VERSION ""

NS_ :

BS_:

BU_: Turbocharger OnBoardDataLogger OffBoardDiagnosticTool2 OffBoardDiagnosticTool1 FileServer ParkingBrakeController SeatControl2 FanDriveController SteeringColumnUnit CommunicationUnitRadio CommunicationUnitSatellite CommunicationUnitCellular PropulsionBatteryCharger ChassisController2 ChassisController1 EngineValveControl AuxiliaryHeater2 AuxiliaryHeater1 ClutchUnit RampControl InformationSystem1 SuspensionSystemController2 OilSensor VehicleDynamicStability ExhaustEmissionController TransmissionDisplay2 TransmissionDisplay1 ClimateControl2 WaterPumpController RearAxleSteeringController LightingOperatorControl SeatController1 IgnitionController2 IgnitionController1 TirePressureController CabController2 CabController1 PneumaticSystemController SuspensionSystemController1 HydraulicPumpController EnduranceBrakingSystem RetarderExhaustEngine2 OnBoardDiagnosticUnit HeadwayController RetarderExhaustEngine1 CabDisplay1 ManagementComputer VirtualTerminal OffVehicleGateway PowerTakeOffFront HitchControl AuxiliaryValveControl BodyController TractorTrailerBridge1 StarterSystem ElectricalSystem VehicleSecurity VehicleNavigation AerodynamicControl ElectricalChargingSystem ClimateControl1 TripRecorder InstrumentCluster SuspensionDriveAxle2 SuspensionDriveAxle1 SuspensionSteerAxle SteeringController FuelSystem CruiseControl RetarderDriveline RetarderEngine BrakesDriveAxle2 BrakesDriveAxle1 BrakesSystemController BrakesSteerAxle AxleDrive2 AxleDrive1 AxleSteering PowerTakeOff ShiftConsoleSecondary ShiftConsolePrimary Transmission2 Transmission1 Engine2 Engine1

BO_ 2566844705 CCVS_SA_21: 8 Vector__XXX
 SG_ ParkBrakeReleaseInhibitRq : 6|2@1+ (1,0) [0|3] "" Vector__XXX
 SG_ PTOGovernorState : 48|5@1+ (1,0) [0|31] "" Vector__XXX
 SG_ EngShutdownOverrideSwitch : 62|2@1+ (1,0) [0|3] "" Vector__XXX
 SG_ EngTestModeSwitch : 60|2@1+ (1,0) [0|3] "" Vector__XXX
 SG_ EngIdleDecrementSwitch : 58|2@1+ (1,0) [0|3] "" Vector__XXX
 SG_ EngIdleIncrementSwitch : 56|2@1+ (1,0) [0|3] "" Vector__XXX
 SG_ CruiseCtrlStates : 53|3@1+ (1,0) [0|7] "" Vector__XXX
 SG_ CruiseCtrlSetSpeed : 40|8@1+ (1,0) [0|250] "km/h" Vector__XXX
 SG_ CruiseCtrlAccelerateSwitch : 38|2@1+ (1,0) [0|3] "" Vector__XXX
 SG_ CruiseCtrlResumeSwitch : 36|2@1+ (1,0) [0|3] "" Vector__XXX
 SG_ CruiseCtrlCoastSwitch : 34|2@1+ (1,0) [0|3] "" Vector__XXX
 SG_ CruiseCtrlSetSwitch : 32|2@1+ (1,0) [0|3] "" Vector__XXX
 SG_ ClutchSwitch : 30|2@1+ (1,0) [0|3] "" Vector__XXX
 SG_ BrakeSwitch_SA21 : 28|2@1+ (1,0) [0|3] "" Vector__XXX
 SG_ CruiseCtrlEnableSwitch : 26|2@1+ (1,0) [0|3] "" Vector__XXX
 SG_ CruiseCtrlActive : 24|2@1+ (1,0) [0|3] "" Vector__XXX
 SG_ WheelBasedVehicleSpeed : 8|16@1+ (0.00390625,0) [0|250.996] "km/h" Vector__XXX
 SG_ CruiseCtrlPauseSwitch : 4|2@1+ (1,0) [0|3] "" Vector__XXX
 SG_ ParkingBrakeSwitch : 2|2@1+ (1,0) [0|3] "" Vector__XXX
 SG_ TwoSpeedAxleSwitch : 0|2@1+ (1,0) [0|3] "" Vector__XXX

BO_ 2566844695 CCVS_SA_17: 8 Vector__XXX
 SG_ ParkBrakeReleaseInhibitRq : 6|2@1+ (1,0) [0|3] "" Vector__XXX
 SG_ PTOGovernorState : 48|5@1+ (1,0) [0|31] "" Vector__XXX
 SG_ EngShutdownOverrideSwitch : 62|2@1+ (1,0) [0|3] "" Vector__XXX
 SG_ EngTestModeSwitch : 60|2@1+ (1,0) [0|3] "" Vector__XXX
 SG_ EngIdleDecrementSwitch : 58|2@1+ (1,0) [0|3] "" Vector__XXX
 SG_ EngIdleIncrementSwitch : 56|2@1+ (1,0) [0|3] "" Vector__XXX
 SG_ CruiseCtrlStates : 53|3@1+ (1,0) [0|7] "" Vector__XXX
 SG_ CruiseCtrlSetSpeed : 40|8@1+ (1,0) [0|250] "km/h" Vector__XXX
 SG_ CruiseCtrlAccelerateSwitch : 38|2@1+ (1,0) [0|3] "" Vector__XXX
 SG_ CruiseCtrlResumeSwitch : 36|2@1+ (1,0) [0|3] "" Vector__XXX
 SG_ CruiseCtrlCoastSwitch : 34|2@1+ (1,0) [0|3] "" Vector__XXX
 SG_ CruiseCtrlSetSwitch : 32|2@1+ (1,0) [0|3] "" Vector__XXX
 SG_ ClutchSwitch : 30|2@1+ (1,0) [0|3] "" Vector__XXX
 SG_ BrakeSwitch_SA17 : 28|2@1+ (1,0) [0|3] "" Vector__XXX
 SG_ CruiseCtrlEnableSwitch : 26|2@1+ (1,0) [0|3] "" Vector__XXX
 SG_ CruiseCtrlActive : 24|2@1+ (1,0) [0|3] "" Vector__XXX
 SG_ WheelBasedVehicleSpeed : 8|16@1+ (0.00390625,0) [0|250.996] "km/h" Vector__XXX
 SG_ CruiseCtrlPauseSwitch : 4|2@1+ (1,0) [0|3] "" Vector__XXX
 SG_ ParkingBrakeSwitch : 2|2@1+ (1,0) [0|3] "" Vector__XXX
 SG_ TwoSpeedAxleSwitch : 0|2@1+ (1,0) [0|3] "" Vector__XXX

BO_ 2566844689 CCVS_SA_11: 8 Vector__XXX
 SG_ ParkBrakeReleaseInhibitRq : 6|2@1+ (1,0) [0|3] "" Vector__XXX
 SG_ PTOGovernorState : 48|5@1+ (1,0) [0|31] "" Vector__XXX
 SG_ EngShutdownOverrideSwitch : 62|2@1+ (1,0) [0|3] "" Vector__XXX
 SG_ EngTestModeSwitch : 60|2@1+ (1,0) [0|3] "" Vector__XXX
 SG_ EngIdleDecrementSwitch : 58|2@1+ (1,0) [0|3] "" Vector__XXX
 SG_ EngIdleIncrementSwitch : 56|2@1+ (1,0) [0|3] "" Vector__XXX
 SG_ CruiseCtrlStates : 53|3@1+ (1,0) [0|7] "" Vector__XXX
 SG_ CruiseCtrlSetSpeed : 40|8@1+ (1,0) [0|250] "km/h" Vector__XXX
 SG_ CruiseCtrlAccelerateSwitch : 38|2@1+ (1,0) [0|3] "" Vector__XXX
 SG_ CruiseCtrlResumeSwitch : 36|2@1+ (1,0) [0|3] "" Vector__XXX
 SG_ CruiseCtrlCoastSwitch : 34|2@1+ (1,0) [0|3] "" Vector__XXX
 SG_ CruiseCtrlSetSwitch : 32|2@1+ (1,0) [0|3] "" Vector__XXX
 SG_ ClutchSwitch : 30|2@1+ (1,0) [0|3] "" Vector__XXX
 SG_ BrakeSwitch_SA11 : 28|2@1+ (1,0) [0|3] "" Vector__XXX
 SG_ CruiseCtrlEnableSwitch : 26|2@1+ (1,0) [0|3] "" Vector__XXX
 SG_ CruiseCtrlActive : 24|2@1+ (1,0) [0|3] "" Vector__XXX
 SG_ WheelBasedVehicleSpeed : 8|16@1+ (0.00390625,0) [0|250.996] "km/h" Vector__XXX
 SG_ CruiseCtrlPauseSwitch : 4|2@1+ (1,0) [0|3] "" Vector__XXX
 SG_ ParkingBrakeSwitch : 2|2@1+ (1,0) [0|3] "" Vector__XXX
 SG_ TwoSpeedAxleSwitch : 0|2@1+ (1,0) [0|3] "" Vector__XXX

BO_ 2566844683 CCVS_SA_0B: 8 Vector__XXX
 SG_ ParkBrakeReleaseInhibitRq : 6|2@1+ (1,0) [0|3] "" Vector__XXX
 SG_ PTOGovernorState : 48|5@1+ (1,0) [0|31] "" Vector__XXX
 SG_ EngShutdownOverrideSwitch : 62|2@1+ (1,0) [0|3] "" Vector__XXX
 SG_ EngTestModeSwitch : 60|2@1+ (1,0) [0|3] "" Vector__XXX
 SG_ EngIdleDecrementSwitch : 58|2@1+ (1,0) [0|3] "" Vector__XXX
 SG_ EngIdleIncrementSwitch : 56|2@1+ (1,0) [0|3] "" Vector__XXX
 SG_ CruiseCtrlStates : 53|3@1+ (1,0) [0|7] "" Vector__XXX
 SG_ CruiseCtrlSetSpeed : 40|8@1+ (1,0) [0|250] "km/h" Vector__XXX
 SG_ CruiseCtrlAccelerateSwitch : 38|2@1+ (1,0) [0|3] "" Vector__XXX
 SG_ CruiseCtrlResumeSwitch : 36|2@1+ (1,0) [0|3] "" Vector__XXX
 SG_ CruiseCtrlCoastSwitch : 34|2@1+ (1,0) [0|3] "" Vector__XXX
 SG_ CruiseCtrlSetSwitch : 32|2@1+ (1,0) [0|3] "" Vector__XXX
 SG_ ClutchSwitch : 30|2@1+ (1,0) [0|3] "" Vector__XXX
 SG_ BrakeSwitch_SA0B : 28|2@1+ (1,0) [0|3] "" Vector__XXX
 SG_ CruiseCtrlEnableSwitch : 26|2@1+ (1,0) [0|3] "" Vector__XXX
 SG_ CruiseCtrlActive : 24|2@1+ (1,0) [0|3] "" Vector__XXX
 SG_ WheelBasedVehicleSpeed : 8|16@1+ (0.00390625,0) [0|250.996] "km/h" Vector__XXX
 SG_ CruiseCtrlPauseSwitch : 4|2@1+ (1,0) [0|3] "" Vector__XXX
 SG_ ParkingBrakeSwitch : 2|2@1+ (1,0) [0|3] "" Vector__XXX
 SG_ TwoSpeedAxleSwitch : 0|2@1+ (1,0) [0|3] "" Vector__XXX

BO_ 2566844672 CCVS_SA_00: 8 Vector__XXX
 SG_ ParkBrakeReleaseInhibitRq : 6|2@1+ (1,0) [0|3] "" Vector__XXX
 SG_ PTOGovernorState : 48|5@1+ (1,0) [0|31] "" Vector__XXX
 SG_ EngShutdownOverrideSwitch : 62|2@1+ (1,0) [0|3] "" Vector__XXX
 SG_ EngTestModeSwitch : 60|2@1+ (1,0) [0|3] "" Vector__XXX
 SG_ EngIdleDecrementSwitch : 58|2@1+ (1,0) [0|3] "" Vector__XXX
 SG_ EngIdleIncrementSwitch : 56|2@1+ (1,0) [0|3] "" Vector__XXX
 SG_ CruiseCtrlStates : 53|3@1+ (1,0) [0|7] "" Vector__XXX
 SG_ CruiseCtrlSetSpeed : 40|8@1+ (1,0) [0|250] "km/h" Vector__XXX
 SG_ CruiseCtrlAccelerateSwitch : 38|2@1+ (1,0) [0|3] "" Vector__XXX
 SG_ CruiseCtrlResumeSwitch : 36|2@1+ (1,0) [0|3] "" Vector__XXX
 SG_ CruiseCtrlCoastSwitch : 34|2@1+ (1,0) [0|3] "" Vector__XXX
 SG_ CruiseCtrlSetSwitch : 32|2@1+ (1,0) [0|3] "" Vector__XXX
 SG_ ClutchSwitch : 30|2@1+ (1,0) [0|3] "" Vector__XXX
 SG_ BrakeSwitch_SA00 : 28|2@1+ (1,0) [0|3] "" Vector__XXX
 SG_ CruiseCtrlEnableSwitch : 26|2@1+ (1,0) [0|3] "" Vector__XXX
 SG_ CruiseCtrlActive : 24|2@1+ (1,0) [0|3] "" Vector__XXX
 SG_ WheelBasedVehicleSpeed : 8|16@1+ (0.00390625,0) [0|250.996] "km/h" Vector__XXX
 SG_ CruiseCtrlPauseSwitch : 4|2@1+ (1,0) [0|3] "" Vector__XXX
 SG_ ParkingBrakeSwitch : 2|2@1+ (1,0) [0|3] "" Vector__XXX
 SG_ TwoSpeedAxleSwitch : 0|2@1+ (1,0) [0|3] "" Vector__XXX

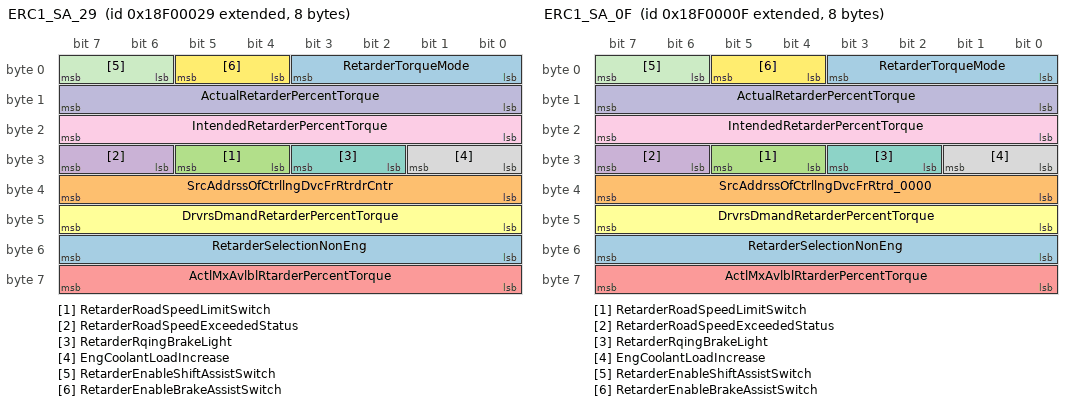
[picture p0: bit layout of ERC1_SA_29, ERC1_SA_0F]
BO_ 2565865513 ERC1_SA_29: 8 Vector__XXX
 SG_ RetarderSelectionNonEng : 48|8@1+ (0.4,0) [0|100] "%" Vector__XXX
 SG_ SrcAddrssOfCtrllngDvcFrRtrdrCntr : 32|8@1+ (1,0) [0|255] "" Vector__XXX
 SG_ RetarderRoadSpeedLimitSwitch : 28|2@1+ (1,0) [0|3] "" Vector__XXX
 SG_ RetarderRoadSpeedExceededStatus : 30|2@1+ (1,0) [0|3] "" Vector__XXX
 SG_ ActlMxAvlblRtarderPercentTorque : 56|8@1+ (1,-125) [-125|125] "%" Vector__XXX
 SG_ DrvrsDmandRetarderPercentTorque : 40|8@1+ (1,-125) [-125|125] "%" Vector__XXX
 SG_ RetarderRqingBrakeLight : 26|2@1+ (1,0) [0|3] "" Vector__XXX
 SG_ EngCoolantLoadIncrease : 24|2@1+ (1,0) [0|3] "" Vector__XXX
 SG_ IntendedRetarderPercentTorque : 16|8@1+ (1,-125) [-125|125] "%" Vector__XXX
 SG_ ActualRetarderPercentTorque : 8|8@1+ (1,-125) [-125|125] "%" Vector__XXX
 SG_ RetarderEnableShiftAssistSwitch : 6|2@1+ (1,0) [0|3] "" Vector__XXX
 SG_ RetarderEnableBrakeAssistSwitch : 4|2@1+ (1,0) [0|3] "" Vector__XXX
 SG_ RetarderTorqueMode : 0|4@1+ (1,0) [0|15] "" Vector__XXX

BO_ 2565865487 ERC1_SA_0F: 8 Vector__XXX
 SG_ RetarderSelectionNonEng : 48|8@1+ (0.4,0) [0|100] "%" Vector__XXX
 SG_ SrcAddrssOfCtrllngDvcFrRtrd_0000 : 32|8@1+ (1,0) [0|255] "" Vector__XXX
 SG_ RetarderRoadSpeedLimitSwitch : 28|2@1+ (1,0) [0|3] "" Vector__XXX
 SG_ RetarderRoadSpeedExceededStatus : 30|2@1+ (1,0) [0|3] "" Vector__XXX
 SG_ ActlMxAvlblRtarderPercentTorque : 56|8@1+ (1,-125) [-125|125] "%" Vector__XXX
 SG_ DrvrsDmandRetarderPercentTorque : 40|8@1+ (1,-125) [-125|125] "%" Vector__XXX
 SG_ RetarderRqingBrakeLight : 26|2@1+ (1,0) [0|3] "" Vector__XXX
 SG_ EngCoolantLoadIncrease : 24|2@1+ (1,0) [0|3] "" Vector__XXX
 SG_ IntendedRetarderPercentTorque : 16|8@1+ (1,-125) [-125|125] "%" Vector__XXX
 SG_ ActualRetarderPercentTorque : 8|8@1+ (1,-125) [-125|125] "%" Vector__XXX
 SG_ RetarderEnableShiftAssistSwitch : 6|2@1+ (1,0) [0|3] "" Vector__XXX
 SG_ RetarderEnableBrakeAssistSwitch : 4|2@1+ (1,0) [0|3] "" Vector__XXX
 SG_ RetarderTorqueMode : 0|4@1+ (1,0) [0|15] "" Vector__XXX

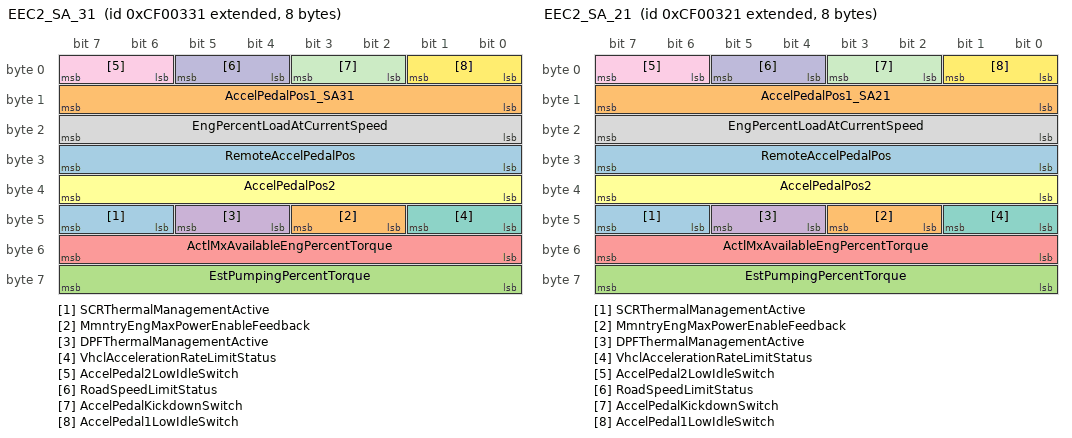
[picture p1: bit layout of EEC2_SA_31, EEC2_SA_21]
BO_ 2364539697 EEC2_SA_31: 8 Vector__XXX
 SG_ SCRThermalManagementActive : 46|2@1+ (1,0) [0|3] "" Vector__XXX
 SG_ MmntryEngMaxPowerEnableFeedback : 42|2@1+ (1,0) [0|3] "" Vector__XXX
 SG_ EstPumpingPercentTorque : 56|8@1+ (1,-125) [-125|125] "%" Vector__XXX
 SG_ DPFThermalManagementActive : 44|2@1+ (1,0) [0|3] "" Vector__XXX
 SG_ ActlMxAvailableEngPercentTorque : 48|8@1+ (0.4,0) [0|100] "%" Vector__XXX
 SG_ AccelPedalPos2 : 32|8@1+ (0.4,0) [0|100] "%" Vector__XXX
 SG_ VhclAccelerationRateLimitStatus : 40|2@1+ (1,0) [0|3] "" Vector__XXX
 SG_ EngPercentLoadAtCurrentSpeed : 16|8@1+ (1,0) [0|250] "%" Vector__XXX
 SG_ AccelPedal2LowIdleSwitch : 6|2@1+ (1,0) [0|3] "" Vector__XXX
 SG_ RoadSpeedLimitStatus : 4|2@1+ (1,0) [0|3] "" Vector__XXX
 SG_ AccelPedalKickdownSwitch : 2|2@1+ (1,0) [0|3] "" Vector__XXX
 SG_ AccelPedal1LowIdleSwitch : 0|2@1+ (1,0) [0|3] "" Vector__XXX
 SG_ RemoteAccelPedalPos : 24|8@1+ (0.4,0) [0|100] "%" Vector__XXX
 SG_ AccelPedalPos1_SA31 : 8|8@1+ (0.4,0) [0|100] "%" Vector__XXX

BO_ 2364539681 EEC2_SA_21: 8 Vector__XXX
 SG_ SCRThermalManagementActive : 46|2@1+ (1,0) [0|3] "" Vector__XXX
 SG_ MmntryEngMaxPowerEnableFeedback : 42|2@1+ (1,0) [0|3] "" Vector__XXX
 SG_ EstPumpingPercentTorque : 56|8@1+ (1,-125) [-125|125] "%" Vector__XXX
 SG_ DPFThermalManagementActive : 44|2@1+ (1,0) [0|3] "" Vector__XXX
 SG_ ActlMxAvailableEngPercentTorque : 48|8@1+ (0.4,0) [0|100] "%" Vector__XXX
 SG_ AccelPedalPos2 : 32|8@1+ (0.4,0) [0|100] "%" Vector__XXX
 SG_ VhclAccelerationRateLimitStatus : 40|2@1+ (1,0) [0|3] "" Vector__XXX
 SG_ EngPercentLoadAtCurrentSpeed : 16|8@1+ (1,0) [0|250] "%" Vector__XXX
 SG_ AccelPedal2LowIdleSwitch : 6|2@1+ (1,0) [0|3] "" Vector__XXX
 SG_ RoadSpeedLimitStatus : 4|2@1+ (1,0) [0|3] "" Vector__XXX
 SG_ AccelPedalKickdownSwitch : 2|2@1+ (1,0) [0|3] "" Vector__XXX
 SG_ AccelPedal1LowIdleSwitch : 0|2@1+ (1,0) [0|3] "" Vector__XXX
 SG_ RemoteAccelPedalPos : 24|8@1+ (0.4,0) [0|100] "%" Vector__XXX
 SG_ AccelPedalPos1_SA21 : 8|8@1+ (0.4,0) [0|100] "%" Vector__XXX

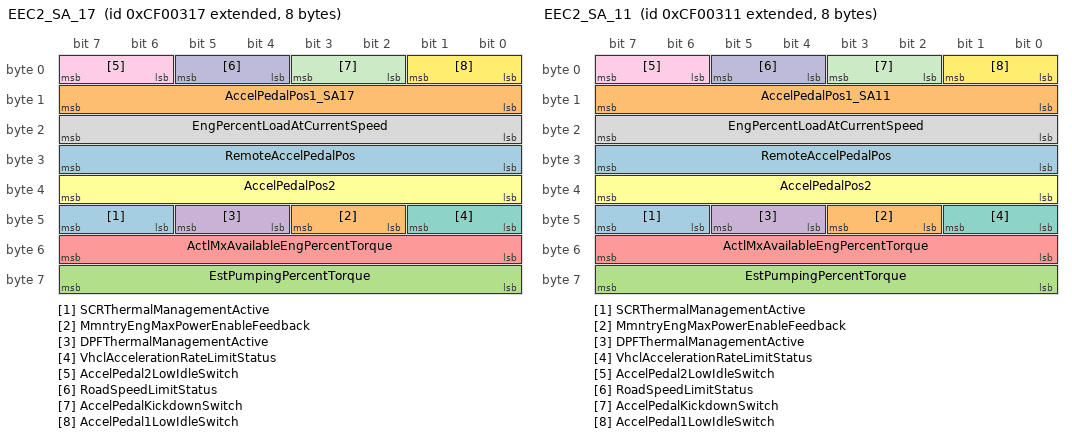
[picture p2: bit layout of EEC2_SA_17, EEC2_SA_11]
BO_ 2364539671 EEC2_SA_17: 8 Vector__XXX
 SG_ SCRThermalManagementActive : 46|2@1+ (1,0) [0|3] "" Vector__XXX
 SG_ MmntryEngMaxPowerEnableFeedback : 42|2@1+ (1,0) [0|3] "" Vector__XXX
 SG_ EstPumpingPercentTorque : 56|8@1+ (1,-125) [-125|125] "%" Vector__XXX
 SG_ DPFThermalManagementActive : 44|2@1+ (1,0) [0|3] "" Vector__XXX
 SG_ ActlMxAvailableEngPercentTorque : 48|8@1+ (0.4,0) [0|100] "%" Vector__XXX
 SG_ AccelPedalPos2 : 32|8@1+ (0.4,0) [0|100] "%" Vector__XXX
 SG_ VhclAccelerationRateLimitStatus : 40|2@1+ (1,0) [0|3] "" Vector__XXX
 SG_ EngPercentLoadAtCurrentSpeed : 16|8@1+ (1,0) [0|250] "%" Vector__XXX
 SG_ AccelPedal2LowIdleSwitch : 6|2@1+ (1,0) [0|3] "" Vector__XXX
 SG_ RoadSpeedLimitStatus : 4|2@1+ (1,0) [0|3] "" Vector__XXX
 SG_ AccelPedalKickdownSwitch : 2|2@1+ (1,0) [0|3] "" Vector__XXX
 SG_ AccelPedal1LowIdleSwitch : 0|2@1+ (1,0) [0|3] "" Vector__XXX
 SG_ RemoteAccelPedalPos : 24|8@1+ (0.4,0) [0|100] "%" Vector__XXX
 SG_ AccelPedalPos1_SA17 : 8|8@1+ (0.4,0) [0|100] "%" Vector__XXX

BO_ 2364539665 EEC2_SA_11: 8 Vector__XXX
 SG_ SCRThermalManagementActive : 46|2@1+ (1,0) [0|3] "" Vector__XXX
 SG_ MmntryEngMaxPowerEnableFeedback : 42|2@1+ (1,0) [0|3] "" Vector__XXX
 SG_ EstPumpingPercentTorque : 56|8@1+ (1,-125) [-125|125] "%" Vector__XXX
 SG_ DPFThermalManagementActive : 44|2@1+ (1,0) [0|3] "" Vector__XXX
 SG_ ActlMxAvailableEngPercentTorque : 48|8@1+ (0.4,0) [0|100] "%" Vector__XXX
 SG_ AccelPedalPos2 : 32|8@1+ (0.4,0) [0|100] "%" Vector__XXX
 SG_ VhclAccelerationRateLimitStatus : 40|2@1+ (1,0) [0|3] "" Vector__XXX
 SG_ EngPercentLoadAtCurrentSpeed : 16|8@1+ (1,0) [0|250] "%" Vector__XXX
 SG_ AccelPedal2LowIdleSwitch : 6|2@1+ (1,0) [0|3] "" Vector__XXX
 SG_ RoadSpeedLimitStatus : 4|2@1+ (1,0) [0|3] "" Vector__XXX
 SG_ AccelPedalKickdownSwitch : 2|2@1+ (1,0) [0|3] "" Vector__XXX
 SG_ AccelPedal1LowIdleSwitch : 0|2@1+ (1,0) [0|3] "" Vector__XXX
 SG_ RemoteAccelPedalPos : 24|8@1+ (0.4,0) [0|100] "%" Vector__XXX
 SG_ AccelPedalPos1_SA11 : 8|8@1+ (0.4,0) [0|100] "%" Vector__XXX

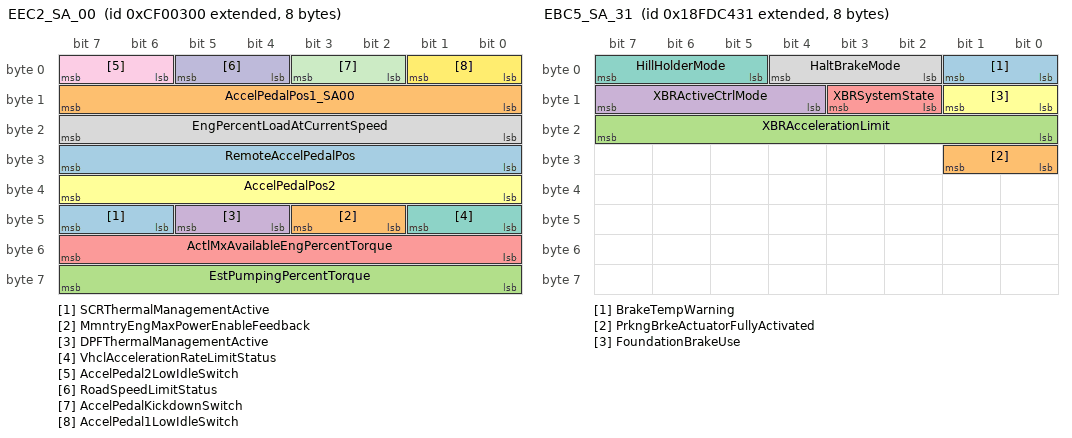
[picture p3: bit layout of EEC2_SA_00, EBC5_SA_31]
BO_ 2364539648 EEC2_SA_00: 8 Vector__XXX
 SG_ SCRThermalManagementActive : 46|2@1+ (1,0) [0|3] "" Vector__XXX
 SG_ MmntryEngMaxPowerEnableFeedback : 42|2@1+ (1,0) [0|3] "" Vector__XXX
 SG_ EstPumpingPercentTorque : 56|8@1+ (1,-125) [-125|125] "%" Vector__XXX
 SG_ DPFThermalManagementActive : 44|2@1+ (1,0) [0|3] "" Vector__XXX
 SG_ ActlMxAvailableEngPercentTorque : 48|8@1+ (0.4,0) [0|100] "%" Vector__XXX
 SG_ AccelPedalPos2 : 32|8@1+ (0.4,0) [0|100] "%" Vector__XXX
 SG_ VhclAccelerationRateLimitStatus : 40|2@1+ (1,0) [0|3] "" Vector__XXX
 SG_ EngPercentLoadAtCurrentSpeed : 16|8@1+ (1,0) [0|250] "%" Vector__XXX
 SG_ AccelPedal2LowIdleSwitch : 6|2@1+ (1,0) [0|3] "" Vector__XXX
 SG_ RoadSpeedLimitStatus : 4|2@1+ (1,0) [0|3] "" Vector__XXX
 SG_ AccelPedalKickdownSwitch : 2|2@1+ (1,0) [0|3] "" Vector__XXX
 SG_ AccelPedal1LowIdleSwitch : 0|2@1+ (1,0) [0|3] "" Vector__XXX
 SG_ RemoteAccelPedalPos : 24|8@1+ (0.4,0) [0|100] "%" Vector__XXX
 SG_ AccelPedalPos1_SA00 : 8|8@1+ (0.4,0) [0|100] "%" Vector__XXX

BO_ 2566767665 EBC5_SA_31: 8 Vector__XXX
 SG_ BrakeTempWarning : 0|2@1+ (1,0) [0|3] "" Vector__XXX
 SG_ PrkngBrkeActuatorFullyActivated : 24|2@1+ (1,0) [0|3] "" Vector__XXX
 SG_ XBRAccelerationLimit : 16|8@1+ (0.1,-12.5) [-12.5|12.5] "m/s²" Vector__XXX
 SG_ XBRActiveCtrlMode : 12|4@1+ (1,0) [0|15] "" Vector__XXX
 SG_ XBRSystemState : 10|2@1+ (1,0) [0|3] "" Vector__XXX
 SG_ FoundationBrakeUse : 8|2@1+ (1,0) [0|3] "" Vector__XXX
 SG_ HillHolderMode : 5|3@1+ (1,0) [0|7] "" Vector__XXX
 SG_ HaltBrakeMode : 2|3@1+ (1,0) [0|7] "" Vector__XXX

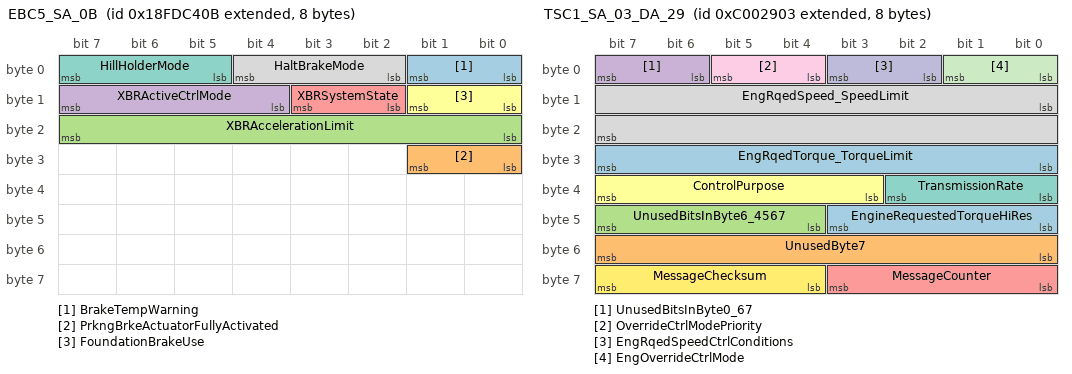
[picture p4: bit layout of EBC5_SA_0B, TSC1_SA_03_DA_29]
BO_ 2566767627 EBC5_SA_0B: 8 Vector__XXX
 SG_ BrakeTempWarning : 0|2@1+ (1,0) [0|3] "" Vector__XXX
 SG_ PrkngBrkeActuatorFullyActivated : 24|2@1+ (1,0) [0|3] "" Vector__XXX
 SG_ XBRAccelerationLimit : 16|8@1+ (0.1,-12.5) [-12.5|12.5] "m/s²" Vector__XXX
 SG_ XBRActiveCtrlMode : 12|4@1+ (1,0) [0|15] "" Vector__XXX
 SG_ XBRSystemState : 10|2@1+ (1,0) [0|3] "" Vector__XXX
 SG_ FoundationBrakeUse : 8|2@1+ (1,0) [0|3] "" Vector__XXX
 SG_ HillHolderMode : 5|3@1+ (1,0) [0|7] "" Vector__XXX
 SG_ HaltBrakeMode : 2|3@1+ (1,0) [0|7] "" Vector__XXX

BO_ 2565865777 EBC1_SA_31: 8 Vector__XXX
 SG_ EngAuxShutdownSwitch : 28|2@1+ (1,0) [0|3] "" Vector__XXX
 SG_ SrcAddrssOfCtrllngDvcFrBrkCntrl : 48|8@1+ (1,0) [0|255] "" Vector__XXX
 SG_ BrakePedalPos : 8|8@1+ (0.4,0) [0|100] "%" Vector__XXX
 SG_ TrctrMntdTrilerABSWarningSignal : 62|2@1+ (1,0) [0|3] "" Vector__XXX
 SG_ TrailerABSStatus : 60|2@1+ (1,0) [0|3] "" Vector__XXX
 SG_ HaltBrakeSwitch : 58|2@1+ (1,0) [0|3] "" Vector__XXX
 SG_ ATC_ASRInformationSignal : 46|2@1+ (1,0) [0|3] "" Vector__XXX
 SG_ ABS_EBSAmberWarningSignal : 44|2@1+ (1,0) [0|3] "" Vector__XXX
 SG_ EBSRedWarningSignal : 42|2@1+ (1,0) [0|3] "" Vector__XXX
 SG_ ABSFullyOperational : 40|2@1+ (1,0) [0|3] "" Vector__XXX
 SG_ EngRetarderSelection : 32|8@1+ (0.4,0) [0|100] "%" Vector__XXX
 SG_ RemoteAccelEnableSwitch : 30|2@1+ (1,0) [0|3] "" Vector__XXX
 SG_ EngDerateSwitch : 26|2@1+ (1,0) [0|3] "" Vector__XXX
 SG_ AccelInterlockSwitch : 24|2@1+ (1,0) [0|3] "" Vector__XXX
 SG_ TractionCtrlOverrideSwitch : 22|2@1+ (1,0) [0|3] "" Vector__XXX
 SG_ ASRHillHolderSwitch : 20|2@1+ (1,0) [0|3] "" Vector__XXX
 SG_ ASROffroadSwitch : 18|2@1+ (1,0) [0|3] "" Vector__XXX
 SG_ ABSOffroadSwitch : 16|2@1+ (1,0) [0|3] "" Vector__XXX
 SG_ EBSBrakeSwitch : 6|2@1+ (1,0) [0|3] "" Vector__XXX
 SG_ AntiLockBrakingActive : 4|2@1+ (1,0) [0|3] "" Vector__XXX
 SG_ ASRBrakeCtrlActive : 2|2@1+ (1,0) [0|3] "" Vector__XXX
 SG_ ASREngCtrlActive : 0|2@1+ (1,0) [0|3] "" Vector__XXX

BO_ 2565865761 EBC1_SA_21: 8 Vector__XXX
 SG_ EngAuxShutdownSwitch : 28|2@1+ (1,0) [0|3] "" Vector__XXX
 SG_ SrcAddrssOfCtrllngDvcFrBrkCntrl : 48|8@1+ (1,0) [0|255] "" Vector__XXX
 SG_ BrakePedalPos : 8|8@1+ (0.4,0) [0|100] "%" Vector__XXX
 SG_ TrctrMntdTrilerABSWarningSignal : 62|2@1+ (1,0) [0|3] "" Vector__XXX
 SG_ TrailerABSStatus : 60|2@1+ (1,0) [0|3] "" Vector__XXX
 SG_ HaltBrakeSwitch : 58|2@1+ (1,0) [0|3] "" Vector__XXX
 SG_ ATC_ASRInformationSignal : 46|2@1+ (1,0) [0|3] "" Vector__XXX
 SG_ ABS_EBSAmberWarningSignal : 44|2@1+ (1,0) [0|3] "" Vector__XXX
 SG_ EBSRedWarningSignal : 42|2@1+ (1,0) [0|3] "" Vector__XXX
 SG_ ABSFullyOperational : 40|2@1+ (1,0) [0|3] "" Vector__XXX
 SG_ EngRetarderSelection : 32|8@1+ (0.4,0) [0|100] "%" Vector__XXX
 SG_ RemoteAccelEnableSwitch : 30|2@1+ (1,0) [0|3] "" Vector__XXX
 SG_ EngDerateSwitch : 26|2@1+ (1,0) [0|3] "" Vector__XXX
 SG_ AccelInterlockSwitch : 24|2@1+ (1,0) [0|3] "" Vector__XXX
 SG_ TractionCtrlOverrideSwitch : 22|2@1+ (1,0) [0|3] "" Vector__XXX
 SG_ ASRHillHolderSwitch : 20|2@1+ (1,0) [0|3] "" Vector__XXX
 SG_ ASROffroadSwitch : 18|2@1+ (1,0) [0|3] "" Vector__XXX
 SG_ ABSOffroadSwitch : 16|2@1+ (1,0) [0|3] "" Vector__XXX
 SG_ EBSBrakeSwitch : 6|2@1+ (1,0) [0|3] "" Vector__XXX
 SG_ AntiLockBrakingActive : 4|2@1+ (1,0) [0|3] "" Vector__XXX
 SG_ ASRBrakeCtrlActive : 2|2@1+ (1,0) [0|3] "" Vector__XXX
 SG_ ASREngCtrlActive : 0|2@1+ (1,0) [0|3] "" Vector__XXX

BO_ 2565865739 EBC1_SA_0B: 8 Vector__XXX
 SG_ EngAuxShutdownSwitch : 28|2@1+ (1,0) [0|3] "" Vector__XXX
 SG_ SrcAddrssOfCtrllngDvcFrBrkCntrl : 48|8@1+ (1,0) [0|255] "" Vector__XXX
 SG_ BrakePedalPos : 8|8@1+ (0.4,0) [0|100] "%" Vector__XXX
 SG_ TrctrMntdTrilerABSWarningSignal : 62|2@1+ (1,0) [0|3] "" Vector__XXX
 SG_ TrailerABSStatus : 60|2@1+ (1,0) [0|3] "" Vector__XXX
 SG_ HaltBrakeSwitch : 58|2@1+ (1,0) [0|3] "" Vector__XXX
 SG_ ATC_ASRInformationSignal : 46|2@1+ (1,0) [0|3] "" Vector__XXX
 SG_ ABS_EBSAmberWarningSignal : 44|2@1+ (1,0) [0|3] "" Vector__XXX
 SG_ EBSRedWarningSignal : 42|2@1+ (1,0) [0|3] "" Vector__XXX
 SG_ ABSFullyOperational : 40|2@1+ (1,0) [0|3] "" Vector__XXX
 SG_ EngRetarderSelection : 32|8@1+ (0.4,0) [0|100] "%" Vector__XXX
 SG_ RemoteAccelEnableSwitch : 30|2@1+ (1,0) [0|3] "" Vector__XXX
 SG_ EngDerateSwitch : 26|2@1+ (1,0) [0|3] "" Vector__XXX
 SG_ AccelInterlockSwitch : 24|2@1+ (1,0) [0|3] "" Vector__XXX
 SG_ TractionCtrlOverrideSwitch : 22|2@1+ (1,0) [0|3] "" Vector__XXX
 SG_ ASRHillHolderSwitch : 20|2@1+ (1,0) [0|3] "" Vector__XXX
 SG_ ASROffroadSwitch : 18|2@1+ (1,0) [0|3] "" Vector__XXX
 SG_ ABSOffroadSwitch : 16|2@1+ (1,0) [0|3] "" Vector__XXX
 SG_ EBSBrakeSwitch : 6|2@1+ (1,0) [0|3] "" Vector__XXX
 SG_ AntiLockBrakingActive : 4|2@1+ (1,0) [0|3] "" Vector__XXX
 SG_ ASRBrakeCtrlActive : 2|2@1+ (1,0) [0|3] "" Vector__XXX
 SG_ ASREngCtrlActive : 0|2@1+ (1,0) [0|3] "" Vector__XXX

BO_ 2565865728 EBC1_SA_00: 8 Vector__XXX
 SG_ EngAuxShutdownSwitch : 28|2@1+ (1,0) [0|3] "" Vector__XXX
 SG_ SrcAddrssOfCtrllngDvcFrBrkCntrl : 48|8@1+ (1,0) [0|255] "" Vector__XXX
 SG_ BrakePedalPos : 8|8@1+ (0.4,0) [0|100] "%" Vector__XXX
 SG_ TrctrMntdTrilerABSWarningSignal : 62|2@1+ (1,0) [0|3] "" Vector__XXX
 SG_ TrailerABSStatus : 60|2@1+ (1,0) [0|3] "" Vector__XXX
 SG_ HaltBrakeSwitch : 58|2@1+ (1,0) [0|3] "" Vector__XXX
 SG_ ATC_ASRInformationSignal : 46|2@1+ (1,0) [0|3] "" Vector__XXX
 SG_ ABS_EBSAmberWarningSignal : 44|2@1+ (1,0) [0|3] "" Vector__XXX
 SG_ EBSRedWarningSignal : 42|2@1+ (1,0) [0|3] "" Vector__XXX
 SG_ ABSFullyOperational : 40|2@1+ (1,0) [0|3] "" Vector__XXX
 SG_ EngRetarderSelection : 32|8@1+ (0.4,0) [0|100] "%" Vector__XXX
 SG_ RemoteAccelEnableSwitch : 30|2@1+ (1,0) [0|3] "" Vector__XXX
 SG_ EngDerateSwitch : 26|2@1+ (1,0) [0|3] "" Vector__XXX
 SG_ AccelInterlockSwitch : 24|2@1+ (1,0) [0|3] "" Vector__XXX
 SG_ TractionCtrlOverrideSwitch : 22|2@1+ (1,0) [0|3] "" Vector__XXX
 SG_ ASRHillHolderSwitch : 20|2@1+ (1,0) [0|3] "" Vector__XXX
 SG_ ASROffroadSwitch : 18|2@1+ (1,0) [0|3] "" Vector__XXX
 SG_ ABSOffroadSwitch : 16|2@1+ (1,0) [0|3] "" Vector__XXX
 SG_ EBSBrakeSwitch : 6|2@1+ (1,0) [0|3] "" Vector__XXX
 SG_ AntiLockBrakingActive : 4|2@1+ (1,0) [0|3] "" Vector__XXX
 SG_ ASRBrakeCtrlActive : 2|2@1+ (1,0) [0|3] "" Vector__XXX
 SG_ ASREngCtrlActive : 0|2@1+ (1,0) [0|3] "" Vector__XXX

BO_ 2348820739 TSC1_SA_03_DA_29: 8 Vector__XXX
 SG_ EngRqedTorque_TorqueLimit : 24|8@1+ (1,-125) [-125|125] "%" Vector__XXX
 SG_ UnusedByte7 : 48|8@1+ (1,0) [0|0] "" Vector__XXX
 SG_ UnusedBitsInByte6_4567 : 44|4@1+ (1,0) [0|0] "" Vector__XXX
 SG_ UnusedBitsInByte0_67 : 6|2@1+ (1,0) [0|3] "" Vector__XXX
 SG_ MessageCounter : 56|4@1+ (1,0) [0|15] "" Vector__XXX
 SG_ ControlPurpose : 35|5@1+ (1,0) [0|31] "" Vector__XXX
 SG_ TransmissionRate : 32|3@1+ (1,0) [0|7] "" Vector__XXX
 SG_ EngRqedSpeed_SpeedLimit : 8|16@1+ (0.125,0) [0|8031.875] "rpm" Vector__XXX
 SG_ OverrideCtrlModePriority : 4|2@1+ (1,0) [0|3] "" Vector__XXX
 SG_ EngRqedSpeedCtrlConditions : 2|2@1+ (1,0) [0|3] "" Vector__XXX
 SG_ EngOverrideCtrlMode : 0|2@1+ (1,0) [0|3] "" Vector__XXX
 SG_ MessageChecksum : 60|4@1+ (1,0) [0|15] "" Vector__XXX
 SG_ EngineRequestedTorqueHiRes : 40|4@1+ (0.125,0) [0|0.875] "%" Vector__XXX

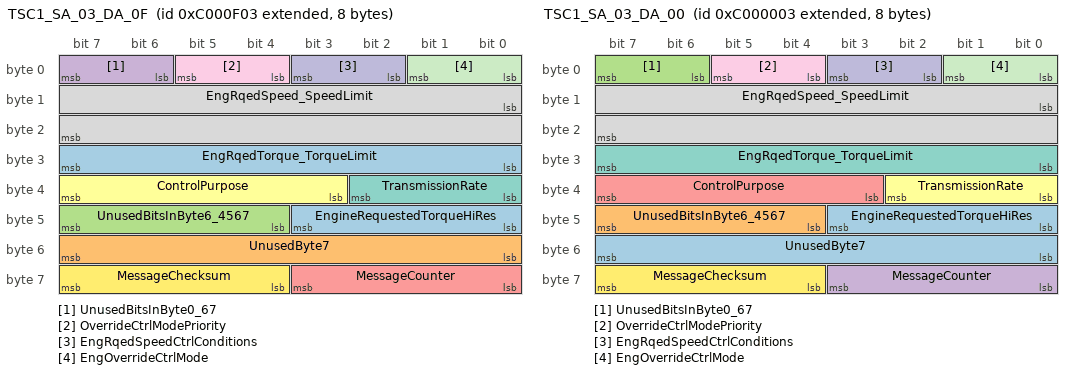
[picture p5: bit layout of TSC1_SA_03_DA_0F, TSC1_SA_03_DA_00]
BO_ 2348814083 TSC1_SA_03_DA_0F: 8 Vector__XXX
 SG_ EngRqedTorque_TorqueLimit : 24|8@1+ (1,-125) [-125|125] "%" Vector__XXX
 SG_ UnusedByte7 : 48|8@1+ (1,0) [0|0] "" Vector__XXX
 SG_ UnusedBitsInByte6_4567 : 44|4@1+ (1,0) [0|0] "" Vector__XXX
 SG_ UnusedBitsInByte0_67 : 6|2@1+ (1,0) [0|3] "" Vector__XXX
 SG_ MessageCounter : 56|4@1+ (1,0) [0|15] "" Vector__XXX
 SG_ ControlPurpose : 35|5@1+ (1,0) [0|31] "" Vector__XXX
 SG_ TransmissionRate : 32|3@1+ (1,0) [0|7] "" Vector__XXX
 SG_ EngRqedSpeed_SpeedLimit : 8|16@1+ (0.125,0) [0|8031.875] "rpm" Vector__XXX
 SG_ OverrideCtrlModePriority : 4|2@1+ (1,0) [0|3] "" Vector__XXX
 SG_ EngRqedSpeedCtrlConditions : 2|2@1+ (1,0) [0|3] "" Vector__XXX
 SG_ EngOverrideCtrlMode : 0|2@1+ (1,0) [0|3] "" Vector__XXX
 SG_ MessageChecksum : 60|4@1+ (1,0) [0|15] "" Vector__XXX
 SG_ EngineRequestedTorqueHiRes : 40|4@1+ (0.125,0) [0|0.875] "%" Vector__XXX

BO_ 2348810243 TSC1_SA_03_DA_00: 8 Vector__XXX
 SG_ UnusedByte7 : 48|8@1+ (1,0) [0|0] "" Vector__XXX
 SG_ UnusedBitsInByte6_4567 : 44|4@1+ (1,0) [0|0] "" Vector__XXX
 SG_ UnusedBitsInByte0_67 : 6|2@1+ (1,0) [0|3] "" Vector__XXX
 SG_ MessageCounter : 56|4@1+ (1,0) [0|15] "" Vector__XXX
 SG_ ControlPurpose : 35|5@1+ (1,0) [0|31] "" Vector__XXX
 SG_ TransmissionRate : 32|3@1+ (1,0) [0|7] "" Vector__XXX
 SG_ EngRqedTorque_TorqueLimit : 24|8@1+ (1,-125) [-125|125] "%" Vector__XXX
 SG_ EngRqedSpeed_SpeedLimit : 8|16@1+ (0.125,0) [0|8031.875] "rpm" Vector__XXX
 SG_ OverrideCtrlModePriority : 4|2@1+ (1,0) [0|3] "" Vector__XXX
 SG_ EngRqedSpeedCtrlConditions : 2|2@1+ (1,0) [0|3] "" Vector__XXX
 SG_ EngOverrideCtrlMode : 0|2@1+ (1,0) [0|3] "" Vector__XXX
 SG_ MessageChecksum : 60|4@1+ (1,0) [0|15] "" Vector__XXX
 SG_ EngineRequestedTorqueHiRes : 40|4@1+ (0.125,0) [0|0.875] "%" Vector__XXX

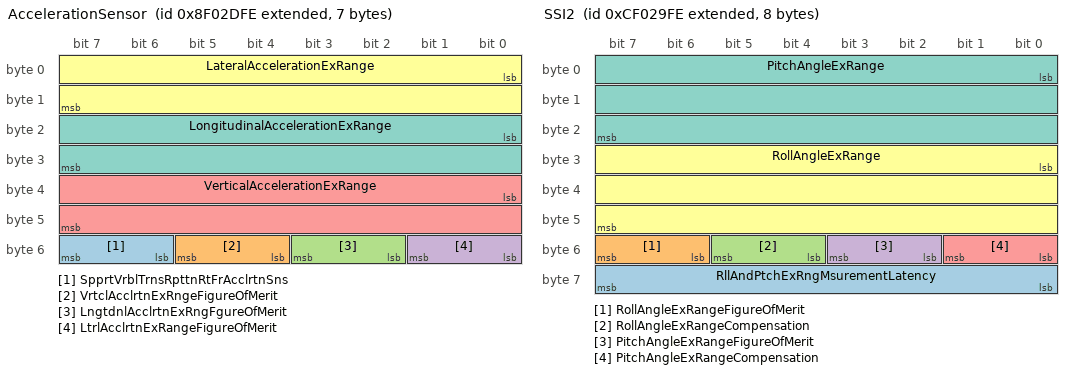
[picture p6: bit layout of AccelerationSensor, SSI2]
BO_ 2297441790 AccelerationSensor: 7 Vector__XXX
 SG_ SpprtVrblTrnsRpttnRtFrAcclrtnSns : 54|2@1+ (1,0) [0|3] "" Vector__XXX
 SG_ VrtclAcclrtnExRngeFigureOfMerit : 52|2@1+ (1,0) [0|3] "" Vector__XXX
 SG_ LngtdnlAcclrtnExRngFgureOfMerit : 50|2@1+ (1,0) [0|3] "" Vector__XXX
 SG_ LtrlAcclrtnExRangeFigureOfMerit : 48|2@1+ (1,0) [0|3] "" Vector__XXX
 SG_ VerticalAccelerationExRange : 32|16@1+ (0.01,-320) [-320|322.55] "m/s²" Vector__XXX
 SG_ LateralAccelerationExRange : 0|16@1+ (0.01,-320) [-320|322.55] "m/s²" Vector__XXX
 SG_ LongitudinalAccelerationExRange : 16|16@1+ (0.01,-320) [-320|322.55] "m/s²" Vector__XXX

BO_ 2566712062 VEP4: 8 Vector__XXX
 SG_ HybrdBatteryPackRemainingCharge : 0|16@1+ (0.0025,0) [0|160.6375] "%" Vector__XXX

BO_ 2364549630 SSI2: 8 Vector__XXX
 SG_ RllAndPtchExRngMsurementLatency : 56|8@1+ (0.5,0) [0|125] "ms" Vector__XXX
 SG_ RollAngleExRangeFigureOfMerit : 54|2@1+ (1,0) [0|3] "" Vector__XXX
 SG_ RollAngleExRangeCompensation : 52|2@1+ (1,0) [0|3] "" Vector__XXX
 SG_ PitchAngleExRangeFigureOfMerit : 50|2@1+ (1,0) [0|3] "" Vector__XXX
 SG_ PitchAngleExRangeCompensation : 48|2@1+ (1,0) [0|3] "" Vector__XXX
 SG_ RollAngleExRange : 24|24@1+ (3.0517578125E-005,-250) [-250|250.9999] "deg" Vector__XXX
 SG_ PitchAngleExRange : 0|24@1+ (3.0517578125E-005,-250) [-250|250.9999] "deg" Vector__XXX

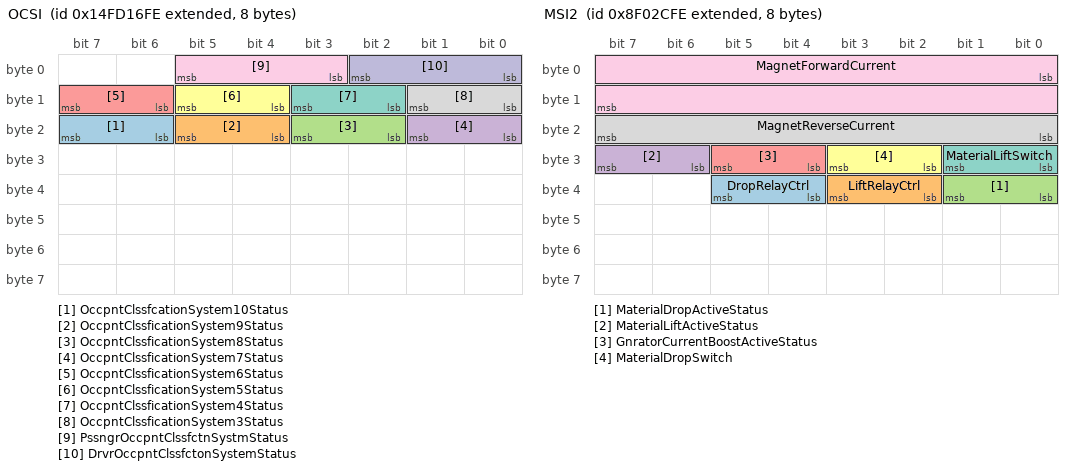
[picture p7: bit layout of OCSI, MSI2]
BO_ 2499614462 OCSI: 8 Vector__XXX
 SG_ OccpntClssfcationSystem10Status : 22|2@1+ (1,0) [0|3] "" Vector__XXX
 SG_ OccpntClssficationSystem9Status : 20|2@1+ (1,0) [0|3] "" Vector__XXX
 SG_ OccpntClssficationSystem8Status : 18|2@1+ (1,0) [0|3] "" Vector__XXX
 SG_ OccpntClssficationSystem7Status : 16|2@1+ (1,0) [0|3] "" Vector__XXX
 SG_ OccpntClssficationSystem6Status : 14|2@1+ (1,0) [0|3] "" Vector__XXX
 SG_ OccpntClssficationSystem5Status : 12|2@1+ (1,0) [0|3] "" Vector__XXX
 SG_ OccpntClssficationSystem4Status : 10|2@1+ (1,0) [0|3] "" Vector__XXX
 SG_ OccpntClssficationSystem3Status : 8|2@1+ (1,0) [0|3] "" Vector__XXX
 SG_ PssngrOccpntClssfctnSystmStatus : 3|3@1+ (1,0) [0|7] "" Vector__XXX
 SG_ DrvrOccpntClssfctonSystemStatus : 0|3@1+ (1,0) [0|7] "" Vector__XXX

BO_ 2560098046 NCS: 8 Vector__XXX
 SG_ CabNoiseCtrlTuningStatus : 2|4@1+ (1,0) [0|15] "" Vector__XXX
 SG_ CabNoiseCtrlStatus : 0|2@1+ (1,0) [0|3] "" Vector__XXX

BO_ 2560163582 NC1: 8 Vector__XXX
 SG_ CabNoiseCtrlTuningState : 2|3@1+ (1,0) [0|7] "" Vector__XXX
 SG_ CabNoiseCtrlState : 0|2@1+ (1,0) [0|3] "" Vector__XXX

BO_ 2297441534 MSI2: 8 Vector__XXX
 SG_ DropRelayCtrl : 36|2@1+ (1,0) [0|3] "" Vector__XXX
 SG_ LiftRelayCtrl : 34|2@1+ (1,0) [0|3] "" Vector__XXX
 SG_ MaterialDropActiveStatus : 32|2@1+ (1,0) [0|3] "" Vector__XXX
 SG_ MaterialLiftActiveStatus : 30|2@1+ (1,0) [0|3] "" Vector__XXX
 SG_ GnratorCurrentBoostActiveStatus : 28|2@1+ (1,0) [0|3] "" Vector__XXX
 SG_ MaterialDropSwitch : 26|2@1+ (1,0) [0|3] "" Vector__XXX
 SG_ MaterialLiftSwitch : 24|2@1+ (1,0) [0|3] "" Vector__XXX
 SG_ MagnetReverseCurrent : 16|8@1+ (1,0) [0|250] "A" Vector__XXX
 SG_ MagnetForwardCurrent : 0|16@1+ (1,0) [0|64255] "Amps" Vector__XXX

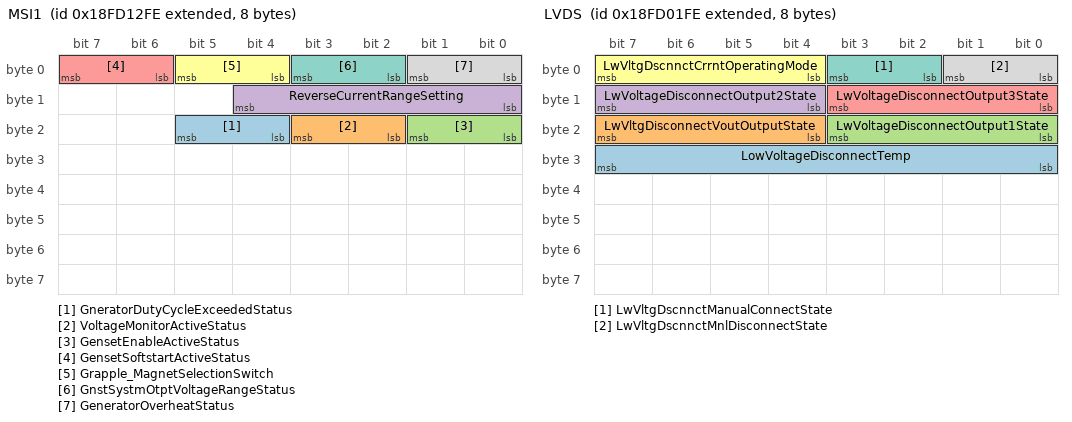
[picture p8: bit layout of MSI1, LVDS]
BO_ 2566722302 MSI1: 8 Vector__XXX
 SG_ GneratorDutyCycleExceededStatus : 20|2@1+ (1,0) [0|3] "" Vector__XXX
 SG_ VoltageMonitorActiveStatus : 18|2@1+ (1,0) [0|3] "" Vector__XXX
 SG_ GensetEnableActiveStatus : 16|2@1+ (1,0) [0|3] "" Vector__XXX
 SG_ ReverseCurrentRangeSetting : 8|5@1+ (1,0) [0|31] "" Vector__XXX
 SG_ GensetSoftstartActiveStatus : 6|2@1+ (1,0) [0|3] "" Vector__XXX
 SG_ Grapple_MagnetSelectionSwitch : 4|2@1+ (1,0) [0|3] "" Vector__XXX
 SG_ GnstSystmOtptVoltageRangeStatus : 2|2@1+ (1,0) [0|3] "" Vector__XXX
 SG_ GeneratorOverheatStatus : 0|2@1+ (1,0) [0|3] "" Vector__XXX

BO_ 2566722558 MSCI: 8 Vector__XXX
 SG_ MagnetRatedPower : 8|16@1+ (0.5,0) [0|32127.5] "kW" Vector__XXX
 SG_ MagnetBoostTime : 0|8@1+ (0.25,0) [0|62.5] "s" Vector__XXX

BO_ 2560032510 LVDSOM: 8 Vector__XXX
 SG_ LwVltgDscnnctDsredOperatingMode : 0|4@1+ (1,0) [0|15] "" Vector__XXX

BO_ 2566717950 LVDS: 8 Vector__XXX
 SG_ LowVoltageDisconnectTemp : 24|8@1+ (1,-40) [-40|210] "deg C" Vector__XXX
 SG_ LwVltgDisconnectVoutOutputState : 20|4@1+ (1,0) [0|15] "" Vector__XXX
 SG_ LwVoltageDisconnectOutput1State : 16|4@1+ (1,0) [0|15] "" Vector__XXX
 SG_ LwVoltageDisconnectOutput2State : 12|4@1+ (1,0) [0|15] "" Vector__XXX
 SG_ LwVoltageDisconnectOutput3State : 8|4@1+ (1,0) [0|15] "" Vector__XXX
 SG_ LwVltgDscnnctCrrntOperatingMode : 4|4@1+ (1,0) [0|15] "" Vector__XXX
 SG_ LwVltgDscnnctManualConnectState : 2|2@1+ (1,0) [0|3] "" Vector__XXX
 SG_ LwVltgDscnnctMnlDisconnectState : 0|2@1+ (1,0) [0|3] "" Vector__XXX

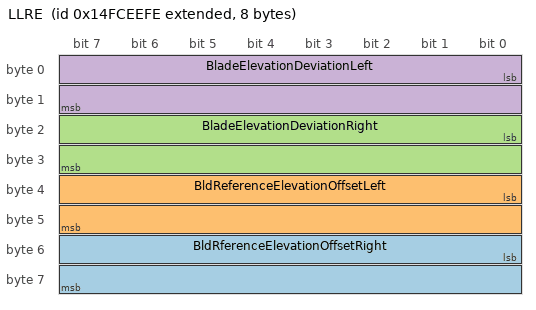
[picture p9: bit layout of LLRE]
BO_ 2499604222 LLRE: 8 Vector__XXX
 SG_ BldRferenceElevationOffsetRight : 48|16@1+ (1,-32000) [-32000|32255] "mm" Vector__XXX
 SG_ BldReferenceElevationOffsetLeft : 32|16@1+ (1,-32000) [-32000|32255] "mm" Vector__XXX
 SG_ BladeElevationDeviationRight : 16|16@1+ (1,-32000) [-32000|32255] "mm" Vector__XXX
 SG_ BladeElevationDeviationLeft : 0|16@1+ (1,-32000) [-32000|32255] "mm" Vector__XXX

BO_ 2358902526 JLCM: 8 Vector__XXX
 SG_ Joystick3Lamp10Cmd : 58|2@1+ (1,0) [0|3] "" Vector__XXX
 SG_ Joystick3Lamp9Cmd : 56|2@1+ (1,0) [0|3] "" Vector__XXX
 SG_ Joystick3Lamp8Cmd : 54|2@1+ (1,0) [0|3] "" Vector__XXX
 SG_ Joystick3Lamp7Cmd : 52|2@1+ (1,0) [0|3] "" Vector__XXX
 SG_ Joystick3Lamp6Cmd : 50|2@1+ (1,0) [0|3] "" Vector__XXX
 SG_ Joystick3Lamp5Cmd : 48|2@1+ (1,0) [0|3] "" Vector__XXX
 SG_ Joystick3Lamp4Cmd : 46|2@1+ (1,0) [0|3] "" Vector__XXX
 SG_ Joystick3Lamp3Cmd : 44|2@1+ (1,0) [0|3] "" Vector__XXX
 SG_ Joystick3Lamp2Cmd : 42|2@1+ (1,0) [0|3] "" Vector__XXX
 SG_ Joystick3Lamp1Cmd : 40|2@1+ (1,0) [0|3] "" Vector__XXX
 SG_ Joystick2Lamp10Cmd : 38|2@1+ (1,0) [0|3] "" Vector__XXX
 SG_ Joystick2Lamp9Cmd : 36|2@1+ (1,0) [0|3] "" Vector__XXX
 SG_ Joystick2Lamp8Cmd : 34|2@1+ (1,0) [0|3] "" Vector__XXX
 SG_ Joystick2Lamp7Cmd : 32|2@1+ (1,0) [0|3] "" Vector__XXX
 SG_ Joystick2Lamp6Cmd : 30|2@1+ (1,0) [0|3] "" Vector__XXX
 SG_ Joystick2Lamp5Cmd : 28|2@1+ (1,0) [0|3] "" Vector__XXX
 SG_ Joystick2Lamp4Cmd : 26|2@1+ (1,0) [0|3] "" Vector__XXX
 SG_ Joystick2Lamp3Cmd : 24|2@1+ (1,0) [0|3] "" Vector__XXX
 SG_ Joystick2Lamp2Cmd : 22|2@1+ (1,0) [0|3] "" Vector__XXX
 SG_ Joystick2Lamp1Cmd : 20|2@1+ (1,0) [0|3] "" Vector__XXX
 SG_ Joystick1Lamp10Cmd : 18|2@1+ (1,0) [0|3] "" Vector__XXX
 SG_ Joystick1Lamp9Cmd : 16|2@1+ (1,0) [0|3] "" Vector__XXX
 SG_ Joystick1Lamp8Cmd : 14|2@1+ (1,0) [0|3] "" Vector__XXX
 SG_ Joystick1Lamp7Cmd : 12|2@1+ (1,0) [0|3] "" Vector__XXX
 SG_ Joystick1Lamp6Cmd : 10|2@1+ (1,0) [0|3] "" Vector__XXX
 SG_ Joystick1Lamp5Cmd : 8|2@1+ (1,0) [0|3] "" Vector__XXX
 SG_ Joystick1Lamp4Cmd : 6|2@1+ (1,0) [0|3] "" Vector__XXX
 SG_ Joystick1Lamp3Cmd : 4|2@1+ (1,0) [0|3] "" Vector__XXX
 SG_ Joystick1Lamp2Cmd : 2|2@1+ (1,0) [0|3] "" Vector__XXX
 SG_ Joystick1Lamp1Cmd : 0|2@1+ (1,0) [0|3] "" Vector__XXX

BO_ 2566711550 IVAC: 8 Vector__XXX
 SG_ IntkVlvActtnSystmOlPrss2SlndCtrl : 2|2@1+ (1,0) [0|3] "" Vector__XXX
 SG_ IntkVlvActtnSystmOlPrss1SlndCtrl : 0|2@1+ (1,0) [0|3] "" Vector__XXX

CM_ BO_ 2566844705 "Cruise Control/Vehicle Speed";
CM_ SG_ 2566844705 ParkBrakeReleaseInhibitRq "Park Brake Release Inhibit Request signals the desire that an applied park brake remain applied and limit the ability of the";
CM_ SG_ 2566844705 PTOGovernorState "This parameter is used to indicate the current state or mode of operation by the power takeoff (PTO) governor.";
CM_ SG_ 2566844705 EngShutdownOverrideSwitch "Switch signal which indicates the position of the engine shutdown override switch.";
CM_ SG_ 2566844705 EngTestModeSwitch "Switch signal which indicates the position of the engine test mode switch.";
CM_ SG_ 2566844705 EngIdleDecrementSwitch "Switch signal which indicates the position of the idle decrement switch.";
CM_ SG_ 2566844705 EngIdleIncrementSwitch "Switch signal which indicates the position of the idle increment switch.";
CM_ SG_ 2566844705 CruiseCtrlStates "This parameter is used to indicate the current state, or mode, of operation by the cruise control device.";
CM_ SG_ 2566844705 CruiseCtrlSetSpeed "Value of set (chosen) velocity of velocity control system.";
CM_ SG_ 2566844705 CruiseCtrlAccelerateSwitch "Switch signal of the cruise control activator which indicates that the activator is in the position “accelerate.";
CM_ SG_ 2566844705 CruiseCtrlResumeSwitch "Switch signal of the cruise control activator which indicates that the activator is in the position “resume.";
CM_ SG_ 2566844705 CruiseCtrlCoastSwitch "Switch signal of the cruise control activator which indicates that the activator is in the position “coast (decelerate).";
CM_ SG_ 2566844705 CruiseCtrlSetSwitch "Switch signal of the cruise control activator which indicates that the activator is in the position “set.";
CM_ SG_ 2566844705 ClutchSwitch "Switch signal which indicates that the clutch pedal is being pressed.";
CM_ SG_ 2566844705 BrakeSwitch_SA21 "Switch signal which indicates that the driver operated brake foot pedal is being pressed.";
CM_ SG_ 2566844705 CruiseCtrlEnableSwitch "Switch signal which indicates that it is possible to manage the cruise control function.";
CM_ SG_ 2566844705 CruiseCtrlActive "Cruise control is switched on.";
CM_ SG_ 2566844705 WheelBasedVehicleSpeed "Speed of the vehicle as calculated from wheel or tailshaft speed.";
CM_ SG_ 2566844705 CruiseCtrlPauseSwitch "Switch signal which indicates the position of the Cruise Control Pause Switch used on Remote Cruise Control applications.";
CM_ SG_ 2566844705 ParkingBrakeSwitch "Switch signal which indicates when the parking brake is set.";
CM_ SG_ 2566844705 TwoSpeedAxleSwitch "Switch signal which indicates the current axle range.";
CM_ BO_ 2566844695 "Cruise Control/Vehicle Speed";
CM_ SG_ 2566844695 ParkBrakeReleaseInhibitRq "Park Brake Release Inhibit Request signals the desire that an applied park brake remain applied and limit the ability of the";
CM_ SG_ 2566844695 PTOGovernorState "This parameter is used to indicate the current state or mode of operation by the power takeoff (PTO) governor.";
CM_ SG_ 2566844695 EngShutdownOverrideSwitch "Switch signal which indicates the position of the engine shutdown override switch.";
CM_ SG_ 2566844695 EngTestModeSwitch "Switch signal which indicates the position of the engine test mode switch.";
CM_ SG_ 2566844695 EngIdleDecrementSwitch "Switch signal which indicates the position of the idle decrement switch.";
CM_ SG_ 2566844695 EngIdleIncrementSwitch "Switch signal which indicates the position of the idle increment switch.";
CM_ SG_ 2566844695 CruiseCtrlStates "This parameter is used to indicate the current state, or mode, of operation by the cruise control device.";
CM_ SG_ 2566844695 CruiseCtrlSetSpeed "Value of set (chosen) velocity of velocity control system.";
CM_ SG_ 2566844695 CruiseCtrlAccelerateSwitch "Switch signal of the cruise control activator which indicates that the activator is in the position “accelerate.";
CM_ SG_ 2566844695 CruiseCtrlResumeSwitch "Switch signal of the cruise control activator which indicates that the activator is in the position “resume.";
CM_ SG_ 2566844695 CruiseCtrlCoastSwitch "Switch signal of the cruise control activator which indicates that the activator is in the position “coast (decelerate).";
CM_ SG_ 2566844695 CruiseCtrlSetSwitch "Switch signal of the cruise control activator which indicates that the activator is in the position “set.";
CM_ SG_ 2566844695 ClutchSwitch "Switch signal which indicates that the clutch pedal is being pressed.";
CM_ SG_ 2566844695 BrakeSwitch_SA17 "Switch signal which indicates that the driver operated brake foot pedal is being pressed.";
CM_ SG_ 2566844695 CruiseCtrlEnableSwitch "Switch signal which indicates that it is possible to manage the cruise control function.";
CM_ SG_ 2566844695 CruiseCtrlActive "Cruise control is switched on.";
CM_ SG_ 2566844695 WheelBasedVehicleSpeed "Speed of the vehicle as calculated from wheel or tailshaft speed.";
CM_ SG_ 2566844695 CruiseCtrlPauseSwitch "Switch signal which indicates the position of the Cruise Control Pause Switch used on Remote Cruise Control applications.";
CM_ SG_ 2566844695 ParkingBrakeSwitch "Switch signal which indicates when the parking brake is set.";
CM_ SG_ 2566844695 TwoSpeedAxleSwitch "Switch signal which indicates the current axle range.";
CM_ BO_ 2566844689 "Cruise Control/Vehicle Speed";
CM_ SG_ 2566844689 ParkBrakeReleaseInhibitRq "Park Brake Release Inhibit Request signals the desire that an applied park brake remain applied and limit the ability of the";
CM_ SG_ 2566844689 PTOGovernorState "This parameter is used to indicate the current state or mode of operation by the power takeoff (PTO) governor.";
CM_ SG_ 2566844689 EngShutdownOverrideSwitch "Switch signal which indicates the position of the engine shutdown override switch.";
CM_ SG_ 2566844689 EngTestModeSwitch "Switch signal which indicates the position of the engine test mode switch.";
CM_ SG_ 2566844689 EngIdleDecrementSwitch "Switch signal which indicates the position of the idle decrement switch.";
CM_ SG_ 2566844689 EngIdleIncrementSwitch "Switch signal which indicates the position of the idle increment switch.";
CM_ SG_ 2566844689 CruiseCtrlStates "This parameter is used to indicate the current state, or mode, of operation by the cruise control device.";
CM_ SG_ 2566844689 CruiseCtrlSetSpeed "Value of set (chosen) velocity of velocity control system.";
CM_ SG_ 2566844689 CruiseCtrlAccelerateSwitch "Switch signal of the cruise control activator which indicates that the activator is in the position “accelerate.";
CM_ SG_ 2566844689 CruiseCtrlResumeSwitch "Switch signal of the cruise control activator which indicates that the activator is in the position “resume.";
CM_ SG_ 2566844689 CruiseCtrlCoastSwitch "Switch signal of the cruise control activator which indicates that the activator is in the position “coast (decelerate).";
CM_ SG_ 2566844689 CruiseCtrlSetSwitch "Switch signal of the cruise control activator which indicates that the activator is in the position “set.";
CM_ SG_ 2566844689 ClutchSwitch "Switch signal which indicates that the clutch pedal is being pressed.";
CM_ SG_ 2566844689 BrakeSwitch_SA11 "Switch signal which indicates that the driver operated brake foot pedal is being pressed.";
CM_ SG_ 2566844689 CruiseCtrlEnableSwitch "Switch signal which indicates that it is possible to manage the cruise control function.";
CM_ SG_ 2566844689 CruiseCtrlActive "Cruise control is switched on.";
CM_ SG_ 2566844689 WheelBasedVehicleSpeed "Speed of the vehicle as calculated from wheel or tailshaft speed.";
CM_ SG_ 2566844689 CruiseCtrlPauseSwitch "Switch signal which indicates the position of the Cruise Control Pause Switch used on Remote Cruise Control applications.";
CM_ SG_ 2566844689 ParkingBrakeSwitch "Switch signal which indicates when the parking brake is set.";
CM_ SG_ 2566844689 TwoSpeedAxleSwitch "Switch signal which indicates the current axle range.";
CM_ BO_ 2566844683 "Cruise Control/Vehicle Speed";
CM_ SG_ 2566844683 ParkBrakeReleaseInhibitRq "Park Brake Release Inhibit Request signals the desire that an applied park brake remain applied and limit the ability of the";
CM_ SG_ 2566844683 PTOGovernorState "This parameter is used to indicate the current state or mode of operation by the power takeoff (PTO) governor.";
CM_ SG_ 2566844683 EngShutdownOverrideSwitch "Switch signal which indicates the position of the engine shutdown override switch.";
CM_ SG_ 2566844683 EngTestModeSwitch "Switch signal which indicates the position of the engine test mode switch.";
CM_ SG_ 2566844683 EngIdleDecrementSwitch "Switch signal which indicates the position of the idle decrement switch.";
CM_ SG_ 2566844683 EngIdleIncrementSwitch "Switch signal which indicates the position of the idle increment switch.";
CM_ SG_ 2566844683 CruiseCtrlStates "This parameter is used to indicate the current state, or mode, of operation by the cruise control device.";
CM_ SG_ 2566844683 CruiseCtrlSetSpeed "Value of set (chosen) velocity of velocity control system.";
CM_ SG_ 2566844683 CruiseCtrlAccelerateSwitch "Switch signal of the cruise control activator which indicates that the activator is in the position “accelerate.";
CM_ SG_ 2566844683 CruiseCtrlResumeSwitch "Switch signal of the cruise control activator which indicates that the activator is in the position “resume.";
CM_ SG_ 2566844683 CruiseCtrlCoastSwitch "Switch signal of the cruise control activator which indicates that the activator is in the position “coast (decelerate).";
CM_ SG_ 2566844683 CruiseCtrlSetSwitch "Switch signal of the cruise control activator which indicates that the activator is in the position “set.";
CM_ SG_ 2566844683 ClutchSwitch "Switch signal which indicates that the clutch pedal is being pressed.";
CM_ SG_ 2566844683 BrakeSwitch_SA0B "Switch signal which indicates that the driver operated brake foot pedal is being pressed.";
CM_ SG_ 2566844683 CruiseCtrlEnableSwitch "Switch signal which indicates that it is possible to manage the cruise control function.";
CM_ SG_ 2566844683 CruiseCtrlActive "Cruise control is switched on.";
CM_ SG_ 2566844683 WheelBasedVehicleSpeed "Speed of the vehicle as calculated from wheel or tailshaft speed.";
CM_ SG_ 2566844683 CruiseCtrlPauseSwitch "Switch signal which indicates the position of the Cruise Control Pause Switch used on Remote Cruise Control applications.";
CM_ SG_ 2566844683 ParkingBrakeSwitch "Switch signal which indicates when the parking brake is set.";
CM_ SG_ 2566844683 TwoSpeedAxleSwitch "Switch signal which indicates the current axle range.";
CM_ BO_ 2566844672 "Cruise Control/Vehicle Speed";
CM_ SG_ 2566844672 ParkBrakeReleaseInhibitRq "Park Brake Release Inhibit Request signals the desire that an applied park brake remain applied and limit the ability of the";
CM_ SG_ 2566844672 PTOGovernorState "This parameter is used to indicate the current state or mode of operation by the power takeoff (PTO) governor.";
CM_ SG_ 2566844672 EngShutdownOverrideSwitch "Switch signal which indicates the position of the engine shutdown override switch.";
CM_ SG_ 2566844672 EngTestModeSwitch "Switch signal which indicates the position of the engine test mode switch.";
CM_ SG_ 2566844672 EngIdleDecrementSwitch "Switch signal which indicates the position of the idle decrement switch.";
CM_ SG_ 2566844672 EngIdleIncrementSwitch "Switch signal which indicates the position of the idle increment switch.";
CM_ SG_ 2566844672 CruiseCtrlStates "This parameter is used to indicate the current state, or mode, of operation by the cruise control device.";
CM_ SG_ 2566844672 CruiseCtrlSetSpeed "Value of set (chosen) velocity of velocity control system.";
CM_ SG_ 2566844672 CruiseCtrlAccelerateSwitch "Switch signal of the cruise control activator which indicates that the activator is in the position “accelerate.";
CM_ SG_ 2566844672 CruiseCtrlResumeSwitch "Switch signal of the cruise control activator which indicates that the activator is in the position “resume.";
CM_ SG_ 2566844672 CruiseCtrlCoastSwitch "Switch signal of the cruise control activator which indicates that the activator is in the position “coast (decelerate).";
CM_ SG_ 2566844672 CruiseCtrlSetSwitch "Switch signal of the cruise control activator which indicates that the activator is in the position “set.";
CM_ SG_ 2566844672 ClutchSwitch "Switch signal which indicates that the clutch pedal is being pressed.";
CM_ SG_ 2566844672 BrakeSwitch_SA00 "Switch signal which indicates that the driver operated brake foot pedal is being pressed.";
CM_ SG_ 2566844672 CruiseCtrlEnableSwitch "Switch signal which indicates that it is possible to manage the cruise control function.";
CM_ SG_ 2566844672 CruiseCtrlActive "Cruise control is switched on.";
CM_ SG_ 2566844672 WheelBasedVehicleSpeed "Speed of the vehicle as calculated from wheel or tailshaft speed.";
CM_ SG_ 2566844672 CruiseCtrlPauseSwitch "Switch signal which indicates the position of the Cruise Control Pause Switch used on Remote Cruise Control applications.";
CM_ SG_ 2566844672 ParkingBrakeSwitch "Switch signal which indicates when the parking brake is set.";
CM_ SG_ 2566844672 TwoSpeedAxleSwitch "Switch signal which indicates the current axle range.";
CM_ BO_ 2565865513 "Electronic Retarder Controller 1";
CM_ SG_ 2565865513 RetarderSelectionNonEng "The “Retarder Selection, non-engine” is the position of the driver’s selector for retarders that are not part of the engine";
CM_ SG_ 2565865513 SrcAddrssOfCtrllngDvcFrRtrdrCntr "The source address of the SAE J1939 device currently controlling the retarder.";
CM_ SG_ 2565865513 RetarderRoadSpeedLimitSwitch "Retarder road speed limit switch states:";
CM_ SG_ 2565865513 RetarderRoadSpeedExceededStatus "Retarder Road Speed Exceeded Status:";
CM_ SG_ 2565865513 ActlMxAvlblRtarderPercentTorque "This is the maximum amount of torque that the retarder can immediately deliver.";
CM_ SG_ 2565865513 DrvrsDmandRetarderPercentTorque "The Drivers demand retarder – percent torque is the maximum torque selected by the driver when one or more modes";
CM_ SG_ 2565865513 RetarderRqingBrakeLight "Indicates that whether the retarder is requesting that the brake lights are illuminated.";
CM_ SG_ 2565865513 EngCoolantLoadIncrease "Status of an event, external to the engine, that may increase the nominal temperature of the engine coolant liquid.";
CM_ SG_ 2565865513 IntendedRetarderPercentTorque "Braking torque of retarder that the retarder is currently trying to achieve.";
CM_ SG_ 2565865513 ActualRetarderPercentTorque "Actual braking torque of the retarder as a percent of retarder configuration reference torque SPN 556.";
CM_ SG_ 2565865513 RetarderEnableShiftAssistSwitch "Switch signal which indicates whether the operator wishes the retarder to be enabled for transmission shift assist.";
CM_ SG_ 2565865513 RetarderEnableBrakeAssistSwitch "Switch signal which indicates whether the operator wishes the retarder to be enabled for vehicle braking assist.";
CM_ SG_ 2565865513 RetarderTorqueMode "State signal which indicates which retarder torque mode is currently generating, limiting, or controlling the torque.";
CM_ BO_ 2565865487 "Electronic Retarder Controller 1";
CM_ SG_ 2565865487 RetarderSelectionNonEng "The “Retarder Selection, non-engine” is the position of the driver’s selector for retarders that are not part of the engine";
CM_ SG_ 2565865487 SrcAddrssOfCtrllngDvcFrRtrd_0000 "The source address of the SAE J1939 device currently controlling the retarder.";
CM_ SG_ 2565865487 RetarderRoadSpeedLimitSwitch "Retarder road speed limit switch states:";
CM_ SG_ 2565865487 RetarderRoadSpeedExceededStatus "Retarder Road Speed Exceeded Status:";
CM_ SG_ 2565865487 ActlMxAvlblRtarderPercentTorque "This is the maximum amount of torque that the retarder can immediately deliver.";
CM_ SG_ 2565865487 DrvrsDmandRetarderPercentTorque "The Drivers demand retarder – percent torque is the maximum torque selected by the driver when one or more modes";
CM_ SG_ 2565865487 RetarderRqingBrakeLight "Indicates that whether the retarder is requesting that the brake lights are illuminated.";
CM_ SG_ 2565865487 EngCoolantLoadIncrease "Status of an event, external to the engine, that may increase the nominal temperature of the engine coolant liquid.";
CM_ SG_ 2565865487 IntendedRetarderPercentTorque "Braking torque of retarder that the retarder is currently trying to achieve.";
CM_ SG_ 2565865487 ActualRetarderPercentTorque "Actual braking torque of the retarder as a percent of retarder configuration reference torque SPN 556.";
CM_ SG_ 2565865487 RetarderEnableShiftAssistSwitch "Switch signal which indicates whether the operator wishes the retarder to be enabled for transmission shift assist.";
CM_ SG_ 2565865487 RetarderEnableBrakeAssistSwitch "Switch signal which indicates whether the operator wishes the retarder to be enabled for vehicle braking assist.";
CM_ SG_ 2565865487 RetarderTorqueMode "State signal which indicates which retarder torque mode is currently generating, limiting, or controlling the torque.";
CM_ BO_ 2364539697 "Electronic Engine Controller 2";
CM_ SG_ 2364539697 SCRThermalManagementActive "Indicates that the exhaust temperatures have been elevated for regeneration of the SCR aftertreatment system or in";
CM_ SG_ 2364539697 MmntryEngMaxPowerEnableFeedback "Momentarily requesting Engine Maximum Power Enable - feature support feedback";
CM_ SG_ 2364539697 EstPumpingPercentTorque "The calculated torque that indicates the estimated amount of torque loss due to the engine air handling system.";
CM_ SG_ 2364539697 DPFThermalManagementActive "Indicates that the exhaust temperatures have been elevated for regeneration of the diesel particulate filter aftertreatment";
CM_ SG_ 2364539697 ActlMxAvailableEngPercentTorque "This is the maximum amount of torque that the engine can immediately deliver as a percentage of the reference engine";
CM_ SG_ 2364539697 AccelPedalPos2 "The ratio of actual position of the second analog engine speed/torque request input device (such as an accelerator pedal";
CM_ SG_ 2364539697 VhclAccelerationRateLimitStatus "Status (active or not active) of the system used to limit maximum forward vehicle acceleration.";
CM_ SG_ 2364539697 EngPercentLoadAtCurrentSpeed "The ratio of actual engine percent torque (indicated) to maximum indicated torque available at the current engine speed,";
CM_ SG_ 2364539697 AccelPedal2LowIdleSwitch "Switch signal which indicates the state of the accelerator pedal 2 low idle switch.";
CM_ SG_ 2364539697 RoadSpeedLimitStatus "Status (active or not active) of the system used to limit maximum vehicle velocity.";
CM_ SG_ 2364539697 AccelPedalKickdownSwitch "Switch signal which indicates whether the accelerator pedal kickdown switch is opened or closed.";
CM_ SG_ 2364539697 AccelPedal1LowIdleSwitch "Switch signal which indicates the state of the accelerator pedal 1 low idle switch.";
CM_ SG_ 2364539697 RemoteAccelPedalPos "The ratio of actual position of the remote analog engine speed/torque request input device (such as an accelerator pedal";
CM_ SG_ 2364539697 AccelPedalPos1_SA31 "The ratio of actual position of the analog engine speed/torque request input device (such as an accelerator pedal or";
CM_ BO_ 2364539681 "Electronic Engine Controller 2";
CM_ SG_ 2364539681 SCRThermalManagementActive "Indicates that the exhaust temperatures have been elevated for regeneration of the SCR aftertreatment system or in";
CM_ SG_ 2364539681 MmntryEngMaxPowerEnableFeedback "Momentarily requesting Engine Maximum Power Enable - feature support feedback";
CM_ SG_ 2364539681 EstPumpingPercentTorque "The calculated torque that indicates the estimated amount of torque loss due to the engine air handling system.";
CM_ SG_ 2364539681 DPFThermalManagementActive "Indicates that the exhaust temperatures have been elevated for regeneration of the diesel particulate filter aftertreatment";
CM_ SG_ 2364539681 ActlMxAvailableEngPercentTorque "This is the maximum amount of torque that the engine can immediately deliver as a percentage of the reference engine";
CM_ SG_ 2364539681 AccelPedalPos2 "The ratio of actual position of the second analog engine speed/torque request input device (such as an accelerator pedal";
CM_ SG_ 2364539681 VhclAccelerationRateLimitStatus "Status (active or not active) of the system used to limit maximum forward vehicle acceleration.";
CM_ SG_ 2364539681 EngPercentLoadAtCurrentSpeed "The ratio of actual engine percent torque (indicated) to maximum indicated torque available at the current engine speed,";
CM_ SG_ 2364539681 AccelPedal2LowIdleSwitch "Switch signal which indicates the state of the accelerator pedal 2 low idle switch.";
CM_ SG_ 2364539681 RoadSpeedLimitStatus "Status (active or not active) of the system used to limit maximum vehicle velocity.";
CM_ SG_ 2364539681 AccelPedalKickdownSwitch "Switch signal which indicates whether the accelerator pedal kickdown switch is opened or closed.";
CM_ SG_ 2364539681 AccelPedal1LowIdleSwitch "Switch signal which indicates the state of the accelerator pedal 1 low idle switch.";
CM_ SG_ 2364539681 RemoteAccelPedalPos "The ratio of actual position of the remote analog engine speed/torque request input device (such as an accelerator pedal";
CM_ SG_ 2364539681 AccelPedalPos1_SA21 "The ratio of actual position of the analog engine speed/torque request input device (such as an accelerator pedal or";
CM_ BO_ 2364539671 "Electronic Engine Controller 2";
CM_ SG_ 2364539671 SCRThermalManagementActive "Indicates that the exhaust temperatures have been elevated for regeneration of the SCR aftertreatment system or in";
CM_ SG_ 2364539671 MmntryEngMaxPowerEnableFeedback "Momentarily requesting Engine Maximum Power Enable - feature support feedback";
CM_ SG_ 2364539671 EstPumpingPercentTorque "The calculated torque that indicates the estimated amount of torque loss due to the engine air handling system.";
CM_ SG_ 2364539671 DPFThermalManagementActive "Indicates that the exhaust temperatures have been elevated for regeneration of the diesel particulate filter aftertreatment";
CM_ SG_ 2364539671 ActlMxAvailableEngPercentTorque "This is the maximum amount of torque that the engine can immediately deliver as a percentage of the reference engine";
CM_ SG_ 2364539671 AccelPedalPos2 "The ratio of actual position of the second analog engine speed/torque request input device (such as an accelerator pedal";
CM_ SG_ 2364539671 VhclAccelerationRateLimitStatus "Status (active or not active) of the system used to limit maximum forward vehicle acceleration.";
CM_ SG_ 2364539671 EngPercentLoadAtCurrentSpeed "The ratio of actual engine percent torque (indicated) to maximum indicated torque available at the current engine speed,";
CM_ SG_ 2364539671 AccelPedal2LowIdleSwitch "Switch signal which indicates the state of the accelerator pedal 2 low idle switch.";
CM_ SG_ 2364539671 RoadSpeedLimitStatus "Status (active or not active) of the system used to limit maximum vehicle velocity.";
CM_ SG_ 2364539671 AccelPedalKickdownSwitch "Switch signal which indicates whether the accelerator pedal kickdown switch is opened or closed.";
CM_ SG_ 2364539671 AccelPedal1LowIdleSwitch "Switch signal which indicates the state of the accelerator pedal 1 low idle switch.";
CM_ SG_ 2364539671 RemoteAccelPedalPos "The ratio of actual position of the remote analog engine speed/torque request input device (such as an accelerator pedal";
CM_ SG_ 2364539671 AccelPedalPos1_SA17 "The ratio of actual position of the analog engine speed/torque request input device (such as an accelerator pedal or";
CM_ BO_ 2364539665 "Electronic Engine Controller 2";
CM_ SG_ 2364539665 SCRThermalManagementActive "Indicates that the exhaust temperatures have been elevated for regeneration of the SCR aftertreatment system or in";
CM_ SG_ 2364539665 MmntryEngMaxPowerEnableFeedback "Momentarily requesting Engine Maximum Power Enable - feature support feedback";
CM_ SG_ 2364539665 EstPumpingPercentTorque "The calculated torque that indicates the estimated amount of torque loss due to the engine air handling system.";
CM_ SG_ 2364539665 DPFThermalManagementActive "Indicates that the exhaust temperatures have been elevated for regeneration of the diesel particulate filter aftertreatment";
CM_ SG_ 2364539665 ActlMxAvailableEngPercentTorque "This is the maximum amount of torque that the engine can immediately deliver as a percentage of the reference engine";
CM_ SG_ 2364539665 AccelPedalPos2 "The ratio of actual position of the second analog engine speed/torque request input device (such as an accelerator pedal";
CM_ SG_ 2364539665 VhclAccelerationRateLimitStatus "Status (active or not active) of the system used to limit maximum forward vehicle acceleration.";
CM_ SG_ 2364539665 EngPercentLoadAtCurrentSpeed "The ratio of actual engine percent torque (indicated) to maximum indicated torque available at the current engine speed,";
CM_ SG_ 2364539665 AccelPedal2LowIdleSwitch "Switch signal which indicates the state of the accelerator pedal 2 low idle switch.";
CM_ SG_ 2364539665 RoadSpeedLimitStatus "Status (active or not active) of the system used to limit maximum vehicle velocity.";
CM_ SG_ 2364539665 AccelPedalKickdownSwitch "Switch signal which indicates whether the accelerator pedal kickdown switch is opened or closed.";
CM_ SG_ 2364539665 AccelPedal1LowIdleSwitch "Switch signal which indicates the state of the accelerator pedal 1 low idle switch.";
CM_ SG_ 2364539665 RemoteAccelPedalPos "The ratio of actual position of the remote analog engine speed/torque request input device (such as an accelerator pedal";
CM_ SG_ 2364539665 AccelPedalPos1_SA11 "The ratio of actual position of the analog engine speed/torque request input device (such as an accelerator pedal or";
CM_ BO_ 2364539648 "Electronic Engine Controller 2";
CM_ SG_ 2364539648 SCRThermalManagementActive "Indicates that the exhaust temperatures have been elevated for regeneration of the SCR aftertreatment system or in";
CM_ SG_ 2364539648 MmntryEngMaxPowerEnableFeedback "Momentarily requesting Engine Maximum Power Enable - feature support feedback";
CM_ SG_ 2364539648 EstPumpingPercentTorque "The calculated torque that indicates the estimated amount of torque loss due to the engine air handling system.";
CM_ SG_ 2364539648 DPFThermalManagementActive "Indicates that the exhaust temperatures have been elevated for regeneration of the diesel particulate filter aftertreatment";
CM_ SG_ 2364539648 ActlMxAvailableEngPercentTorque "This is the maximum amount of torque that the engine can immediately deliver as a percentage of the reference engine";
CM_ SG_ 2364539648 AccelPedalPos2 "The ratio of actual position of the second analog engine speed/torque request input device (such as an accelerator pedal";
CM_ SG_ 2364539648 VhclAccelerationRateLimitStatus "Status (active or not active) of the system used to limit maximum forward vehicle acceleration.";
CM_ SG_ 2364539648 EngPercentLoadAtCurrentSpeed "The ratio of actual engine percent torque (indicated) to maximum indicated torque available at the current engine speed,";
CM_ SG_ 2364539648 AccelPedal2LowIdleSwitch "Switch signal which indicates the state of the accelerator pedal 2 low idle switch.";
CM_ SG_ 2364539648 RoadSpeedLimitStatus "Status (active or not active) of the system used to limit maximum vehicle velocity.";
CM_ SG_ 2364539648 AccelPedalKickdownSwitch "Switch signal which indicates whether the accelerator pedal kickdown switch is opened or closed.";
CM_ SG_ 2364539648 AccelPedal1LowIdleSwitch "Switch signal which indicates the state of the accelerator pedal 1 low idle switch.";
CM_ SG_ 2364539648 RemoteAccelPedalPos "The ratio of actual position of the remote analog engine speed/torque request input device (such as an accelerator pedal";
CM_ SG_ 2364539648 AccelPedalPos1_SA00 "The ratio of actual position of the analog engine speed/torque request input device (such as an accelerator pedal or";
CM_ BO_ 2566767665 "Electronic Brake Controller 5";
CM_ SG_ 2566767665 BrakeTempWarning "This parameter indicates if the temperature in the service brakes exceeds a certain value.";
CM_ SG_ 2566767665 PrkngBrkeActuatorFullyActivated "Signal which indicates when the parking brake actuator is fully activated.";
CM_ SG_ 2566767665 XBRAccelerationLimit "The brake system may temporarily or generally limit the maximum brake performance available for external systems.";
CM_ SG_ 2566767665 XBRActiveCtrlMode "This parameter indicates which XBR Control Mode is executed by the brake system.";
CM_ SG_ 2566767665 XBRSystemState "This parameter indicates which external brake control is allowed.";
CM_ SG_ 2566767665 FoundationBrakeUse "This parameter indicates if the brake system presently uses the foundation brakes.";
CM_ SG_ 2566767665 HillHolderMode "Signal which indicates the current mode of the hill holder function.";
CM_ SG_ 2566767665 HaltBrakeMode "Signal which indicates the current mode of the halt brake function.";
CM_ BO_ 2566767627 "Electronic Brake Controller 5";
CM_ SG_ 2566767627 BrakeTempWarning "This parameter indicates if the temperature in the service brakes exceeds a certain value.";
CM_ SG_ 2566767627 PrkngBrkeActuatorFullyActivated "Signal which indicates when the parking brake actuator is fully activated.";
CM_ SG_ 2566767627 XBRAccelerationLimit "The brake system may temporarily or generally limit the maximum brake performance available for external systems.";
CM_ SG_ 2566767627 XBRActiveCtrlMode "This parameter indicates which XBR Control Mode is executed by the brake system.";
CM_ SG_ 2566767627 XBRSystemState "This parameter indicates which external brake control is allowed.";
CM_ SG_ 2566767627 FoundationBrakeUse "This parameter indicates if the brake system presently uses the foundation brakes.";
CM_ SG_ 2566767627 HillHolderMode "Signal which indicates the current mode of the hill holder function.";
CM_ SG_ 2566767627 HaltBrakeMode "Signal which indicates the current mode of the halt brake function.";
CM_ BO_ 2565865777 "Electronic Brake Controller 1";
CM_ SG_ 2565865777 EngAuxShutdownSwitch "Switch signal which requests that all engine fueling stop.";
CM_ SG_ 2565865777 SrcAddrssOfCtrllngDvcFrBrkCntrl "The source address of the SAE J1939 device currently controlling the brake system.";
CM_ SG_ 2565865777 BrakePedalPos "Ratio of brake pedal position to maximum pedal position.";
CM_ SG_ 2565865777 TrctrMntdTrilerABSWarningSignal "This parameter commands the tractor-mounted trailer ABS optical warning signal.";
CM_ SG_ 2565865777 TrailerABSStatus "State signal which indicates that ABS in the trailer is actively controlling the brakes.";
CM_ SG_ 2565865777 HaltBrakeSwitch "Switch signal which indicates the position of the halt brake switch.";
CM_ SG_ 2565865777 ATC_ASRInformationSignal "This parameter commands the ATC/ASR driver information signal, for example a dash lamp.";
CM_ SG_ 2565865777 ABS_EBSAmberWarningSignal "This parameter commands the ABS/EBS amber/yellow optical warning signal";
CM_ SG_ 2565865777 EBSRedWarningSignal "This parameter commands the EBS red optical warning signal";
CM_ SG_ 2565865777 ABSFullyOperational "Signal which indicates whether an ABS system is fully operational or whether its functionality is reduced by a defect or by";
CM_ SG_ 2565865777 EngRetarderSelection "The position of the operator controlled selector, expressed as a percentage and determined by the ratio of the current";
CM_ SG_ 2565865777 RemoteAccelEnableSwitch "Switch signal which indicates that the remote accelerator has been enabled and controls the engine.";
CM_ SG_ 2565865777 EngDerateSwitch "Switch signal used to activate the torque limiting feature of the engine.";
CM_ SG_ 2565865777 AccelInterlockSwitch "Switch signal used to disable the accelerator and remote accelerator inputs, causing the engine to return to idle.";
CM_ SG_ 2565865777 TractionCtrlOverrideSwitch "Switch signal which indicates the position of the traction control override switch.";
CM_ SG_ 2565865777 ASRHillHolderSwitch "Switch signal which indicates the position of the ASR “hill holder” switch.";
CM_ SG_ 2565865777 ASROffroadSwitch "Switch signal which indicates the position of the ASR off-road switch.";
CM_ SG_ 2565865777 ABSOffroadSwitch "Switch signal which indicates the position of the ABS off-road switch.";
CM_ SG_ 2565865777 EBSBrakeSwitch "Switch signal which indicates that the brake pedal is being pressed.";
CM_ SG_ 2565865777 AntiLockBrakingActive "State signal which indicates that the ABS is active.";
CM_ SG_ 2565865777 ASRBrakeCtrlActive "State signal which indicates that ASR brake control is active.";
CM_ SG_ 2565865777 ASREngCtrlActive "State signal which indicates that ASR engine control has been commanded to be active.";
CM_ BO_ 2565865761 "Electronic Brake Controller 1";
CM_ SG_ 2565865761 EngAuxShutdownSwitch "Switch signal which requests that all engine fueling stop.";
CM_ SG_ 2565865761 SrcAddrssOfCtrllngDvcFrBrkCntrl "The source address of the SAE J1939 device currently controlling the brake system.";
CM_ SG_ 2565865761 BrakePedalPos "Ratio of brake pedal position to maximum pedal position.";
CM_ SG_ 2565865761 TrctrMntdTrilerABSWarningSignal "This parameter commands the tractor-mounted trailer ABS optical warning signal.";
CM_ SG_ 2565865761 TrailerABSStatus "State signal which indicates that ABS in the trailer is actively controlling the brakes.";
CM_ SG_ 2565865761 HaltBrakeSwitch "Switch signal which indicates the position of the halt brake switch.";
CM_ SG_ 2565865761 ATC_ASRInformationSignal "This parameter commands the ATC/ASR driver information signal, for example a dash lamp.";
CM_ SG_ 2565865761 ABS_EBSAmberWarningSignal "This parameter commands the ABS/EBS amber/yellow optical warning signal";
CM_ SG_ 2565865761 EBSRedWarningSignal "This parameter commands the EBS red optical warning signal";
CM_ SG_ 2565865761 ABSFullyOperational "Signal which indicates whether an ABS system is fully operational or whether its functionality is reduced by a defect or by";
CM_ SG_ 2565865761 EngRetarderSelection "The position of the operator controlled selector, expressed as a percentage and determined by the ratio of the current";
CM_ SG_ 2565865761 RemoteAccelEnableSwitch "Switch signal which indicates that the remote accelerator has been enabled and controls the engine.";
CM_ SG_ 2565865761 EngDerateSwitch "Switch signal used to activate the torque limiting feature of the engine.";
CM_ SG_ 2565865761 AccelInterlockSwitch "Switch signal used to disable the accelerator and remote accelerator inputs, causing the engine to return to idle.";
CM_ SG_ 2565865761 TractionCtrlOverrideSwitch "Switch signal which indicates the position of the traction control override switch.";
CM_ SG_ 2565865761 ASRHillHolderSwitch "Switch signal which indicates the position of the ASR “hill holder” switch.";
CM_ SG_ 2565865761 ASROffroadSwitch "Switch signal which indicates the position of the ASR off-road switch.";
CM_ SG_ 2565865761 ABSOffroadSwitch "Switch signal which indicates the position of the ABS off-road switch.";
CM_ SG_ 2565865761 EBSBrakeSwitch "Switch signal which indicates that the brake pedal is being pressed.";
CM_ SG_ 2565865761 AntiLockBrakingActive "State signal which indicates that the ABS is active.";
CM_ SG_ 2565865761 ASRBrakeCtrlActive "State signal which indicates that ASR brake control is active.";
CM_ SG_ 2565865761 ASREngCtrlActive "State signal which indicates that ASR engine control has been commanded to be active.";
CM_ BO_ 2565865739 "Electronic Brake Controller 1";
CM_ SG_ 2565865739 EngAuxShutdownSwitch "Switch signal which requests that all engine fueling stop.";
CM_ SG_ 2565865739 SrcAddrssOfCtrllngDvcFrBrkCntrl "The source address of the SAE J1939 device currently controlling the brake system.";
CM_ SG_ 2565865739 BrakePedalPos "Ratio of brake pedal position to maximum pedal position.";
CM_ SG_ 2565865739 TrctrMntdTrilerABSWarningSignal "This parameter commands the tractor-mounted trailer ABS optical warning signal.";
CM_ SG_ 2565865739 TrailerABSStatus "State signal which indicates that ABS in the trailer is actively controlling the brakes.";
CM_ SG_ 2565865739 HaltBrakeSwitch "Switch signal which indicates the position of the halt brake switch.";
CM_ SG_ 2565865739 ATC_ASRInformationSignal "This parameter commands the ATC/ASR driver information signal, for example a dash lamp.";
CM_ SG_ 2565865739 ABS_EBSAmberWarningSignal "This parameter commands the ABS/EBS amber/yellow optical warning signal";
CM_ SG_ 2565865739 EBSRedWarningSignal "This parameter commands the EBS red optical warning signal";
CM_ SG_ 2565865739 ABSFullyOperational "Signal which indicates whether an ABS system is fully operational or whether its functionality is reduced by a defect or by";
CM_ SG_ 2565865739 EngRetarderSelection "The position of the operator controlled selector, expressed as a percentage and determined by the ratio of the current";
CM_ SG_ 2565865739 RemoteAccelEnableSwitch "Switch signal which indicates that the remote accelerator has been enabled and controls the engine.";
CM_ SG_ 2565865739 EngDerateSwitch "Switch signal used to activate the torque limiting feature of the engine.";
CM_ SG_ 2565865739 AccelInterlockSwitch "Switch signal used to disable the accelerator and remote accelerator inputs, causing the engine to return to idle.";
CM_ SG_ 2565865739 TractionCtrlOverrideSwitch "Switch signal which indicates the position of the traction control override switch.";
CM_ SG_ 2565865739 ASRHillHolderSwitch "Switch signal which indicates the position of the ASR “hill holder” switch.";
CM_ SG_ 2565865739 ASROffroadSwitch "Switch signal which indicates the position of the ASR off-road switch.";
CM_ SG_ 2565865739 ABSOffroadSwitch "Switch signal which indicates the position of the ABS off-road switch.";
CM_ SG_ 2565865739 EBSBrakeSwitch "Switch signal which indicates that the brake pedal is being pressed.";
CM_ SG_ 2565865739 AntiLockBrakingActive "State signal which indicates that the ABS is active.";
CM_ SG_ 2565865739 ASRBrakeCtrlActive "State signal which indicates that ASR brake control is active.";
CM_ SG_ 2565865739 ASREngCtrlActive "State signal which indicates that ASR engine control has been commanded to be active.";
CM_ BO_ 2565865728 "Electronic Brake Controller 1";
CM_ SG_ 2565865728 EngAuxShutdownSwitch "Switch signal which requests that all engine fueling stop.";
CM_ SG_ 2565865728 SrcAddrssOfCtrllngDvcFrBrkCntrl "The source address of the SAE J1939 device currently controlling the brake system.";
CM_ SG_ 2565865728 BrakePedalPos "Ratio of brake pedal position to maximum pedal position.";
CM_ SG_ 2565865728 TrctrMntdTrilerABSWarningSignal "This parameter commands the tractor-mounted trailer ABS optical warning signal.";
CM_ SG_ 2565865728 TrailerABSStatus "State signal which indicates that ABS in the trailer is actively controlling the brakes.";
CM_ SG_ 2565865728 HaltBrakeSwitch "Switch signal which indicates the position of the halt brake switch.";
CM_ SG_ 2565865728 ATC_ASRInformationSignal "This parameter commands the ATC/ASR driver information signal, for example a dash lamp.";
CM_ SG_ 2565865728 ABS_EBSAmberWarningSignal "This parameter commands the ABS/EBS amber/yellow optical warning signal";
CM_ SG_ 2565865728 EBSRedWarningSignal "This parameter commands the EBS red optical warning signal";
CM_ SG_ 2565865728 ABSFullyOperational "Signal which indicates whether an ABS system is fully operational or whether its functionality is reduced by a defect or by";
CM_ SG_ 2565865728 EngRetarderSelection "The position of the operator controlled selector, expressed as a percentage and determined by the ratio of the current";
CM_ SG_ 2565865728 RemoteAccelEnableSwitch "Switch signal which indicates that the remote accelerator has been enabled and controls the engine.";
CM_ SG_ 2565865728 EngDerateSwitch "Switch signal used to activate the torque limiting feature of the engine.";
CM_ SG_ 2565865728 AccelInterlockSwitch "Switch signal used to disable the accelerator and remote accelerator inputs, causing the engine to return to idle.";
CM_ SG_ 2565865728 TractionCtrlOverrideSwitch "Switch signal which indicates the position of the traction control override switch.";
CM_ SG_ 2565865728 ASRHillHolderSwitch "Switch signal which indicates the position of the ASR “hill holder” switch.";
CM_ SG_ 2565865728 ASROffroadSwitch "Switch signal which indicates the position of the ASR off-road switch.";
CM_ SG_ 2565865728 ABSOffroadSwitch "Switch signal which indicates the position of the ABS off-road switch.";
CM_ SG_ 2565865728 EBSBrakeSwitch "Switch signal which indicates that the brake pedal is being pressed.";
CM_ SG_ 2565865728 AntiLockBrakingActive "State signal which indicates that the ABS is active.";
CM_ SG_ 2565865728 ASRBrakeCtrlActive "State signal which indicates that ASR brake control is active.";
CM_ SG_ 2565865728 ASREngCtrlActive "State signal which indicates that ASR engine control has been commanded to be active.";
CM_ BO_ 2348820739 "Torque/Speed Control 1";
CM_ SG_ 2348820739 EngRqedTorque_TorqueLimit "Parameter provided to the engine or retarder in the torque/speed control message for controlling or limiting the output torque.";
CM_ SG_ 2348820739 MessageCounter "The message counter is used to detect situations where the transmitting ECU malfunction repeats the same frame all the time.";
CM_ SG_ 2348820739 ControlPurpose "State signal which indicates which control mode the sending device is using to generate the TSC1 command.";
CM_ SG_ 2348820739 TransmissionRate "This parameter indicates the transmission rate at which the sending device will transmit the TSC1 message.";
CM_ SG_ 2348820739 EngRqedSpeed_SpeedLimit "Parameter provided to the engine from external sources in the torque/speed control message.";
CM_ SG_ 2348820739 EngRqedSpeedCtrlConditions "This mode tells the engine control system the governor characteristics that are desired during speed control.";
CM_ SG_ 2348820739 MessageChecksum "The checksum is used to verify the signal path from the transmitting device to the receiving device.";
CM_ SG_ 2348820739 EngineRequestedTorqueHiRes "This parameter displays an additional torque in percent of the reference engine torque.";
CM_ BO_ 2348814083 "Torque/Speed Control 1";
CM_ SG_ 2348814083 EngRqedTorque_TorqueLimit "Parameter provided to the engine or retarder in the torque/speed control message for controlling or limiting the output torque.";
CM_ SG_ 2348814083 MessageCounter "The message counter is used to detect situations where the transmitting ECU malfunction repeats the same frame all the time.";
CM_ SG_ 2348814083 ControlPurpose "State signal which indicates which control mode the sending device is using to generate the TSC1 command.";
CM_ SG_ 2348814083 TransmissionRate "This parameter indicates the transmission rate at which the sending device will transmit the TSC1 message.";
CM_ SG_ 2348814083 EngRqedSpeed_SpeedLimit "Parameter provided to the engine from external sources in the torque/speed control message.";
CM_ SG_ 2348814083 EngRqedSpeedCtrlConditions "This mode tells the engine control system the governor characteristics that are desired during speed control.";
CM_ SG_ 2348814083 MessageChecksum "The checksum is used to verify the signal path from the transmitting device to the receiving device.";
CM_ SG_ 2348814083 EngineRequestedTorqueHiRes "This parameter displays an additional torque in percent of the reference engine torque.";
CM_ BO_ 2348810243 "Torque/Speed Control 1";
CM_ SG_ 2348810243 MessageCounter "The message counter is used to detect situations where the transmitting ECU malfunction repeats the same frame all the time.";
CM_ SG_ 2348810243 ControlPurpose "State signal which indicates which control mode the sending device is using to generate the TSC1 command.";
CM_ SG_ 2348810243 TransmissionRate "This parameter indicates the transmission rate at which the sending device will transmit the TSC1 message.";
CM_ SG_ 2348810243 EngRqedTorque_TorqueLimit "Parameter provided to the engine or retarder in the torque/speed control message for controlling or limiting the output torque.";
CM_ SG_ 2348810243 EngRqedSpeed_SpeedLimit "Parameter provided to the engine from external sources in the torque/speed control message.";
CM_ SG_ 2348810243 EngRqedSpeedCtrlConditions "This mode tells the engine control system the governor characteristics that are desired during speed control.";
CM_ SG_ 2348810243 MessageChecksum "The checksum is used to verify the signal path from the transmitting device to the receiving device.";
CM_ SG_ 2348810243 EngineRequestedTorqueHiRes "This parameter displays an additional torque in percent of the reference engine torque.";
CM_ BO_ 2297441790 "The acceleration sensor message shall provide a measurement of the vehicle's acceleration in the lateral, longitudinal,
and vertical axes.";
CM_ SG_ 2297441790 SpprtVrblTrnsRpttnRtFrAcclrtnSns "Indicates which acceleration transmission rate are supported by the ECU in addition to the required 10 ms transmission";
CM_ SG_ 2297441790 VrtclAcclrtnExRngeFigureOfMerit "Figure of merit for vertical acceleration measurement.";
CM_ SG_ 2297441790 LngtdnlAcclrtnExRngFgureOfMerit "Figure of merit for longitudinal acceleration measurement.";
CM_ SG_ 2297441790 LtrlAcclrtnExRangeFigureOfMerit "Figure of merit for lateral acceleration measurement.";
CM_ SG_ 2297441790 VerticalAccelerationExRange "Indicates vertical acceleration of the vehicle and the effect of gravity.";
CM_ SG_ 2297441790 LateralAccelerationExRange "Indicates lateral acceleration of the vehicle.";
CM_ SG_ 2297441790 LongitudinalAccelerationExRange "Indicates longitudinal acceleration of the vehicle.";
CM_ BO_ 2566712062 "Vehicle Electrical Power #4";
CM_ SG_ 2566712062 HybrdBatteryPackRemainingCharge "Indicates the hybrid battery pack remaining charge.";
CM_ BO_ 2364549630 "Slope Sensor Information 2";
CM_ SG_ 2364549630 RllAndPtchExRngMsurementLatency "Time between start of sensor processing and CAN transmission";
CM_ SG_ 2364549630 RollAngleExRangeFigureOfMerit "Figure of merit for roll angle measurement.";
CM_ SG_ 2364549630 RollAngleExRangeCompensation "Compensated mode for the roll measurement.";
CM_ SG_ 2364549630 PitchAngleExRangeFigureOfMerit "Figure of merit for pitch angle measurement.";
CM_ SG_ 2364549630 PitchAngleExRangeCompensation "Compensated mode for the pitch measurement.";
CM_ SG_ 2364549630 RollAngleExRange "The angle between the vehicle y-axis and the ground plane.";
CM_ SG_ 2364549630 PitchAngleExRange "The angle between the vehicle x-axis and the ground plane.";
CM_ BO_ 2499614462 "Occupant Classification System Information";
CM_ SG_ 2499614462 OccpntClssfcationSystem10Status "State of Occupant Classification System for seat position 10.";
CM_ SG_ 2499614462 OccpntClssficationSystem9Status "State of Occupant Classification System for seat position 9.";
CM_ SG_ 2499614462 OccpntClssficationSystem8Status "State of Occupant Classification System for seat position 8.";
CM_ SG_ 2499614462 OccpntClssficationSystem7Status "State of Occupant Classification System for seat position 7.";
CM_ SG_ 2499614462 OccpntClssficationSystem6Status "State of Occupant Classification System for seat position 6.";
CM_ SG_ 2499614462 OccpntClssficationSystem5Status "State of Occupant Classification System for seat position 5.";
CM_ SG_ 2499614462 OccpntClssficationSystem4Status "State of Occupant Classification System for seat position 4.";
CM_ SG_ 2499614462 OccpntClssficationSystem3Status "State of Occupant Classification System for seat position 3.";
CM_ SG_ 2499614462 PssngrOccpntClssfctnSystmStatus "State of Occupant Classification System for passenger.";
CM_ SG_ 2499614462 DrvrOccpntClssfctonSystemStatus "State of Occupant Classification System for driver.";
CM_ BO_ 2560098046 "Noise Control Status";
CM_ SG_ 2560098046 CabNoiseCtrlTuningStatus "This parameter returns the current status of tuning function of the Cab Noise Control system.";
CM_ SG_ 2560098046 CabNoiseCtrlStatus "This parameter returns the current status of the Cab Noise Control system.";
CM_ BO_ 2560163582 "Noise Control 1";
CM_ SG_ 2560163582 CabNoiseCtrlTuningState "Command values for the Tuning State of the Cab Noise Control System.";
CM_ SG_ 2560163582 CabNoiseCtrlState "Command signal to change the state of the Cab Noise Control System to on-line or off-line";
CM_ BO_ 2297441534 "Magnet Status Information 2";
CM_ SG_ 2297441534 DropRelayCtrl "Command signal used to Engage and Disengage the Drop Relay controlling a Steady-State Magnet.";
CM_ SG_ 2297441534 LiftRelayCtrl "Command signal used to Engage and Disengage the Lift Relay controlling a Steady-State Magnet.";
CM_ SG_ 2297441534 MaterialDropActiveStatus "The status of Material Drop Relay.";
CM_ SG_ 2297441534 MaterialLiftActiveStatus "The status of Material Lift Relay.";
CM_ SG_ 2297441534 GnratorCurrentBoostActiveStatus "Status of generator current boost relay that can boost the generator output current for picking-up material operations.";
CM_ SG_ 2297441534 MaterialDropSwitch "This is a switch that can be used to enable the drop functionality of the Material Handler machine.";
CM_ SG_ 2297441534 MaterialLiftSwitch "This is a switch that can be used to enable the lift functionality of the Material Handler machine.";
CM_ SG_ 2297441534 MagnetReverseCurrent "A reverse current being supplied to the electric magnet to reduce the forward current generated magnet field as quick as";
CM_ SG_ 2297441534 MagnetForwardCurrent "The forward current being supplied by the generator to the electric magnet to create a magnet field to lift material.";
CM_ BO_ 2566722302 "Magnet Status Information 1";
CM_ SG_ 2566722302 GneratorDutyCycleExceededStatus "The status of the duty cycle of the generator usage, indicating if the generator has been on for too much time within a";
CM_ SG_ 2566722302 VoltageMonitorActiveStatus "Status of Voltage Monitor Relay.";
CM_ SG_ 2566722302 GensetEnableActiveStatus "Status of the Genset Enable Relay that enables or disables the Genset.";
CM_ SG_ 2566722302 ReverseCurrentRangeSetting "The operator setting for the Reverse Current.";
CM_ SG_ 2566722302 GensetSoftstartActiveStatus "The Genset Softstart Active Status refers to the status of the genset softstart relay.";
CM_ SG_ 2566722302 Grapple_MagnetSelectionSwitch "This is a switch that can be used to select either the Grapple or Magnet function of the material handler machine.";
CM_ SG_ 2566722302 GnstSystmOtptVoltageRangeStatus "Status of generator voltage in or out of desired operating range.";
CM_ SG_ 2566722302 GeneratorOverheatStatus "The Status of Generator being Overheated.";
CM_ BO_ 2566722558 "Magnet System Configuration Information";
CM_ SG_ 2566722558 MagnetRatedPower "The rated power that the magnet can accept during material holding operations.";
CM_ SG_ 2566722558 MagnetBoostTime "The duration of time after the activation of the magnet circuit that a relatively high current is sent to the magnet for";
CM_ BO_ 2560032510 "Low Voltage Disconnect Set Operating Mode";
CM_ SG_ 2560032510 LwVltgDscnnctDsredOperatingMode "Desired Operating Mode of the LVD.";
CM_ BO_ 2566717950 "Low Voltage Disconnect Status";
CM_ SG_ 2566717950 LowVoltageDisconnectTemp "Internal temperature of the LVD.";
CM_ SG_ 2566717950 LwVltgDisconnectVoutOutputState "State of the Vout Output from the LVD.";
CM_ SG_ 2566717950 LwVoltageDisconnectOutput1State "State of the Output #1 from the LVD.";
CM_ SG_ 2566717950 LwVoltageDisconnectOutput2State "State of the Output #2 from the LVD.";
CM_ SG_ 2566717950 LwVoltageDisconnectOutput3State "State of the Output #3 from the LVD.";
CM_ SG_ 2566717950 LwVltgDscnnctCrrntOperatingMode "Current operating mode of the LVD.";
CM_ SG_ 2566717950 LwVltgDscnnctManualConnectState "State of the Manual Connect hardwired input to the LVD.";
CM_ SG_ 2566717950 LwVltgDscnnctMnlDisconnectState "State of the Manual Disconnect hardwired input to the LVD.";
CM_ BO_ 2499604222 "Land Leveling System Reference Elevation Data";
CM_ SG_ 2499604222 BldRferenceElevationOffsetRight "Indicates the blade's right elevation offset with respect to the reference elevation.";
CM_ SG_ 2499604222 BldReferenceElevationOffsetLeft "Indicates the blade's left elevation offset with respect to the reference elevation.";
CM_ SG_ 2499604222 BladeElevationDeviationRight "Indicate the blade's right elevation deviation with respect to the reference elevation.";
CM_ SG_ 2499604222 BladeElevationDeviationLeft "Indicate the blade's left elevation deviation with respect to the reference elevation.";
CM_ BO_ 2358902526 "Joystick Lamp Command Message";
CM_ SG_ 2358902526 Joystick3Lamp10Cmd "Tells joystick 3 to switch on/off/blinking lamp 10.";
CM_ SG_ 2358902526 Joystick3Lamp9Cmd "Tells joystick 3 to switch on/off/blinking lamp 9.";
CM_ SG_ 2358902526 Joystick3Lamp8Cmd "Tells joystick 3 to switch on/off/blinking lamp 8.";
CM_ SG_ 2358902526 Joystick3Lamp7Cmd "Tells joystick 3 to switch on/off/blinking lamp 7.";
CM_ SG_ 2358902526 Joystick3Lamp6Cmd "Tells joystick 3 to switch on/off/blinking lamp 6.";
CM_ SG_ 2358902526 Joystick3Lamp5Cmd "Tells joystick 3 to switch on/off/blinking lamp 5.";
CM_ SG_ 2358902526 Joystick3Lamp4Cmd "Tells joystick 3 to switch on/off/blinking lamp 4.";
CM_ SG_ 2358902526 Joystick3Lamp3Cmd "Tells joystick 3 to switch on/off/blinking lamp 3.";
CM_ SG_ 2358902526 Joystick3Lamp2Cmd "Tells joystick 3 to switch on/off/blinking lamp 2.";
CM_ SG_ 2358902526 Joystick3Lamp1Cmd "Tells joystick 3 to switch on/off/blinking lamp 1.";
CM_ SG_ 2358902526 Joystick2Lamp10Cmd "Tells joystick 2 to switch on/off/blinking lamp 10.";
CM_ SG_ 2358902526 Joystick2Lamp9Cmd "Tells joystick 2 to switch on/off/blinking lamp 9.";
CM_ SG_ 2358902526 Joystick2Lamp8Cmd "Tells joystick 2 to switch on/off/blinking lamp 8.";
CM_ SG_ 2358902526 Joystick2Lamp7Cmd "Tells joystick 2 to switch on/off/blinking lamp 7.";
CM_ SG_ 2358902526 Joystick2Lamp6Cmd "Tells joystick 2 to switch on/off/blinking lamp 6.";
CM_ SG_ 2358902526 Joystick2Lamp5Cmd "Tells joystick 2 to switch on/off/blinking lamp 5.";
CM_ SG_ 2358902526 Joystick2Lamp4Cmd "Tells joystick 2 to switch on/off/blinking lamp 4.";
CM_ SG_ 2358902526 Joystick2Lamp3Cmd "Tells joystick 2 to switch on/off/blinking lamp 3.";
CM_ SG_ 2358902526 Joystick2Lamp2Cmd "Tells joystick 2 to switch on/off/blinking lamp 2.";
CM_ SG_ 2358902526 Joystick2Lamp1Cmd "Tells joystick 2 to switch on/off/blinking lamp 1.";
CM_ SG_ 2358902526 Joystick1Lamp10Cmd "Tells joystick 1 to switch on/off/blinking lamp 10.";
CM_ SG_ 2358902526 Joystick1Lamp9Cmd "Tells joystick 1 to switch on/off/blinking lamp 9.";
CM_ SG_ 2358902526 Joystick1Lamp8Cmd "Tells joystick 1 to switch on/off/blinking lamp 8.";
CM_ SG_ 2358902526 Joystick1Lamp7Cmd "Tells joystick 1 to switch on/off/blinking lamp 7.";
CM_ SG_ 2358902526 Joystick1Lamp6Cmd "Tells joystick 1 to switch on/off/blinking lamp 6.";
CM_ SG_ 2358902526 Joystick1Lamp5Cmd "Tells joystick 1 to switch on/off/blinking lamp 5.";
CM_ SG_ 2358902526 Joystick1Lamp4Cmd "Tells joystick 1 to switch on/off/blinking lamp 4.";
CM_ SG_ 2358902526 Joystick1Lamp3Cmd "Tells joystick 1 to switch on/off/blinking lamp 3.";
CM_ SG_ 2358902526 Joystick1Lamp2Cmd "Tells joystick 1 to switch on/off/blinking lamp 2.";
CM_ SG_ 2358902526 Joystick1Lamp1Cmd "Tells joystick 1 to switch on/off/blinking lamp 1.";
CM_ BO_ 2566711550 "Intake Valve Actuation Control";
CM_ SG_ 2566711550 IntkVlvActtnSystmOlPrss2SlndCtrl "Indicates the current command to the solenoid that controls the intake valve actuation system oil pressure 2 valve.";
CM_ SG_ 2566711550 IntkVlvActtnSystmOlPrss1SlndCtrl "Indicates the current command to the solenoid that controls the intake valve actuation system oil pressure 1 valve.";
BA_DEF_ SG_  "SigType" ENUM  "Default","Range","RangeSigned","ASCII","Discrete","Control","ReferencePGN","DTC","StringDelimiter","StringLength","StringLengthControl";
BA_DEF_ SG_  "GenSigStartValue" INT 0 10000;
BA_DEF_ SG_  "GenSigSendType" ENUM  "Cyclic","OnWrite","reserved","OnChange","reserved","reserved","reserved","NoSigSendType";
BA_DEF_ SG_  "GenSigILSupport" ENUM  "Yes","No";
BA_DEF_ SG_  "GenSigEVName" STRING ;
BA_DEF_ SG_  "SPN" INT 0 524287;
BA_DEF_ BO_  "GenMsgStartDelayTime" INT 0 100000;
BA_DEF_ BO_  "GenMsgILSupport" ENUM  "Yes","No";
BA_DEF_ BO_  "GenMsgRequestable" INT 0 1;
BA_DEF_ BO_  "GenMsgSendType" ENUM  "cyclic","reserved","cyclicIfActive","reserved","reserved","reserved","reserved","reserved","noMsgSendType";
BA_DEF_ BO_  "VFrameFormat" ENUM  "StandardCAN","ExtendedCAN","reserved","J1939PG";
BA_DEF_ BO_  "GenMsgCycleTime" INT 0 3600000;
BA_DEF_ SG_  "SystemSignalLongSymbol" STRING ;
BA_DEF_DEF_  "SigType" "Default";
BA_DEF_DEF_  "GenSigStartValue" 0;
BA_DEF_DEF_  "GenSigSendType" "NoSigSendType";
BA_DEF_DEF_  "GenSigILSupport" "Yes";
BA_DEF_DEF_  "GenSigEVName" "Env@Nodename_@Signame";
BA_DEF_DEF_  "SPN" 0;
BA_DEF_DEF_  "GenMsgStartDelayTime" 0;
BA_DEF_DEF_  "GenMsgILSupport" "Yes";
BA_DEF_DEF_  "GenMsgRequestable" 1;
BA_DEF_DEF_  "GenMsgSendType" "noMsgSendType";
BA_DEF_DEF_  "VFrameFormat" "J1939PG";
BA_DEF_DEF_  "GenMsgCycleTime" 0;
BA_DEF_DEF_  "SystemSignalLongSymbol" "";
BA_ "GenMsgSendType" BO_ 2566844705 0;
BA_ "GenMsgCycleTime" BO_ 2566844705 100;
BA_ "GenMsgSendType" BO_ 2566844695 0;
BA_ "GenMsgCycleTime" BO_ 2566844695 100;
BA_ "GenMsgSendType" BO_ 2566844689 0;
BA_ "GenMsgCycleTime" BO_ 2566844689 100;
BA_ "GenMsgSendType" BO_ 2566844683 0;
BA_ "GenMsgCycleTime" BO_ 2566844683 100;
BA_ "GenMsgSendType" BO_ 2566844672 0;
BA_ "GenMsgCycleTime" BO_ 2566844672 100;
BA_ "GenMsgSendType" BO_ 2565865513 0;
BA_ "GenMsgCycleTime" BO_ 2565865513 100;
BA_ "GenMsgSendType" BO_ 2565865487 0;
BA_ "GenMsgCycleTime" BO_ 2565865487 100;
BA_ "GenMsgSendType" BO_ 2364539697 0;
BA_ "GenMsgCycleTime" BO_ 2364539697 50;
BA_ "GenMsgSendType" BO_ 2364539681 0;
BA_ "GenMsgCycleTime" BO_ 2364539681 50;
BA_ "GenMsgSendType" BO_ 2364539671 0;
BA_ "GenMsgCycleTime" BO_ 2364539671 50;
BA_ "GenMsgSendType" BO_ 2364539665 0;
BA_ "GenMsgCycleTime" BO_ 2364539665 50;
BA_ "GenMsgSendType" BO_ 2364539648 0;
BA_ "GenMsgCycleTime" BO_ 2364539648 50;
BA_ "GenMsgSendType" BO_ 2566767665 0;
BA_ "GenMsgCycleTime" BO_ 2566767665 100;
BA_ "GenMsgSendType" BO_ 2566767627 0;
BA_ "GenMsgCycleTime" BO_ 2566767627 100;
BA_ "GenMsgSendType" BO_ 2565865777 0;
BA_ "GenMsgCycleTime" BO_ 2565865777 100;
BA_ "GenMsgSendType" BO_ 2565865761 0;
BA_ "GenMsgCycleTime" BO_ 2565865761 100;
BA_ "GenMsgSendType" BO_ 2565865739 0;
BA_ "GenMsgCycleTime" BO_ 2565865739 100;
BA_ "GenMsgSendType" BO_ 2565865728 0;
BA_ "GenMsgCycleTime" BO_ 2565865728 100;
BA_ "GenMsgSendType" BO_ 2297441790 0;
BA_ "GenMsgCycleTime" BO_ 2297441790 10;
BA_ "GenMsgSendType" BO_ 2364549630 0;
BA_ "GenMsgCycleTime" BO_ 2364549630 10;
BA_ "GenMsgSendType" BO_ 2297441534 0;
BA_ "GenMsgCycleTime" BO_ 2297441534 50;
BA_ "GenMsgSendType" BO_ 2566722302 0;
BA_ "GenMsgCycleTime" BO_ 2566722302 500;
BA_ "GenMsgSendType" BO_ 2566717950 0;
BA_ "GenMsgCycleTime" BO_ 2566717950 500;
BA_ "GenMsgSendType" BO_ 2499604222 0;
BA_ "GenMsgCycleTime" BO_ 2499604222 200;
BA_ "GenMsgSendType" BO_ 2358902526 0;
BA_ "GenMsgCycleTime" BO_ 2358902526 100;
BA_ "GenMsgSendType" BO_ 2566711550 0;
BA_ "GenMsgCycleTime" BO_ 2566711550 500;
BA_ "SigType" SG_ 2566844705 ParkBrakeReleaseInhibitRq 4;
BA_ "SPN" SG_ 2566844705 ParkBrakeReleaseInhibitRq 3807;
BA_ "SigType" SG_ 2566844705 PTOGovernorState 4;
BA_ "SPN" SG_ 2566844705 PTOGovernorState 976;
BA_ "SigType" SG_ 2566844705 EngShutdownOverrideSwitch 4;
BA_ "SPN" SG_ 2566844705 EngShutdownOverrideSwitch 1237;
BA_ "SigType" SG_ 2566844705 EngTestModeSwitch 4;
BA_ "SPN" SG_ 2566844705 EngTestModeSwitch 966;
BA_ "SigType" SG_ 2566844705 EngIdleDecrementSwitch 4;
BA_ "SPN" SG_ 2566844705 EngIdleDecrementSwitch 967;
BA_ "SigType" SG_ 2566844705 EngIdleIncrementSwitch 4;
BA_ "SPN" SG_ 2566844705 EngIdleIncrementSwitch 968;
BA_ "SPN" SG_ 2566844705 CruiseCtrlStates 527;
BA_ "SigType" SG_ 2566844705 CruiseCtrlSetSpeed 1;
BA_ "SPN" SG_ 2566844705 CruiseCtrlSetSpeed 86;
BA_ "SigType" SG_ 2566844705 CruiseCtrlAccelerateSwitch 4;
BA_ "SPN" SG_ 2566844705 CruiseCtrlAccelerateSwitch 602;
BA_ "SigType" SG_ 2566844705 CruiseCtrlResumeSwitch 4;
BA_ "SPN" SG_ 2566844705 CruiseCtrlResumeSwitch 601;
BA_ "SigType" SG_ 2566844705 CruiseCtrlCoastSwitch 4;
BA_ "SPN" SG_ 2566844705 CruiseCtrlCoastSwitch 600;
BA_ "SigType" SG_ 2566844705 CruiseCtrlSetSwitch 4;
BA_ "SPN" SG_ 2566844705 CruiseCtrlSetSwitch 599;
BA_ "SigType" SG_ 2566844705 ClutchSwitch 4;
BA_ "SPN" SG_ 2566844705 ClutchSwitch 598;
BA_ "SigType" SG_ 2566844705 BrakeSwitch_SA21 4;
BA_ "SPN" SG_ 2566844705 BrakeSwitch_SA21 597;
BA_ "SigType" SG_ 2566844705 CruiseCtrlEnableSwitch 4;
BA_ "SPN" SG_ 2566844705 CruiseCtrlEnableSwitch 596;
BA_ "SigType" SG_ 2566844705 CruiseCtrlActive 4;
BA_ "SPN" SG_ 2566844705 CruiseCtrlActive 595;
BA_ "SigType" SG_ 2566844705 WheelBasedVehicleSpeed 1;
BA_ "SPN" SG_ 2566844705 WheelBasedVehicleSpeed 84;
BA_ "SigType" SG_ 2566844705 CruiseCtrlPauseSwitch 4;
BA_ "SPN" SG_ 2566844705 CruiseCtrlPauseSwitch 1633;
BA_ "SigType" SG_ 2566844705 ParkingBrakeSwitch 4;
BA_ "SPN" SG_ 2566844705 ParkingBrakeSwitch 70;
BA_ "SigType" SG_ 2566844705 TwoSpeedAxleSwitch 4;
BA_ "SPN" SG_ 2566844705 TwoSpeedAxleSwitch 69;
BA_ "SigType" SG_ 2566844695 ParkBrakeReleaseInhibitRq 4;
BA_ "SPN" SG_ 2566844695 ParkBrakeReleaseInhibitRq 3807;
BA_ "SigType" SG_ 2566844695 PTOGovernorState 4;
BA_ "SPN" SG_ 2566844695 PTOGovernorState 976;
BA_ "SigType" SG_ 2566844695 EngShutdownOverrideSwitch 4;
BA_ "SPN" SG_ 2566844695 EngShutdownOverrideSwitch 1237;
BA_ "SigType" SG_ 2566844695 EngTestModeSwitch 4;
BA_ "SPN" SG_ 2566844695 EngTestModeSwitch 966;
BA_ "SigType" SG_ 2566844695 EngIdleDecrementSwitch 4;
BA_ "SPN" SG_ 2566844695 EngIdleDecrementSwitch 967;
BA_ "SigType" SG_ 2566844695 EngIdleIncrementSwitch 4;
BA_ "SPN" SG_ 2566844695 EngIdleIncrementSwitch 968;
BA_ "SPN" SG_ 2566844695 CruiseCtrlStates 527;
BA_ "SigType" SG_ 2566844695 CruiseCtrlSetSpeed 1;
BA_ "SPN" SG_ 2566844695 CruiseCtrlSetSpeed 86;
BA_ "SigType" SG_ 2566844695 CruiseCtrlAccelerateSwitch 4;
BA_ "SPN" SG_ 2566844695 CruiseCtrlAccelerateSwitch 602;
BA_ "SigType" SG_ 2566844695 CruiseCtrlResumeSwitch 4;
BA_ "SPN" SG_ 2566844695 CruiseCtrlResumeSwitch 601;
BA_ "SigType" SG_ 2566844695 CruiseCtrlCoastSwitch 4;
BA_ "SPN" SG_ 2566844695 CruiseCtrlCoastSwitch 600;
BA_ "SigType" SG_ 2566844695 CruiseCtrlSetSwitch 4;
BA_ "SPN" SG_ 2566844695 CruiseCtrlSetSwitch 599;
BA_ "SigType" SG_ 2566844695 ClutchSwitch 4;
BA_ "SPN" SG_ 2566844695 ClutchSwitch 598;
BA_ "SigType" SG_ 2566844695 BrakeSwitch_SA17 4;
BA_ "SPN" SG_ 2566844695 BrakeSwitch_SA17 597;
BA_ "SigType" SG_ 2566844695 CruiseCtrlEnableSwitch 4;
BA_ "SPN" SG_ 2566844695 CruiseCtrlEnableSwitch 596;
BA_ "SigType" SG_ 2566844695 CruiseCtrlActive 4;
BA_ "SPN" SG_ 2566844695 CruiseCtrlActive 595;
BA_ "SigType" SG_ 2566844695 WheelBasedVehicleSpeed 1;
BA_ "SPN" SG_ 2566844695 WheelBasedVehicleSpeed 84;
BA_ "SigType" SG_ 2566844695 CruiseCtrlPauseSwitch 4;
BA_ "SPN" SG_ 2566844695 CruiseCtrlPauseSwitch 1633;
BA_ "SigType" SG_ 2566844695 ParkingBrakeSwitch 4;
BA_ "SPN" SG_ 2566844695 ParkingBrakeSwitch 70;
BA_ "SigType" SG_ 2566844695 TwoSpeedAxleSwitch 4;
BA_ "SPN" SG_ 2566844695 TwoSpeedAxleSwitch 69;
BA_ "SigType" SG_ 2566844689 ParkBrakeReleaseInhibitRq 4;
BA_ "SPN" SG_ 2566844689 ParkBrakeReleaseInhibitRq 3807;
BA_ "SigType" SG_ 2566844689 PTOGovernorState 4;
BA_ "SPN" SG_ 2566844689 PTOGovernorState 976;
BA_ "SigType" SG_ 2566844689 EngShutdownOverrideSwitch 4;
BA_ "SPN" SG_ 2566844689 EngShutdownOverrideSwitch 1237;
BA_ "SigType" SG_ 2566844689 EngTestModeSwitch 4;
BA_ "SPN" SG_ 2566844689 EngTestModeSwitch 966;
BA_ "SigType" SG_ 2566844689 EngIdleDecrementSwitch 4;
BA_ "SPN" SG_ 2566844689 EngIdleDecrementSwitch 967;
BA_ "SigType" SG_ 2566844689 EngIdleIncrementSwitch 4;
BA_ "SPN" SG_ 2566844689 EngIdleIncrementSwitch 968;
BA_ "SPN" SG_ 2566844689 CruiseCtrlStates 527;
BA_ "SigType" SG_ 2566844689 CruiseCtrlSetSpeed 1;
BA_ "SPN" SG_ 2566844689 CruiseCtrlSetSpeed 86;
BA_ "SigType" SG_ 2566844689 CruiseCtrlAccelerateSwitch 4;
BA_ "SPN" SG_ 2566844689 CruiseCtrlAccelerateSwitch 602;
BA_ "SigType" SG_ 2566844689 CruiseCtrlResumeSwitch 4;
BA_ "SPN" SG_ 2566844689 CruiseCtrlResumeSwitch 601;
BA_ "SigType" SG_ 2566844689 CruiseCtrlCoastSwitch 4;
BA_ "SPN" SG_ 2566844689 CruiseCtrlCoastSwitch 600;
BA_ "SigType" SG_ 2566844689 CruiseCtrlSetSwitch 4;
BA_ "SPN" SG_ 2566844689 CruiseCtrlSetSwitch 599;
BA_ "SigType" SG_ 2566844689 ClutchSwitch 4;
BA_ "SPN" SG_ 2566844689 ClutchSwitch 598;
BA_ "SigType" SG_ 2566844689 BrakeSwitch_SA11 4;
BA_ "SPN" SG_ 2566844689 BrakeSwitch_SA11 597;
BA_ "SigType" SG_ 2566844689 CruiseCtrlEnableSwitch 4;
BA_ "SPN" SG_ 2566844689 CruiseCtrlEnableSwitch 596;
BA_ "SigType" SG_ 2566844689 CruiseCtrlActive 4;
BA_ "SPN" SG_ 2566844689 CruiseCtrlActive 595;
BA_ "SigType" SG_ 2566844689 WheelBasedVehicleSpeed 1;
BA_ "SPN" SG_ 2566844689 WheelBasedVehicleSpeed 84;
BA_ "SigType" SG_ 2566844689 CruiseCtrlPauseSwitch 4;
BA_ "SPN" SG_ 2566844689 CruiseCtrlPauseSwitch 1633;
BA_ "SigType" SG_ 2566844689 ParkingBrakeSwitch 4;
BA_ "SPN" SG_ 2566844689 ParkingBrakeSwitch 70;
BA_ "SigType" SG_ 2566844689 TwoSpeedAxleSwitch 4;
BA_ "SPN" SG_ 2566844689 TwoSpeedAxleSwitch 69;
BA_ "SigType" SG_ 2566844683 ParkBrakeReleaseInhibitRq 4;
BA_ "SPN" SG_ 2566844683 ParkBrakeReleaseInhibitRq 3807;
BA_ "SigType" SG_ 2566844683 PTOGovernorState 4;
BA_ "SPN" SG_ 2566844683 PTOGovernorState 976;
BA_ "SigType" SG_ 2566844683 EngShutdownOverrideSwitch 4;
BA_ "SPN" SG_ 2566844683 EngShutdownOverrideSwitch 1237;
BA_ "SigType" SG_ 2566844683 EngTestModeSwitch 4;
BA_ "SPN" SG_ 2566844683 EngTestModeSwitch 966;
BA_ "SigType" SG_ 2566844683 EngIdleDecrementSwitch 4;
BA_ "SPN" SG_ 2566844683 EngIdleDecrementSwitch 967;
BA_ "SigType" SG_ 2566844683 EngIdleIncrementSwitch 4;
BA_ "SPN" SG_ 2566844683 EngIdleIncrementSwitch 968;
BA_ "SPN" SG_ 2566844683 CruiseCtrlStates 527;
BA_ "SigType" SG_ 2566844683 CruiseCtrlSetSpeed 1;
BA_ "SPN" SG_ 2566844683 CruiseCtrlSetSpeed 86;
BA_ "SigType" SG_ 2566844683 CruiseCtrlAccelerateSwitch 4;
BA_ "SPN" SG_ 2566844683 CruiseCtrlAccelerateSwitch 602;
BA_ "SigType" SG_ 2566844683 CruiseCtrlResumeSwitch 4;
BA_ "SPN" SG_ 2566844683 CruiseCtrlResumeSwitch 601;
BA_ "SigType" SG_ 2566844683 CruiseCtrlCoastSwitch 4;
BA_ "SPN" SG_ 2566844683 CruiseCtrlCoastSwitch 600;
BA_ "SigType" SG_ 2566844683 CruiseCtrlSetSwitch 4;
BA_ "SPN" SG_ 2566844683 CruiseCtrlSetSwitch 599;
BA_ "SigType" SG_ 2566844683 ClutchSwitch 4;
BA_ "SPN" SG_ 2566844683 ClutchSwitch 598;
BA_ "SigType" SG_ 2566844683 BrakeSwitch_SA0B 4;
BA_ "SPN" SG_ 2566844683 BrakeSwitch_SA0B 597;
BA_ "SigType" SG_ 2566844683 CruiseCtrlEnableSwitch 4;
BA_ "SPN" SG_ 2566844683 CruiseCtrlEnableSwitch 596;
BA_ "SigType" SG_ 2566844683 CruiseCtrlActive 4;
BA_ "SPN" SG_ 2566844683 CruiseCtrlActive 595;
BA_ "SigType" SG_ 2566844683 WheelBasedVehicleSpeed 1;
BA_ "SPN" SG_ 2566844683 WheelBasedVehicleSpeed 84;
BA_ "SigType" SG_ 2566844683 CruiseCtrlPauseSwitch 4;
BA_ "SPN" SG_ 2566844683 CruiseCtrlPauseSwitch 1633;
BA_ "SigType" SG_ 2566844683 ParkingBrakeSwitch 4;
BA_ "SPN" SG_ 2566844683 ParkingBrakeSwitch 70;
BA_ "SigType" SG_ 2566844683 TwoSpeedAxleSwitch 4;
BA_ "SPN" SG_ 2566844683 TwoSpeedAxleSwitch 69;
BA_ "SigType" SG_ 2566844672 ParkBrakeReleaseInhibitRq 4;
BA_ "SPN" SG_ 2566844672 ParkBrakeReleaseInhibitRq 3807;
BA_ "SigType" SG_ 2566844672 PTOGovernorState 4;
BA_ "SPN" SG_ 2566844672 PTOGovernorState 976;
BA_ "SigType" SG_ 2566844672 EngShutdownOverrideSwitch 4;
BA_ "SPN" SG_ 2566844672 EngShutdownOverrideSwitch 1237;
BA_ "SigType" SG_ 2566844672 EngTestModeSwitch 4;
BA_ "SPN" SG_ 2566844672 EngTestModeSwitch 966;
BA_ "SigType" SG_ 2566844672 EngIdleDecrementSwitch 4;
BA_ "SPN" SG_ 2566844672 EngIdleDecrementSwitch 967;
BA_ "SigType" SG_ 2566844672 EngIdleIncrementSwitch 4;
BA_ "SPN" SG_ 2566844672 EngIdleIncrementSwitch 968;
BA_ "SPN" SG_ 2566844672 CruiseCtrlStates 527;
BA_ "SigType" SG_ 2566844672 CruiseCtrlSetSpeed 1;
BA_ "SPN" SG_ 2566844672 CruiseCtrlSetSpeed 86;
BA_ "SigType" SG_ 2566844672 CruiseCtrlAccelerateSwitch 4;
BA_ "SPN" SG_ 2566844672 CruiseCtrlAccelerateSwitch 602;
BA_ "SigType" SG_ 2566844672 CruiseCtrlResumeSwitch 4;
BA_ "SPN" SG_ 2566844672 CruiseCtrlResumeSwitch 601;
BA_ "SigType" SG_ 2566844672 CruiseCtrlCoastSwitch 4;
BA_ "SPN" SG_ 2566844672 CruiseCtrlCoastSwitch 600;
BA_ "SigType" SG_ 2566844672 CruiseCtrlSetSwitch 4;
BA_ "SPN" SG_ 2566844672 CruiseCtrlSetSwitch 599;
BA_ "SigType" SG_ 2566844672 ClutchSwitch 4;
BA_ "SPN" SG_ 2566844672 ClutchSwitch 598;
BA_ "SigType" SG_ 2566844672 BrakeSwitch_SA00 4;
BA_ "SPN" SG_ 2566844672 BrakeSwitch_SA00 597;
BA_ "SigType" SG_ 2566844672 CruiseCtrlEnableSwitch 4;
BA_ "SPN" SG_ 2566844672 CruiseCtrlEnableSwitch 596;
BA_ "SigType" SG_ 2566844672 CruiseCtrlActive 4;
BA_ "SPN" SG_ 2566844672 CruiseCtrlActive 595;
BA_ "SigType" SG_ 2566844672 WheelBasedVehicleSpeed 1;
BA_ "SPN" SG_ 2566844672 WheelBasedVehicleSpeed 84;
BA_ "SigType" SG_ 2566844672 CruiseCtrlPauseSwitch 4;
BA_ "SPN" SG_ 2566844672 CruiseCtrlPauseSwitch 1633;
BA_ "SigType" SG_ 2566844672 ParkingBrakeSwitch 4;
BA_ "SPN" SG_ 2566844672 ParkingBrakeSwitch 70;
BA_ "SigType" SG_ 2566844672 TwoSpeedAxleSwitch 4;
BA_ "SPN" SG_ 2566844672 TwoSpeedAxleSwitch 69;
BA_ "SigType" SG_ 2565865513 RetarderSelectionNonEng 1;
BA_ "SPN" SG_ 2565865513 RetarderSelectionNonEng 1716;
BA_ "SigType" SG_ 2565865513 SrcAddrssOfCtrllngDvcFrRtrdrCntr 1;
BA_ "SPN" SG_ 2565865513 SrcAddrssOfCtrllngDvcFrRtrdrCntr 1480;
BA_ "SystemSignalLongSymbol" SG_ 2565865513 SrcAddrssOfCtrllngDvcFrRtrdrCntr "SrcAddrssOfCtrllngDvcFrRtrdrCntrl";
BA_ "SigType" SG_ 2565865513 RetarderRoadSpeedLimitSwitch 4;
BA_ "SPN" SG_ 2565865513 RetarderRoadSpeedLimitSwitch 4233;
BA_ "SigType" SG_ 2565865513 RetarderRoadSpeedExceededStatus 4;
BA_ "SPN" SG_ 2565865513 RetarderRoadSpeedExceededStatus 4234;
BA_ "SigType" SG_ 2565865513 ActlMxAvlblRtarderPercentTorque 1;
BA_ "SPN" SG_ 2565865513 ActlMxAvlblRtarderPercentTorque 1717;
BA_ "SigType" SG_ 2565865513 DrvrsDmandRetarderPercentTorque 1;
BA_ "SPN" SG_ 2565865513 DrvrsDmandRetarderPercentTorque 1715;
BA_ "SigType" SG_ 2565865513 RetarderRqingBrakeLight 4;
BA_ "SPN" SG_ 2565865513 RetarderRqingBrakeLight 1667;
BA_ "SigType" SG_ 2565865513 EngCoolantLoadIncrease 4;
BA_ "SPN" SG_ 2565865513 EngCoolantLoadIncrease 1082;
BA_ "SigType" SG_ 2565865513 IntendedRetarderPercentTorque 1;
BA_ "SPN" SG_ 2565865513 IntendedRetarderPercentTorque 1085;
BA_ "SigType" SG_ 2565865513 ActualRetarderPercentTorque 1;
BA_ "SPN" SG_ 2565865513 ActualRetarderPercentTorque 520;
BA_ "SigType" SG_ 2565865513 RetarderEnableShiftAssistSwitch 4;
BA_ "SPN" SG_ 2565865513 RetarderEnableShiftAssistSwitch 572;
BA_ "SigType" SG_ 2565865513 RetarderEnableBrakeAssistSwitch 4;
BA_ "SPN" SG_ 2565865513 RetarderEnableBrakeAssistSwitch 571;
BA_ "SigType" SG_ 2565865513 RetarderTorqueMode 4;
BA_ "SPN" SG_ 2565865513 RetarderTorqueMode 900;
BA_ "SigType" SG_ 2565865487 RetarderSelectionNonEng 1;
BA_ "SPN" SG_ 2565865487 RetarderSelectionNonEng 1716;
BA_ "SigType" SG_ 2565865487 SrcAddrssOfCtrllngDvcFrRtrd_0000 1;
BA_ "SPN" SG_ 2565865487 SrcAddrssOfCtrllngDvcFrRtrd_0000 1480;
BA_ "SystemSignalLongSymbol" SG_ 2565865487 SrcAddrssOfCtrllngDvcFrRtrd_0000 "SrcAddrssOfCtrllngDvcFrRtrdrCntrl";
BA_ "SigType" SG_ 2565865487 RetarderRoadSpeedLimitSwitch 4;
BA_ "SPN" SG_ 2565865487 RetarderRoadSpeedLimitSwitch 4233;
BA_ "SigType" SG_ 2565865487 RetarderRoadSpeedExceededStatus 4;
BA_ "SPN" SG_ 2565865487 RetarderRoadSpeedExceededStatus 4234;
BA_ "SigType" SG_ 2565865487 ActlMxAvlblRtarderPercentTorque 1;
BA_ "SPN" SG_ 2565865487 ActlMxAvlblRtarderPercentTorque 1717;
BA_ "SigType" SG_ 2565865487 DrvrsDmandRetarderPercentTorque 1;
BA_ "SPN" SG_ 2565865487 DrvrsDmandRetarderPercentTorque 1715;
BA_ "SigType" SG_ 2565865487 RetarderRqingBrakeLight 4;
BA_ "SPN" SG_ 2565865487 RetarderRqingBrakeLight 1667;
BA_ "SigType" SG_ 2565865487 EngCoolantLoadIncrease 4;
BA_ "SPN" SG_ 2565865487 EngCoolantLoadIncrease 1082;
BA_ "SigType" SG_ 2565865487 IntendedRetarderPercentTorque 1;
BA_ "SPN" SG_ 2565865487 IntendedRetarderPercentTorque 1085;
BA_ "SigType" SG_ 2565865487 ActualRetarderPercentTorque 1;
BA_ "SPN" SG_ 2565865487 ActualRetarderPercentTorque 520;
BA_ "SigType" SG_ 2565865487 RetarderEnableShiftAssistSwitch 4;
BA_ "SPN" SG_ 2565865487 RetarderEnableShiftAssistSwitch 572;
BA_ "SigType" SG_ 2565865487 RetarderEnableBrakeAssistSwitch 4;
BA_ "SPN" SG_ 2565865487 RetarderEnableBrakeAssistSwitch 571;
BA_ "SigType" SG_ 2565865487 RetarderTorqueMode 4;
BA_ "SPN" SG_ 2565865487 RetarderTorqueMode 900;
BA_ "SigType" SG_ 2364539697 SCRThermalManagementActive 4;
BA_ "SPN" SG_ 2364539697 SCRThermalManagementActive 5400;
BA_ "SigType" SG_ 2364539697 MmntryEngMaxPowerEnableFeedback 4;
BA_ "SPN" SG_ 2364539697 MmntryEngMaxPowerEnableFeedback 5021;
BA_ "SigType" SG_ 2364539697 EstPumpingPercentTorque 1;
BA_ "SPN" SG_ 2364539697 EstPumpingPercentTorque 5398;
BA_ "SigType" SG_ 2364539697 DPFThermalManagementActive 4;
BA_ "SPN" SG_ 2364539697 DPFThermalManagementActive 5399;
BA_ "SigType" SG_ 2364539697 ActlMxAvailableEngPercentTorque 1;
BA_ "SPN" SG_ 2364539697 ActlMxAvailableEngPercentTorque 3357;
BA_ "SigType" SG_ 2364539697 AccelPedalPos2 1;
BA_ "SPN" SG_ 2364539697 AccelPedalPos2 29;
BA_ "SigType" SG_ 2364539697 VhclAccelerationRateLimitStatus 4;
BA_ "SPN" SG_ 2364539697 VhclAccelerationRateLimitStatus 2979;
BA_ "SigType" SG_ 2364539697 EngPercentLoadAtCurrentSpeed 1;
BA_ "SPN" SG_ 2364539697 EngPercentLoadAtCurrentSpeed 92;
BA_ "SigType" SG_ 2364539697 AccelPedal2LowIdleSwitch 4;
BA_ "SPN" SG_ 2364539697 AccelPedal2LowIdleSwitch 2970;
BA_ "SigType" SG_ 2364539697 RoadSpeedLimitStatus 4;
BA_ "SPN" SG_ 2364539697 RoadSpeedLimitStatus 1437;
BA_ "SigType" SG_ 2364539697 AccelPedalKickdownSwitch 4;
BA_ "SPN" SG_ 2364539697 AccelPedalKickdownSwitch 559;
BA_ "SigType" SG_ 2364539697 AccelPedal1LowIdleSwitch 4;
BA_ "SPN" SG_ 2364539697 AccelPedal1LowIdleSwitch 558;
BA_ "SigType" SG_ 2364539697 RemoteAccelPedalPos 1;
BA_ "SPN" SG_ 2364539697 RemoteAccelPedalPos 974;
BA_ "SigType" SG_ 2364539697 AccelPedalPos1_SA31 1;
BA_ "SPN" SG_ 2364539697 AccelPedalPos1_SA31 91;
BA_ "SigType" SG_ 2364539681 SCRThermalManagementActive 4;
BA_ "SPN" SG_ 2364539681 SCRThermalManagementActive 5400;
BA_ "SigType" SG_ 2364539681 MmntryEngMaxPowerEnableFeedback 4;
BA_ "SPN" SG_ 2364539681 MmntryEngMaxPowerEnableFeedback 5021;
BA_ "SigType" SG_ 2364539681 EstPumpingPercentTorque 1;
BA_ "SPN" SG_ 2364539681 EstPumpingPercentTorque 5398;
BA_ "SigType" SG_ 2364539681 DPFThermalManagementActive 4;
BA_ "SPN" SG_ 2364539681 DPFThermalManagementActive 5399;
BA_ "SigType" SG_ 2364539681 ActlMxAvailableEngPercentTorque 1;
BA_ "SPN" SG_ 2364539681 ActlMxAvailableEngPercentTorque 3357;
BA_ "SigType" SG_ 2364539681 AccelPedalPos2 1;
BA_ "SPN" SG_ 2364539681 AccelPedalPos2 29;
BA_ "SigType" SG_ 2364539681 VhclAccelerationRateLimitStatus 4;
BA_ "SPN" SG_ 2364539681 VhclAccelerationRateLimitStatus 2979;
BA_ "SigType" SG_ 2364539681 EngPercentLoadAtCurrentSpeed 1;
BA_ "SPN" SG_ 2364539681 EngPercentLoadAtCurrentSpeed 92;
BA_ "SigType" SG_ 2364539681 AccelPedal2LowIdleSwitch 4;
BA_ "SPN" SG_ 2364539681 AccelPedal2LowIdleSwitch 2970;
BA_ "SigType" SG_ 2364539681 RoadSpeedLimitStatus 4;
BA_ "SPN" SG_ 2364539681 RoadSpeedLimitStatus 1437;
BA_ "SigType" SG_ 2364539681 AccelPedalKickdownSwitch 4;
BA_ "SPN" SG_ 2364539681 AccelPedalKickdownSwitch 559;
BA_ "SigType" SG_ 2364539681 AccelPedal1LowIdleSwitch 4;
BA_ "SPN" SG_ 2364539681 AccelPedal1LowIdleSwitch 558;
BA_ "SigType" SG_ 2364539681 RemoteAccelPedalPos 1;
BA_ "SPN" SG_ 2364539681 RemoteAccelPedalPos 974;
BA_ "SigType" SG_ 2364539681 AccelPedalPos1_SA21 1;
BA_ "SPN" SG_ 2364539681 AccelPedalPos1_SA21 91;
BA_ "SigType" SG_ 2364539671 SCRThermalManagementActive 4;
BA_ "SPN" SG_ 2364539671 SCRThermalManagementActive 5400;
BA_ "SigType" SG_ 2364539671 MmntryEngMaxPowerEnableFeedback 4;
BA_ "SPN" SG_ 2364539671 MmntryEngMaxPowerEnableFeedback 5021;
BA_ "SigType" SG_ 2364539671 EstPumpingPercentTorque 1;
BA_ "SPN" SG_ 2364539671 EstPumpingPercentTorque 5398;
BA_ "SigType" SG_ 2364539671 DPFThermalManagementActive 4;
BA_ "SPN" SG_ 2364539671 DPFThermalManagementActive 5399;
BA_ "SigType" SG_ 2364539671 ActlMxAvailableEngPercentTorque 1;
BA_ "SPN" SG_ 2364539671 ActlMxAvailableEngPercentTorque 3357;
BA_ "SigType" SG_ 2364539671 AccelPedalPos2 1;
BA_ "SPN" SG_ 2364539671 AccelPedalPos2 29;
BA_ "SigType" SG_ 2364539671 VhclAccelerationRateLimitStatus 4;
BA_ "SPN" SG_ 2364539671 VhclAccelerationRateLimitStatus 2979;
BA_ "SigType" SG_ 2364539671 EngPercentLoadAtCurrentSpeed 1;
BA_ "SPN" SG_ 2364539671 EngPercentLoadAtCurrentSpeed 92;
BA_ "SigType" SG_ 2364539671 AccelPedal2LowIdleSwitch 4;
BA_ "SPN" SG_ 2364539671 AccelPedal2LowIdleSwitch 2970;
BA_ "SigType" SG_ 2364539671 RoadSpeedLimitStatus 4;
BA_ "SPN" SG_ 2364539671 RoadSpeedLimitStatus 1437;
BA_ "SigType" SG_ 2364539671 AccelPedalKickdownSwitch 4;
BA_ "SPN" SG_ 2364539671 AccelPedalKickdownSwitch 559;
BA_ "SigType" SG_ 2364539671 AccelPedal1LowIdleSwitch 4;
BA_ "SPN" SG_ 2364539671 AccelPedal1LowIdleSwitch 558;
BA_ "SigType" SG_ 2364539671 RemoteAccelPedalPos 1;
BA_ "SPN" SG_ 2364539671 RemoteAccelPedalPos 974;
BA_ "SigType" SG_ 2364539671 AccelPedalPos1_SA17 1;
BA_ "SPN" SG_ 2364539671 AccelPedalPos1_SA17 91;
BA_ "SigType" SG_ 2364539665 SCRThermalManagementActive 4;
BA_ "SPN" SG_ 2364539665 SCRThermalManagementActive 5400;
BA_ "SigType" SG_ 2364539665 MmntryEngMaxPowerEnableFeedback 4;
BA_ "SPN" SG_ 2364539665 MmntryEngMaxPowerEnableFeedback 5021;
BA_ "SigType" SG_ 2364539665 EstPumpingPercentTorque 1;
BA_ "SPN" SG_ 2364539665 EstPumpingPercentTorque 5398;
BA_ "SigType" SG_ 2364539665 DPFThermalManagementActive 4;
BA_ "SPN" SG_ 2364539665 DPFThermalManagementActive 5399;
BA_ "SigType" SG_ 2364539665 ActlMxAvailableEngPercentTorque 1;
BA_ "SPN" SG_ 2364539665 ActlMxAvailableEngPercentTorque 3357;
BA_ "SigType" SG_ 2364539665 AccelPedalPos2 1;
BA_ "SPN" SG_ 2364539665 AccelPedalPos2 29;
BA_ "SigType" SG_ 2364539665 VhclAccelerationRateLimitStatus 4;
BA_ "SPN" SG_ 2364539665 VhclAccelerationRateLimitStatus 2979;
BA_ "SigType" SG_ 2364539665 EngPercentLoadAtCurrentSpeed 1;
BA_ "SPN" SG_ 2364539665 EngPercentLoadAtCurrentSpeed 92;
BA_ "SigType" SG_ 2364539665 AccelPedal2LowIdleSwitch 4;
BA_ "SPN" SG_ 2364539665 AccelPedal2LowIdleSwitch 2970;
BA_ "SigType" SG_ 2364539665 RoadSpeedLimitStatus 4;
BA_ "SPN" SG_ 2364539665 RoadSpeedLimitStatus 1437;
BA_ "SigType" SG_ 2364539665 AccelPedalKickdownSwitch 4;
BA_ "SPN" SG_ 2364539665 AccelPedalKickdownSwitch 559;
BA_ "SigType" SG_ 2364539665 AccelPedal1LowIdleSwitch 4;
BA_ "SPN" SG_ 2364539665 AccelPedal1LowIdleSwitch 558;
BA_ "SigType" SG_ 2364539665 RemoteAccelPedalPos 1;
BA_ "SPN" SG_ 2364539665 RemoteAccelPedalPos 974;
BA_ "SigType" SG_ 2364539665 AccelPedalPos1_SA11 1;
BA_ "SPN" SG_ 2364539665 AccelPedalPos1_SA11 91;
BA_ "SigType" SG_ 2364539648 SCRThermalManagementActive 4;
BA_ "SPN" SG_ 2364539648 SCRThermalManagementActive 5400;
BA_ "SigType" SG_ 2364539648 MmntryEngMaxPowerEnableFeedback 4;
BA_ "SPN" SG_ 2364539648 MmntryEngMaxPowerEnableFeedback 5021;
BA_ "SigType" SG_ 2364539648 EstPumpingPercentTorque 1;
BA_ "SPN" SG_ 2364539648 EstPumpingPercentTorque 5398;
BA_ "SigType" SG_ 2364539648 DPFThermalManagementActive 4;
BA_ "SPN" SG_ 2364539648 DPFThermalManagementActive 5399;
BA_ "SigType" SG_ 2364539648 ActlMxAvailableEngPercentTorque 1;
BA_ "SPN" SG_ 2364539648 ActlMxAvailableEngPercentTorque 3357;
BA_ "SigType" SG_ 2364539648 AccelPedalPos2 1;
BA_ "SPN" SG_ 2364539648 AccelPedalPos2 29;
BA_ "SigType" SG_ 2364539648 VhclAccelerationRateLimitStatus 4;
BA_ "SPN" SG_ 2364539648 VhclAccelerationRateLimitStatus 2979;
BA_ "SigType" SG_ 2364539648 EngPercentLoadAtCurrentSpeed 1;
BA_ "SPN" SG_ 2364539648 EngPercentLoadAtCurrentSpeed 92;
BA_ "SigType" SG_ 2364539648 AccelPedal2LowIdleSwitch 4;
BA_ "SPN" SG_ 2364539648 AccelPedal2LowIdleSwitch 2970;
BA_ "SigType" SG_ 2364539648 RoadSpeedLimitStatus 4;
BA_ "SPN" SG_ 2364539648 RoadSpeedLimitStatus 1437;
BA_ "SigType" SG_ 2364539648 AccelPedalKickdownSwitch 4;
BA_ "SPN" SG_ 2364539648 AccelPedalKickdownSwitch 559;
BA_ "SigType" SG_ 2364539648 AccelPedal1LowIdleSwitch 4;
BA_ "SPN" SG_ 2364539648 AccelPedal1LowIdleSwitch 558;
BA_ "SigType" SG_ 2364539648 RemoteAccelPedalPos 1;
BA_ "SPN" SG_ 2364539648 RemoteAccelPedalPos 974;
BA_ "SigType" SG_ 2364539648 AccelPedalPos1_SA00 1;
BA_ "SPN" SG_ 2364539648 AccelPedalPos1_SA00 91;
BA_ "SigType" SG_ 2566767665 BrakeTempWarning 4;
BA_ "SPN" SG_ 2566767665 BrakeTempWarning 3839;
BA_ "SigType" SG_ 2566767665 PrkngBrkeActuatorFullyActivated 4;
BA_ "SPN" SG_ 2566767665 PrkngBrkeActuatorFullyActivated 5275;
BA_ "SigType" SG_ 2566767665 XBRAccelerationLimit 1;
BA_ "SPN" SG_ 2566767665 XBRAccelerationLimit 2921;
BA_ "SigType" SG_ 2566767665 XBRActiveCtrlMode 4;
BA_ "SPN" SG_ 2566767665 XBRActiveCtrlMode 2918;
BA_ "SigType" SG_ 2566767665 XBRSystemState 4;
BA_ "SPN" SG_ 2566767665 XBRSystemState 2917;
BA_ "SigType" SG_ 2566767665 FoundationBrakeUse 4;
BA_ "SPN" SG_ 2566767665 FoundationBrakeUse 2919;
BA_ "SPN" SG_ 2566767665 HillHolderMode 2912;
BA_ "SPN" SG_ 2566767665 HaltBrakeMode 2913;
BA_ "SigType" SG_ 2566767627 BrakeTempWarning 4;
BA_ "SPN" SG_ 2566767627 BrakeTempWarning 3839;
BA_ "SigType" SG_ 2566767627 PrkngBrkeActuatorFullyActivated 4;
BA_ "SPN" SG_ 2566767627 PrkngBrkeActuatorFullyActivated 5275;
BA_ "SigType" SG_ 2566767627 XBRAccelerationLimit 1;
BA_ "SPN" SG_ 2566767627 XBRAccelerationLimit 2921;
BA_ "SigType" SG_ 2566767627 XBRActiveCtrlMode 4;
BA_ "SPN" SG_ 2566767627 XBRActiveCtrlMode 2918;
BA_ "SigType" SG_ 2566767627 XBRSystemState 4;
BA_ "SPN" SG_ 2566767627 XBRSystemState 2917;
BA_ "SigType" SG_ 2566767627 FoundationBrakeUse 4;
BA_ "SPN" SG_ 2566767627 FoundationBrakeUse 2919;
BA_ "SPN" SG_ 2566767627 HillHolderMode 2912;
BA_ "SPN" SG_ 2566767627 HaltBrakeMode 2913;
BA_ "SigType" SG_ 2565865777 EngAuxShutdownSwitch 4;
BA_ "SPN" SG_ 2565865777 EngAuxShutdownSwitch 970;
BA_ "SigType" SG_ 2565865777 SrcAddrssOfCtrllngDvcFrBrkCntrl 1;
BA_ "SPN" SG_ 2565865777 SrcAddrssOfCtrllngDvcFrBrkCntrl 1481;
BA_ "SigType" SG_ 2565865777 BrakePedalPos 1;
BA_ "SPN" SG_ 2565865777 BrakePedalPos 521;
BA_ "SigType" SG_ 2565865777 TrctrMntdTrilerABSWarningSignal 4;
BA_ "SPN" SG_ 2565865777 TrctrMntdTrilerABSWarningSignal 1792;
BA_ "SigType" SG_ 2565865777 TrailerABSStatus 4;
BA_ "SPN" SG_ 2565865777 TrailerABSStatus 1836;
BA_ "SigType" SG_ 2565865777 HaltBrakeSwitch 4;
BA_ "SPN" SG_ 2565865777 HaltBrakeSwitch 2911;
BA_ "SigType" SG_ 2565865777 ATC_ASRInformationSignal 4;
BA_ "SPN" SG_ 2565865777 ATC_ASRInformationSignal 1793;
BA_ "SigType" SG_ 2565865777 ABS_EBSAmberWarningSignal 4;
BA_ "SPN" SG_ 2565865777 ABS_EBSAmberWarningSignal 1438;
BA_ "SigType" SG_ 2565865777 EBSRedWarningSignal 4;
BA_ "SPN" SG_ 2565865777 EBSRedWarningSignal 1439;
BA_ "SigType" SG_ 2565865777 ABSFullyOperational 4;
BA_ "SPN" SG_ 2565865777 ABSFullyOperational 1243;
BA_ "SigType" SG_ 2565865777 EngRetarderSelection 1;
BA_ "SPN" SG_ 2565865777 EngRetarderSelection 973;
BA_ "SigType" SG_ 2565865777 RemoteAccelEnableSwitch 4;
BA_ "SPN" SG_ 2565865777 RemoteAccelEnableSwitch 969;
BA_ "SigType" SG_ 2565865777 EngDerateSwitch 4;
BA_ "SPN" SG_ 2565865777 EngDerateSwitch 971;
BA_ "SigType" SG_ 2565865777 AccelInterlockSwitch 4;
BA_ "SPN" SG_ 2565865777 AccelInterlockSwitch 972;
BA_ "SigType" SG_ 2565865777 TractionCtrlOverrideSwitch 4;
BA_ "SPN" SG_ 2565865777 TractionCtrlOverrideSwitch 1238;
BA_ "SigType" SG_ 2565865777 ASRHillHolderSwitch 4;
BA_ "SPN" SG_ 2565865777 ASRHillHolderSwitch 577;
BA_ "SigType" SG_ 2565865777 ASROffroadSwitch 4;
BA_ "SPN" SG_ 2565865777 ASROffroadSwitch 576;
BA_ "SigType" SG_ 2565865777 ABSOffroadSwitch 4;
BA_ "SPN" SG_ 2565865777 ABSOffroadSwitch 575;
BA_ "SigType" SG_ 2565865777 EBSBrakeSwitch 4;
BA_ "SPN" SG_ 2565865777 EBSBrakeSwitch 1121;
BA_ "SigType" SG_ 2565865777 AntiLockBrakingActive 4;
BA_ "SPN" SG_ 2565865777 AntiLockBrakingActive 563;
BA_ "SigType" SG_ 2565865777 ASRBrakeCtrlActive 4;
BA_ "SPN" SG_ 2565865777 ASRBrakeCtrlActive 562;
BA_ "SigType" SG_ 2565865777 ASREngCtrlActive 4;
BA_ "SPN" SG_ 2565865777 ASREngCtrlActive 561;
BA_ "SigType" SG_ 2565865761 EngAuxShutdownSwitch 4;
BA_ "SPN" SG_ 2565865761 EngAuxShutdownSwitch 970;
BA_ "SigType" SG_ 2565865761 SrcAddrssOfCtrllngDvcFrBrkCntrl 1;
BA_ "SPN" SG_ 2565865761 SrcAddrssOfCtrllngDvcFrBrkCntrl 1481;
BA_ "SigType" SG_ 2565865761 BrakePedalPos 1;
BA_ "SPN" SG_ 2565865761 BrakePedalPos 521;
BA_ "SigType" SG_ 2565865761 TrctrMntdTrilerABSWarningSignal 4;
BA_ "SPN" SG_ 2565865761 TrctrMntdTrilerABSWarningSignal 1792;
BA_ "SigType" SG_ 2565865761 TrailerABSStatus 4;
BA_ "SPN" SG_ 2565865761 TrailerABSStatus 1836;
BA_ "SigType" SG_ 2565865761 HaltBrakeSwitch 4;
BA_ "SPN" SG_ 2565865761 HaltBrakeSwitch 2911;
BA_ "SigType" SG_ 2565865761 ATC_ASRInformationSignal 4;
BA_ "SPN" SG_ 2565865761 ATC_ASRInformationSignal 1793;
BA_ "SigType" SG_ 2565865761 ABS_EBSAmberWarningSignal 4;
BA_ "SPN" SG_ 2565865761 ABS_EBSAmberWarningSignal 1438;
BA_ "SigType" SG_ 2565865761 EBSRedWarningSignal 4;
BA_ "SPN" SG_ 2565865761 EBSRedWarningSignal 1439;
BA_ "SigType" SG_ 2565865761 ABSFullyOperational 4;
BA_ "SPN" SG_ 2565865761 ABSFullyOperational 1243;
BA_ "SigType" SG_ 2565865761 EngRetarderSelection 1;
BA_ "SPN" SG_ 2565865761 EngRetarderSelection 973;
BA_ "SigType" SG_ 2565865761 RemoteAccelEnableSwitch 4;
BA_ "SPN" SG_ 2565865761 RemoteAccelEnableSwitch 969;
BA_ "SigType" SG_ 2565865761 EngDerateSwitch 4;
BA_ "SPN" SG_ 2565865761 EngDerateSwitch 971;
BA_ "SigType" SG_ 2565865761 AccelInterlockSwitch 4;
BA_ "SPN" SG_ 2565865761 AccelInterlockSwitch 972;
BA_ "SigType" SG_ 2565865761 TractionCtrlOverrideSwitch 4;
BA_ "SPN" SG_ 2565865761 TractionCtrlOverrideSwitch 1238;
BA_ "SigType" SG_ 2565865761 ASRHillHolderSwitch 4;
BA_ "SPN" SG_ 2565865761 ASRHillHolderSwitch 577;
BA_ "SigType" SG_ 2565865761 ASROffroadSwitch 4;
BA_ "SPN" SG_ 2565865761 ASROffroadSwitch 576;
BA_ "SigType" SG_ 2565865761 ABSOffroadSwitch 4;
BA_ "SPN" SG_ 2565865761 ABSOffroadSwitch 575;
BA_ "SigType" SG_ 2565865761 EBSBrakeSwitch 4;
BA_ "SPN" SG_ 2565865761 EBSBrakeSwitch 1121;
BA_ "SigType" SG_ 2565865761 AntiLockBrakingActive 4;
BA_ "SPN" SG_ 2565865761 AntiLockBrakingActive 563;
BA_ "SigType" SG_ 2565865761 ASRBrakeCtrlActive 4;
BA_ "SPN" SG_ 2565865761 ASRBrakeCtrlActive 562;
BA_ "SigType" SG_ 2565865761 ASREngCtrlActive 4;
BA_ "SPN" SG_ 2565865761 ASREngCtrlActive 561;
BA_ "SigType" SG_ 2565865739 EngAuxShutdownSwitch 4;
BA_ "SPN" SG_ 2565865739 EngAuxShutdownSwitch 970;
BA_ "SigType" SG_ 2565865739 SrcAddrssOfCtrllngDvcFrBrkCntrl 1;
BA_ "SPN" SG_ 2565865739 SrcAddrssOfCtrllngDvcFrBrkCntrl 1481;
BA_ "SigType" SG_ 2565865739 BrakePedalPos 1;
BA_ "SPN" SG_ 2565865739 BrakePedalPos 521;
BA_ "SigType" SG_ 2565865739 TrctrMntdTrilerABSWarningSignal 4;
BA_ "SPN" SG_ 2565865739 TrctrMntdTrilerABSWarningSignal 1792;
BA_ "SigType" SG_ 2565865739 TrailerABSStatus 4;
BA_ "SPN" SG_ 2565865739 TrailerABSStatus 1836;
BA_ "SigType" SG_ 2565865739 HaltBrakeSwitch 4;
BA_ "SPN" SG_ 2565865739 HaltBrakeSwitch 2911;
BA_ "SigType" SG_ 2565865739 ATC_ASRInformationSignal 4;
BA_ "SPN" SG_ 2565865739 ATC_ASRInformationSignal 1793;
BA_ "SigType" SG_ 2565865739 ABS_EBSAmberWarningSignal 4;
BA_ "SPN" SG_ 2565865739 ABS_EBSAmberWarningSignal 1438;
BA_ "SigType" SG_ 2565865739 EBSRedWarningSignal 4;
BA_ "SPN" SG_ 2565865739 EBSRedWarningSignal 1439;
BA_ "SigType" SG_ 2565865739 ABSFullyOperational 4;
BA_ "SPN" SG_ 2565865739 ABSFullyOperational 1243;
BA_ "SigType" SG_ 2565865739 EngRetarderSelection 1;
BA_ "SPN" SG_ 2565865739 EngRetarderSelection 973;
BA_ "SigType" SG_ 2565865739 RemoteAccelEnableSwitch 4;
BA_ "SPN" SG_ 2565865739 RemoteAccelEnableSwitch 969;
BA_ "SigType" SG_ 2565865739 EngDerateSwitch 4;
BA_ "SPN" SG_ 2565865739 EngDerateSwitch 971;
BA_ "SigType" SG_ 2565865739 AccelInterlockSwitch 4;
BA_ "SPN" SG_ 2565865739 AccelInterlockSwitch 972;
BA_ "SigType" SG_ 2565865739 TractionCtrlOverrideSwitch 4;
BA_ "SPN" SG_ 2565865739 TractionCtrlOverrideSwitch 1238;
BA_ "SigType" SG_ 2565865739 ASRHillHolderSwitch 4;
BA_ "SPN" SG_ 2565865739 ASRHillHolderSwitch 577;
BA_ "SigType" SG_ 2565865739 ASROffroadSwitch 4;
BA_ "SPN" SG_ 2565865739 ASROffroadSwitch 576;
BA_ "SigType" SG_ 2565865739 ABSOffroadSwitch 4;
BA_ "SPN" SG_ 2565865739 ABSOffroadSwitch 575;
BA_ "SigType" SG_ 2565865739 EBSBrakeSwitch 4;
BA_ "SPN" SG_ 2565865739 EBSBrakeSwitch 1121;
BA_ "SigType" SG_ 2565865739 AntiLockBrakingActive 4;
BA_ "SPN" SG_ 2565865739 AntiLockBrakingActive 563;
BA_ "SigType" SG_ 2565865739 ASRBrakeCtrlActive 4;
BA_ "SPN" SG_ 2565865739 ASRBrakeCtrlActive 562;
BA_ "SigType" SG_ 2565865739 ASREngCtrlActive 4;
BA_ "SPN" SG_ 2565865739 ASREngCtrlActive 561;
BA_ "SigType" SG_ 2565865728 EngAuxShutdownSwitch 4;
BA_ "SPN" SG_ 2565865728 EngAuxShutdownSwitch 970;
BA_ "SigType" SG_ 2565865728 SrcAddrssOfCtrllngDvcFrBrkCntrl 1;
BA_ "SPN" SG_ 2565865728 SrcAddrssOfCtrllngDvcFrBrkCntrl 1481;
BA_ "SigType" SG_ 2565865728 BrakePedalPos 1;
BA_ "SPN" SG_ 2565865728 BrakePedalPos 521;
BA_ "SigType" SG_ 2565865728 TrctrMntdTrilerABSWarningSignal 4;
BA_ "SPN" SG_ 2565865728 TrctrMntdTrilerABSWarningSignal 1792;
BA_ "SigType" SG_ 2565865728 TrailerABSStatus 4;
BA_ "SPN" SG_ 2565865728 TrailerABSStatus 1836;
BA_ "SigType" SG_ 2565865728 HaltBrakeSwitch 4;
BA_ "SPN" SG_ 2565865728 HaltBrakeSwitch 2911;
BA_ "SigType" SG_ 2565865728 ATC_ASRInformationSignal 4;
BA_ "SPN" SG_ 2565865728 ATC_ASRInformationSignal 1793;
BA_ "SigType" SG_ 2565865728 ABS_EBSAmberWarningSignal 4;
BA_ "SPN" SG_ 2565865728 ABS_EBSAmberWarningSignal 1438;
BA_ "SigType" SG_ 2565865728 EBSRedWarningSignal 4;
BA_ "SPN" SG_ 2565865728 EBSRedWarningSignal 1439;
BA_ "SigType" SG_ 2565865728 ABSFullyOperational 4;
BA_ "SPN" SG_ 2565865728 ABSFullyOperational 1243;
BA_ "SigType" SG_ 2565865728 EngRetarderSelection 1;
BA_ "SPN" SG_ 2565865728 EngRetarderSelection 973;
BA_ "SigType" SG_ 2565865728 RemoteAccelEnableSwitch 4;
BA_ "SPN" SG_ 2565865728 RemoteAccelEnableSwitch 969;
BA_ "SigType" SG_ 2565865728 EngDerateSwitch 4;
BA_ "SPN" SG_ 2565865728 EngDerateSwitch 971;
BA_ "SigType" SG_ 2565865728 AccelInterlockSwitch 4;
BA_ "SPN" SG_ 2565865728 AccelInterlockSwitch 972;
BA_ "SigType" SG_ 2565865728 TractionCtrlOverrideSwitch 4;
BA_ "SPN" SG_ 2565865728 TractionCtrlOverrideSwitch 1238;
BA_ "SigType" SG_ 2565865728 ASRHillHolderSwitch 4;
BA_ "SPN" SG_ 2565865728 ASRHillHolderSwitch 577;
BA_ "SigType" SG_ 2565865728 ASROffroadSwitch 4;
BA_ "SPN" SG_ 2565865728 ASROffroadSwitch 576;
BA_ "SigType" SG_ 2565865728 ABSOffroadSwitch 4;
BA_ "SPN" SG_ 2565865728 ABSOffroadSwitch 575;
BA_ "SigType" SG_ 2565865728 EBSBrakeSwitch 4;
BA_ "SPN" SG_ 2565865728 EBSBrakeSwitch 1121;
BA_ "SigType" SG_ 2565865728 AntiLockBrakingActive 4;
BA_ "SPN" SG_ 2565865728 AntiLockBrakingActive 563;
BA_ "SigType" SG_ 2565865728 ASRBrakeCtrlActive 4;
BA_ "SPN" SG_ 2565865728 ASRBrakeCtrlActive 562;
BA_ "SigType" SG_ 2565865728 ASREngCtrlActive 4;
BA_ "SPN" SG_ 2565865728 ASREngCtrlActive 561;
BA_ "SigType" SG_ 2348820739 EngRqedTorque_TorqueLimit 1;
BA_ "SPN" SG_ 2348820739 EngRqedTorque_TorqueLimit 518;
BA_ "SPN" SG_ 2348820739 MessageCounter 4206;
BA_ "SPN" SG_ 2348820739 ControlPurpose 3350;
BA_ "SPN" SG_ 2348820739 TransmissionRate 3349;
BA_ "SigType" SG_ 2348820739 EngRqedSpeed_SpeedLimit 1;
BA_ "SPN" SG_ 2348820739 EngRqedSpeed_SpeedLimit 898;
BA_ "SPN" SG_ 2348820739 OverrideCtrlModePriority 897;
BA_ "SPN" SG_ 2348820739 EngRqedSpeedCtrlConditions 696;
BA_ "SPN" SG_ 2348820739 EngOverrideCtrlMode 695;
BA_ "SPN" SG_ 2348820739 MessageChecksum 4207;
BA_ "SPN" SG_ 2348820739 EngineRequestedTorqueHiRes 4191;
BA_ "SigType" SG_ 2348814083 EngRqedTorque_TorqueLimit 1;
BA_ "SPN" SG_ 2348814083 EngRqedTorque_TorqueLimit 518;
BA_ "SPN" SG_ 2348814083 MessageCounter 4206;
BA_ "SPN" SG_ 2348814083 ControlPurpose 3350;
BA_ "SPN" SG_ 2348814083 TransmissionRate 3349;
BA_ "SigType" SG_ 2348814083 EngRqedSpeed_SpeedLimit 1;
BA_ "SPN" SG_ 2348814083 EngRqedSpeed_SpeedLimit 898;
BA_ "SPN" SG_ 2348814083 OverrideCtrlModePriority 897;
BA_ "SPN" SG_ 2348814083 EngRqedSpeedCtrlConditions 696;
BA_ "SPN" SG_ 2348814083 EngOverrideCtrlMode 695;
BA_ "SPN" SG_ 2348814083 MessageChecksum 4207;
BA_ "SPN" SG_ 2348814083 EngineRequestedTorqueHiRes 4191;
BA_ "SPN" SG_ 2348810243 MessageCounter 4206;
BA_ "SPN" SG_ 2348810243 ControlPurpose 3350;
BA_ "SPN" SG_ 2348810243 TransmissionRate 3349;
BA_ "SigType" SG_ 2348810243 EngRqedTorque_TorqueLimit 1;
BA_ "SPN" SG_ 2348810243 EngRqedTorque_TorqueLimit 518;
BA_ "SigType" SG_ 2348810243 EngRqedSpeed_SpeedLimit 1;
BA_ "SPN" SG_ 2348810243 EngRqedSpeed_SpeedLimit 898;
BA_ "SPN" SG_ 2348810243 OverrideCtrlModePriority 897;
BA_ "SPN" SG_ 2348810243 EngRqedSpeedCtrlConditions 696;
BA_ "SPN" SG_ 2348810243 EngOverrideCtrlMode 695;
BA_ "SPN" SG_ 2348810243 MessageChecksum 4207;
BA_ "SPN" SG_ 2348810243 EngineRequestedTorqueHiRes 4191;
BA_ "SigType" SG_ 2297441790 SpprtVrblTrnsRpttnRtFrAcclrtnSns 4;
BA_ "SPN" SG_ 2297441790 SpprtVrblTrnsRpttnRtFrAcclrtnSns 5353;
BA_ "SystemSignalLongSymbol" SG_ 2297441790 SpprtVrblTrnsRpttnRtFrAcclrtnSns "SpprtVrblTrnsRpttnRtFrAcclrtnSnsr";
BA_ "SigType" SG_ 2297441790 VrtclAcclrtnExRngeFigureOfMerit 4;
BA_ "SPN" SG_ 2297441790 VrtclAcclrtnExRngeFigureOfMerit 5352;
BA_ "SigType" SG_ 2297441790 LngtdnlAcclrtnExRngFgureOfMerit 4;
BA_ "SPN" SG_ 2297441790 LngtdnlAcclrtnExRngFgureOfMerit 5351;
BA_ "SigType" SG_ 2297441790 LtrlAcclrtnExRangeFigureOfMerit 4;
BA_ "SPN" SG_ 2297441790 LtrlAcclrtnExRangeFigureOfMerit 5350;
BA_ "SigType" SG_ 2297441790 VerticalAccelerationExRange 1;
BA_ "SPN" SG_ 2297441790 VerticalAccelerationExRange 5349;
BA_ "SigType" SG_ 2297441790 LateralAccelerationExRange 1;
BA_ "SPN" SG_ 2297441790 LateralAccelerationExRange 5347;
BA_ "SigType" SG_ 2297441790 LongitudinalAccelerationExRange 1;
BA_ "SPN" SG_ 2297441790 LongitudinalAccelerationExRange 5348;
BA_ "SigType" SG_ 2566712062 HybrdBatteryPackRemainingCharge 1;
BA_ "SPN" SG_ 2566712062 HybrdBatteryPackRemainingCharge 5464;
BA_ "SigType" SG_ 2364549630 RllAndPtchExRngMsurementLatency 1;
BA_ "SPN" SG_ 2364549630 RllAndPtchExRngMsurementLatency 4982;
BA_ "SigType" SG_ 2364549630 RollAngleExRangeFigureOfMerit 4;
BA_ "SPN" SG_ 2364549630 RollAngleExRangeFigureOfMerit 4981;
BA_ "SigType" SG_ 2364549630 RollAngleExRangeCompensation 4;
BA_ "SPN" SG_ 2364549630 RollAngleExRangeCompensation 4980;
BA_ "SigType" SG_ 2364549630 PitchAngleExRangeFigureOfMerit 4;
BA_ "SPN" SG_ 2364549630 PitchAngleExRangeFigureOfMerit 4979;
BA_ "SigType" SG_ 2364549630 PitchAngleExRangeCompensation 4;
BA_ "SPN" SG_ 2364549630 PitchAngleExRangeCompensation 4978;
BA_ "SigType" SG_ 2364549630 RollAngleExRange 1;
BA_ "SPN" SG_ 2364549630 RollAngleExRange 4977;
BA_ "SigType" SG_ 2364549630 PitchAngleExRange 1;
BA_ "SPN" SG_ 2364549630 PitchAngleExRange 4976;
BA_ "SigType" SG_ 2499614462 OccpntClssfcationSystem10Status 4;
BA_ "SPN" SG_ 2499614462 OccpntClssfcationSystem10Status 4972;
BA_ "SigType" SG_ 2499614462 OccpntClssficationSystem9Status 4;
BA_ "SPN" SG_ 2499614462 OccpntClssficationSystem9Status 4971;
BA_ "SigType" SG_ 2499614462 OccpntClssficationSystem8Status 4;
BA_ "SPN" SG_ 2499614462 OccpntClssficationSystem8Status 4970;
BA_ "SigType" SG_ 2499614462 OccpntClssficationSystem7Status 4;
BA_ "SPN" SG_ 2499614462 OccpntClssficationSystem7Status 4969;
BA_ "SigType" SG_ 2499614462 OccpntClssficationSystem6Status 4;
BA_ "SPN" SG_ 2499614462 OccpntClssficationSystem6Status 4968;
BA_ "SigType" SG_ 2499614462 OccpntClssficationSystem5Status 4;
BA_ "SPN" SG_ 2499614462 OccpntClssficationSystem5Status 4967;
BA_ "SigType" SG_ 2499614462 OccpntClssficationSystem4Status 4;
BA_ "SPN" SG_ 2499614462 OccpntClssficationSystem4Status 4966;
BA_ "SigType" SG_ 2499614462 OccpntClssficationSystem3Status 4;
BA_ "SPN" SG_ 2499614462 OccpntClssficationSystem3Status 4965;
BA_ "SigType" SG_ 2499614462 PssngrOccpntClssfctnSystmStatus 4;
BA_ "SPN" SG_ 2499614462 PssngrOccpntClssfctnSystmStatus 4964;
BA_ "SigType" SG_ 2499614462 DrvrOccpntClssfctonSystemStatus 4;
BA_ "SPN" SG_ 2499614462 DrvrOccpntClssfctonSystemStatus 4963;
BA_ "SigType" SG_ 2560098046 CabNoiseCtrlTuningStatus 4;
BA_ "SPN" SG_ 2560098046 CabNoiseCtrlTuningStatus 5060;
BA_ "SigType" SG_ 2560098046 CabNoiseCtrlStatus 4;
BA_ "SPN" SG_ 2560098046 CabNoiseCtrlStatus 5059;
BA_ "SigType" SG_ 2560163582 CabNoiseCtrlTuningState 4;
BA_ "SPN" SG_ 2560163582 CabNoiseCtrlTuningState 5058;
BA_ "SigType" SG_ 2560163582 CabNoiseCtrlState 4;
BA_ "SPN" SG_ 2560163582 CabNoiseCtrlState 5057;
BA_ "SigType" SG_ 2297441534 DropRelayCtrl 4;
BA_ "SPN" SG_ 2297441534 DropRelayCtrl 5403;
BA_ "SigType" SG_ 2297441534 LiftRelayCtrl 4;
BA_ "SPN" SG_ 2297441534 LiftRelayCtrl 5402;
BA_ "SigType" SG_ 2297441534 MaterialDropActiveStatus 4;
BA_ "SPN" SG_ 2297441534 MaterialDropActiveStatus 5014;
BA_ "SigType" SG_ 2297441534 MaterialLiftActiveStatus 4;
BA_ "SPN" SG_ 2297441534 MaterialLiftActiveStatus 5013;
BA_ "SigType" SG_ 2297441534 GnratorCurrentBoostActiveStatus 4;
BA_ "SPN" SG_ 2297441534 GnratorCurrentBoostActiveStatus 5012;
BA_ "SigType" SG_ 2297441534 MaterialDropSwitch 4;
BA_ "SPN" SG_ 2297441534 MaterialDropSwitch 5011;
BA_ "SigType" SG_ 2297441534 MaterialLiftSwitch 4;
BA_ "SPN" SG_ 2297441534 MaterialLiftSwitch 5010;
BA_ "SigType" SG_ 2297441534 MagnetReverseCurrent 1;
BA_ "SPN" SG_ 2297441534 MagnetReverseCurrent 5009;
BA_ "SigType" SG_ 2297441534 MagnetForwardCurrent 1;
BA_ "SPN" SG_ 2297441534 MagnetForwardCurrent 5008;
BA_ "SigType" SG_ 2566722302 GneratorDutyCycleExceededStatus 4;
BA_ "SPN" SG_ 2566722302 GneratorDutyCycleExceededStatus 5007;
BA_ "SigType" SG_ 2566722302 VoltageMonitorActiveStatus 4;
BA_ "SPN" SG_ 2566722302 VoltageMonitorActiveStatus 5006;
BA_ "SigType" SG_ 2566722302 GensetEnableActiveStatus 4;
BA_ "SPN" SG_ 2566722302 GensetEnableActiveStatus 5005;
BA_ "SigType" SG_ 2566722302 ReverseCurrentRangeSetting 4;
BA_ "SPN" SG_ 2566722302 ReverseCurrentRangeSetting 5002;
BA_ "SigType" SG_ 2566722302 GensetSoftstartActiveStatus 4;
BA_ "SPN" SG_ 2566722302 GensetSoftstartActiveStatus 5004;
BA_ "SigType" SG_ 2566722302 Grapple_MagnetSelectionSwitch 4;
BA_ "SPN" SG_ 2566722302 Grapple_MagnetSelectionSwitch 5003;
BA_ "SigType" SG_ 2566722302 GnstSystmOtptVoltageRangeStatus 4;
BA_ "SPN" SG_ 2566722302 GnstSystmOtptVoltageRangeStatus 5001;
BA_ "SigType" SG_ 2566722302 GeneratorOverheatStatus 4;
BA_ "SPN" SG_ 2566722302 GeneratorOverheatStatus 5000;
BA_ "SigType" SG_ 2566722558 MagnetRatedPower 1;
BA_ "SPN" SG_ 2566722558 MagnetRatedPower 4999;
BA_ "SigType" SG_ 2566722558 MagnetBoostTime 1;
BA_ "SPN" SG_ 2566722558 MagnetBoostTime 4998;
BA_ "SigType" SG_ 2560032510 LwVltgDscnnctDsredOperatingMode 4;
BA_ "SPN" SG_ 2560032510 LwVltgDscnnctDsredOperatingMode 5149;
BA_ "SigType" SG_ 2566717950 LowVoltageDisconnectTemp 1;
BA_ "SPN" SG_ 2566717950 LowVoltageDisconnectTemp 5148;
BA_ "SigType" SG_ 2566717950 LwVltgDisconnectVoutOutputState 4;
BA_ "SPN" SG_ 2566717950 LwVltgDisconnectVoutOutputState 5147;
BA_ "SigType" SG_ 2566717950 LwVoltageDisconnectOutput1State 4;
BA_ "SPN" SG_ 2566717950 LwVoltageDisconnectOutput1State 5146;
BA_ "SigType" SG_ 2566717950 LwVoltageDisconnectOutput2State 4;
BA_ "SPN" SG_ 2566717950 LwVoltageDisconnectOutput2State 5145;
BA_ "SigType" SG_ 2566717950 LwVoltageDisconnectOutput3State 4;
BA_ "SPN" SG_ 2566717950 LwVoltageDisconnectOutput3State 5144;
BA_ "SigType" SG_ 2566717950 LwVltgDscnnctCrrntOperatingMode 4;
BA_ "SPN" SG_ 2566717950 LwVltgDscnnctCrrntOperatingMode 5143;
BA_ "SigType" SG_ 2566717950 LwVltgDscnnctManualConnectState 4;
BA_ "SPN" SG_ 2566717950 LwVltgDscnnctManualConnectState 5142;
BA_ "SigType" SG_ 2566717950 LwVltgDscnnctMnlDisconnectState 4;
BA_ "SPN" SG_ 2566717950 LwVltgDscnnctMnlDisconnectState 5141;
BA_ "SigType" SG_ 2499604222 BldRferenceElevationOffsetRight 1;
BA_ "SPN" SG_ 2499604222 BldRferenceElevationOffsetRight 5413;
BA_ "SigType" SG_ 2499604222 BldReferenceElevationOffsetLeft 1;
BA_ "SPN" SG_ 2499604222 BldReferenceElevationOffsetLeft 5412;
BA_ "SigType" SG_ 2499604222 BladeElevationDeviationRight 1;
BA_ "SPN" SG_ 2499604222 BladeElevationDeviationRight 5411;
BA_ "SigType" SG_ 2499604222 BladeElevationDeviationLeft 1;
BA_ "SPN" SG_ 2499604222 BladeElevationDeviationLeft 5410;
BA_ "SigType" SG_ 2358902526 Joystick3Lamp10Cmd 4;
BA_ "SPN" SG_ 2358902526 Joystick3Lamp10Cmd 4489;
BA_ "SigType" SG_ 2358902526 Joystick3Lamp9Cmd 4;
BA_ "SPN" SG_ 2358902526 Joystick3Lamp9Cmd 4488;
BA_ "SigType" SG_ 2358902526 Joystick3Lamp8Cmd 4;
BA_ "SPN" SG_ 2358902526 Joystick3Lamp8Cmd 4487;
BA_ "SigType" SG_ 2358902526 Joystick3Lamp7Cmd 4;
BA_ "SPN" SG_ 2358902526 Joystick3Lamp7Cmd 4486;
BA_ "SigType" SG_ 2358902526 Joystick3Lamp6Cmd 4;
BA_ "SPN" SG_ 2358902526 Joystick3Lamp6Cmd 4485;
BA_ "SigType" SG_ 2358902526 Joystick3Lamp5Cmd 4;
BA_ "SPN" SG_ 2358902526 Joystick3Lamp5Cmd 4484;
BA_ "SigType" SG_ 2358902526 Joystick3Lamp4Cmd 4;
BA_ "SPN" SG_ 2358902526 Joystick3Lamp4Cmd 4483;
BA_ "SigType" SG_ 2358902526 Joystick3Lamp3Cmd 4;
BA_ "SPN" SG_ 2358902526 Joystick3Lamp3Cmd 4482;
BA_ "SigType" SG_ 2358902526 Joystick3Lamp2Cmd 4;
BA_ "SPN" SG_ 2358902526 Joystick3Lamp2Cmd 4481;
BA_ "SigType" SG_ 2358902526 Joystick3Lamp1Cmd 4;
BA_ "SPN" SG_ 2358902526 Joystick3Lamp1Cmd 4480;
BA_ "SigType" SG_ 2358902526 Joystick2Lamp10Cmd 4;
BA_ "SPN" SG_ 2358902526 Joystick2Lamp10Cmd 4479;
BA_ "SigType" SG_ 2358902526 Joystick2Lamp9Cmd 4;
BA_ "SPN" SG_ 2358902526 Joystick2Lamp9Cmd 4478;
BA_ "SigType" SG_ 2358902526 Joystick2Lamp8Cmd 4;
BA_ "SPN" SG_ 2358902526 Joystick2Lamp8Cmd 4477;
BA_ "SigType" SG_ 2358902526 Joystick2Lamp7Cmd 4;
BA_ "SPN" SG_ 2358902526 Joystick2Lamp7Cmd 4476;
BA_ "SigType" SG_ 2358902526 Joystick2Lamp6Cmd 4;
BA_ "SPN" SG_ 2358902526 Joystick2Lamp6Cmd 4475;
BA_ "SigType" SG_ 2358902526 Joystick2Lamp5Cmd 4;
BA_ "SPN" SG_ 2358902526 Joystick2Lamp5Cmd 4474;
BA_ "SigType" SG_ 2358902526 Joystick2Lamp4Cmd 4;
BA_ "SPN" SG_ 2358902526 Joystick2Lamp4Cmd 4473;
BA_ "SigType" SG_ 2358902526 Joystick2Lamp3Cmd 4;
BA_ "SPN" SG_ 2358902526 Joystick2Lamp3Cmd 4472;
BA_ "SigType" SG_ 2358902526 Joystick2Lamp2Cmd 4;
BA_ "SPN" SG_ 2358902526 Joystick2Lamp2Cmd 4471;
BA_ "SigType" SG_ 2358902526 Joystick2Lamp1Cmd 4;
BA_ "SPN" SG_ 2358902526 Joystick2Lamp1Cmd 4470;
BA_ "SigType" SG_ 2358902526 Joystick1Lamp10Cmd 4;
BA_ "SPN" SG_ 2358902526 Joystick1Lamp10Cmd 4469;
BA_ "SigType" SG_ 2358902526 Joystick1Lamp9Cmd 4;
BA_ "SPN" SG_ 2358902526 Joystick1Lamp9Cmd 4468;
BA_ "SigType" SG_ 2358902526 Joystick1Lamp8Cmd 4;
BA_ "SPN" SG_ 2358902526 Joystick1Lamp8Cmd 4467;
BA_ "SigType" SG_ 2358902526 Joystick1Lamp7Cmd 4;
BA_ "SPN" SG_ 2358902526 Joystick1Lamp7Cmd 4466;
BA_ "SigType" SG_ 2358902526 Joystick1Lamp6Cmd 4;
BA_ "SPN" SG_ 2358902526 Joystick1Lamp6Cmd 4465;
BA_ "SigType" SG_ 2358902526 Joystick1Lamp5Cmd 4;
BA_ "SPN" SG_ 2358902526 Joystick1Lamp5Cmd 4464;
BA_ "SigType" SG_ 2358902526 Joystick1Lamp4Cmd 4;
BA_ "SPN" SG_ 2358902526 Joystick1Lamp4Cmd 4463;
BA_ "SigType" SG_ 2358902526 Joystick1Lamp3Cmd 4;
BA_ "SPN" SG_ 2358902526 Joystick1Lamp3Cmd 4462;
BA_ "SigType" SG_ 2358902526 Joystick1Lamp2Cmd 4;
BA_ "SPN" SG_ 2358902526 Joystick1Lamp2Cmd 4461;
BA_ "SigType" SG_ 2358902526 Joystick1Lamp1Cmd 4;
BA_ "SPN" SG_ 2358902526 Joystick1Lamp1Cmd 4460;
BA_ "SigType" SG_ 2566711550 IntkVlvActtnSystmOlPrss2SlndCtrl 4;
BA_ "SPN" SG_ 2566711550 IntkVlvActtnSystmOlPrss2SlndCtrl 5500;
BA_ "SigType" SG_ 2566711550 IntkVlvActtnSystmOlPrss1SlndCtrl 4;
BA_ "SPN" SG_ 2566711550 IntkVlvActtnSystmOlPrss1SlndCtrl 5499;
VAL_ 2566844705 ParkBrakeReleaseInhibitRq 3 "Unavailable" 2 "SAEReserved" 1 "ParkBrakeReleaseInhibitRqed" 0 "ParkBrakeReleaseInhibitNotRqed" ;
VAL_ 2566844705 PTOGovernorState 31 "NotAvailable" 20 "11110NotDefined" 19 "PTOSetSpeedMemory2" 18 "PTOSetSpeedMemory1" 17 "PreprogrammedSetSpeed8" 16 "PreprogrammedSetSpeed7" 15 "PreprogrammedSetSpeed6" 14 "PreprogrammedSetSpeed5" 13 "PreprogrammedSetSpeed4" 12 "PreprogrammedSetSpeed3" 11 "PreprogrammedSetSpeed2" 10 "PreprogrammedSetSpeed1" 9 "AccelOverride" 8 "Accelerate" 7 "Resume" 6 "Decelerate_Coast" 5 "Set" 4 "RemoteStandby" 3 "Standby" 2 "RemoteHold" 1 "Hold" 0 "Off_Disabled" ;
VAL_ 2566844705 EngShutdownOverrideSwitch 3 "NotAvailable" 2 "Error" 1 "On" 0 "Off" ;
VAL_ 2566844705 EngTestModeSwitch 3 "NotAvailable" 2 "Error" 1 "On" 0 "Off" ;
VAL_ 2566844705 EngIdleDecrementSwitch 3 "NotAvailable" 2 "Error" 1 "On" 0 "Off" ;
VAL_ 2566844705 EngIdleIncrementSwitch 3 "NotAvailable" 2 "Error" 1 "On" 0 "Off" ;
VAL_ 2566844705 CruiseCtrlStates 7 "NotAvailable" 6 "AccelOverride" 5 "Set" 4 "Resume" 3 "Decelerate" 2 "Accelerate" 1 "Hold" 0 "Off_Disabled" ;
VAL_ 2566844705 CruiseCtrlAccelerateSwitch 3 "NotAvailable" 2 "Error" 1 "CrsCtrlActivatorInPosAccelerate" 0 "CrsCtrlActvtrNotInPosAccelerate" ;
VAL_ 2566844705 CruiseCtrlResumeSwitch 3 "NotAvailable" 2 "Error" 1 "CruiseCtrlActivatorInPosResume" 0 "CrseCtrlActivatorNotInPosResume" ;
VAL_ 2566844705 CruiseCtrlCoastSwitch 3 "NotAvailable" 2 "Error" 1 "CruiseCtrlActivatorInPosCoast" 0 "CriseCtrlActivatorNotInPosCoast" ;
VAL_ 2566844705 CruiseCtrlSetSwitch 3 "NotAvailable" 2 "Error" 1 "CruiseCtrlActivatorInPosSet" 0 "CruiseCtrlActivatorNotInPosSet" ;
VAL_ 2566844705 ClutchSwitch 3 "NotAvailable" 2 "Error" 1 "ClutchPedalDepressed" 0 "ClutchPedalReleased" ;
VAL_ 2566844705 BrakeSwitch_SA21 3 "NotAvailable" 2 "Error" 1 "BrakePedalDepressed" 0 "BrakePedalReleased" ;
VAL_ 2566844705 CruiseCtrlEnableSwitch 3 "NotAvailable" 2 "Error" 1 "CruiseCtrlEnabled" 0 "CruiseCtrlDisabled" ;
VAL_ 2566844705 CruiseCtrlActive 3 "NotAvailable" 2 "Error" 1 "CruiseCtrlSwitchedOn" 0 "CruiseCtrlSwitchedOff" ;
VAL_ 2566844705 CruiseCtrlPauseSwitch 3 "TakeNoAction" 2 "ErrorIndicator" 1 "On" 0 "Off" ;
VAL_ 2566844705 ParkingBrakeSwitch 3 "NotAvailable" 2 "Error" 1 "ParkingBrakeSet" 0 "ParkingBrakeNotSet" ;
VAL_ 2566844705 TwoSpeedAxleSwitch 3 "NotAvailable" 2 "Error" 1 "HighSpeedRange" 0 "LowSpeedRange" ;
VAL_ 2566844695 ParkBrakeReleaseInhibitRq 3 "Unavailable" 2 "SAEReserved" 1 "ParkBrakeReleaseInhibitRqed" 0 "ParkBrakeReleaseInhibitNotRqed" ;
VAL_ 2566844695 PTOGovernorState 31 "NotAvailable" 20 "11110NotDefined" 19 "PTOSetSpeedMemory2" 18 "PTOSetSpeedMemory1" 17 "PreprogrammedSetSpeed8" 16 "PreprogrammedSetSpeed7" 15 "PreprogrammedSetSpeed6" 14 "PreprogrammedSetSpeed5" 13 "PreprogrammedSetSpeed4" 12 "PreprogrammedSetSpeed3" 11 "PreprogrammedSetSpeed2" 10 "PreprogrammedSetSpeed1" 9 "AccelOverride" 8 "Accelerate" 7 "Resume" 6 "Decelerate_Coast" 5 "Set" 4 "RemoteStandby" 3 "Standby" 2 "RemoteHold" 1 "Hold" 0 "Off_Disabled" ;
VAL_ 2566844695 EngShutdownOverrideSwitch 3 "NotAvailable" 2 "Error" 1 "On" 0 "Off" ;
VAL_ 2566844695 EngTestModeSwitch 3 "NotAvailable" 2 "Error" 1 "On" 0 "Off" ;
VAL_ 2566844695 EngIdleDecrementSwitch 3 "NotAvailable" 2 "Error" 1 "On" 0 "Off" ;
VAL_ 2566844695 EngIdleIncrementSwitch 3 "NotAvailable" 2 "Error" 1 "On" 0 "Off" ;
VAL_ 2566844695 CruiseCtrlStates 7 "NotAvailable" 6 "AccelOverride" 5 "Set" 4 "Resume" 3 "Decelerate" 2 "Accelerate" 1 "Hold" 0 "Off_Disabled" ;
VAL_ 2566844695 CruiseCtrlAccelerateSwitch 3 "NotAvailable" 2 "Error" 1 "CrsCtrlActivatorInPosAccelerate" 0 "CrsCtrlActvtrNotInPosAccelerate" ;
VAL_ 2566844695 CruiseCtrlResumeSwitch 3 "NotAvailable" 2 "Error" 1 "CruiseCtrlActivatorInPosResume" 0 "CrseCtrlActivatorNotInPosResume" ;
VAL_ 2566844695 CruiseCtrlCoastSwitch 3 "NotAvailable" 2 "Error" 1 "CruiseCtrlActivatorInPosCoast" 0 "CriseCtrlActivatorNotInPosCoast" ;
VAL_ 2566844695 CruiseCtrlSetSwitch 3 "NotAvailable" 2 "Error" 1 "CruiseCtrlActivatorInPosSet" 0 "CruiseCtrlActivatorNotInPosSet" ;
VAL_ 2566844695 ClutchSwitch 3 "NotAvailable" 2 "Error" 1 "ClutchPedalDepressed" 0 "ClutchPedalReleased" ;
VAL_ 2566844695 BrakeSwitch_SA17 3 "NotAvailable" 2 "Error" 1 "BrakePedalDepressed" 0 "BrakePedalReleased" ;
VAL_ 2566844695 CruiseCtrlEnableSwitch 3 "NotAvailable" 2 "Error" 1 "CruiseCtrlEnabled" 0 "CruiseCtrlDisabled" ;
VAL_ 2566844695 CruiseCtrlActive 3 "NotAvailable" 2 "Error" 1 "CruiseCtrlSwitchedOn" 0 "CruiseCtrlSwitchedOff" ;
VAL_ 2566844695 CruiseCtrlPauseSwitch 3 "TakeNoAction" 2 "ErrorIndicator" 1 "On" 0 "Off" ;
VAL_ 2566844695 ParkingBrakeSwitch 3 "NotAvailable" 2 "Error" 1 "ParkingBrakeSet" 0 "ParkingBrakeNotSet" ;
VAL_ 2566844695 TwoSpeedAxleSwitch 3 "NotAvailable" 2 "Error" 1 "HighSpeedRange" 0 "LowSpeedRange" ;
VAL_ 2566844689 ParkBrakeReleaseInhibitRq 3 "Unavailable" 2 "SAEReserved" 1 "ParkBrakeReleaseInhibitRqed" 0 "ParkBrakeReleaseInhibitNotRqed" ;
VAL_ 2566844689 PTOGovernorState 31 "NotAvailable" 20 "11110NotDefined" 19 "PTOSetSpeedMemory2" 18 "PTOSetSpeedMemory1" 17 "PreprogrammedSetSpeed8" 16 "PreprogrammedSetSpeed7" 15 "PreprogrammedSetSpeed6" 14 "PreprogrammedSetSpeed5" 13 "PreprogrammedSetSpeed4" 12 "PreprogrammedSetSpeed3" 11 "PreprogrammedSetSpeed2" 10 "PreprogrammedSetSpeed1" 9 "AccelOverride" 8 "Accelerate" 7 "Resume" 6 "Decelerate_Coast" 5 "Set" 4 "RemoteStandby" 3 "Standby" 2 "RemoteHold" 1 "Hold" 0 "Off_Disabled" ;
VAL_ 2566844689 EngShutdownOverrideSwitch 3 "NotAvailable" 2 "Error" 1 "On" 0 "Off" ;
VAL_ 2566844689 EngTestModeSwitch 3 "NotAvailable" 2 "Error" 1 "On" 0 "Off" ;
VAL_ 2566844689 EngIdleDecrementSwitch 3 "NotAvailable" 2 "Error" 1 "On" 0 "Off" ;
VAL_ 2566844689 EngIdleIncrementSwitch 3 "NotAvailable" 2 "Error" 1 "On" 0 "Off" ;
VAL_ 2566844689 CruiseCtrlStates 7 "NotAvailable" 6 "AccelOverride" 5 "Set" 4 "Resume" 3 "Decelerate" 2 "Accelerate" 1 "Hold" 0 "Off_Disabled" ;
VAL_ 2566844689 CruiseCtrlAccelerateSwitch 3 "NotAvailable" 2 "Error" 1 "CrsCtrlActivatorInPosAccelerate" 0 "CrsCtrlActvtrNotInPosAccelerate" ;
VAL_ 2566844689 CruiseCtrlResumeSwitch 3 "NotAvailable" 2 "Error" 1 "CruiseCtrlActivatorInPosResume" 0 "CrseCtrlActivatorNotInPosResume" ;
VAL_ 2566844689 CruiseCtrlCoastSwitch 3 "NotAvailable" 2 "Error" 1 "CruiseCtrlActivatorInPosCoast" 0 "CriseCtrlActivatorNotInPosCoast" ;
VAL_ 2566844689 CruiseCtrlSetSwitch 3 "NotAvailable" 2 "Error" 1 "CruiseCtrlActivatorInPosSet" 0 "CruiseCtrlActivatorNotInPosSet" ;
VAL_ 2566844689 ClutchSwitch 3 "NotAvailable" 2 "Error" 1 "ClutchPedalDepressed" 0 "ClutchPedalReleased" ;
VAL_ 2566844689 BrakeSwitch_SA11 3 "NotAvailable" 2 "Error" 1 "BrakePedalDepressed" 0 "BrakePedalReleased" ;
VAL_ 2566844689 CruiseCtrlEnableSwitch 3 "NotAvailable" 2 "Error" 1 "CruiseCtrlEnabled" 0 "CruiseCtrlDisabled" ;
VAL_ 2566844689 CruiseCtrlActive 3 "NotAvailable" 2 "Error" 1 "CruiseCtrlSwitchedOn" 0 "CruiseCtrlSwitchedOff" ;
VAL_ 2566844689 CruiseCtrlPauseSwitch 3 "TakeNoAction" 2 "ErrorIndicator" 1 "On" 0 "Off" ;
VAL_ 2566844689 ParkingBrakeSwitch 3 "NotAvailable" 2 "Error" 1 "ParkingBrakeSet" 0 "ParkingBrakeNotSet" ;
VAL_ 2566844689 TwoSpeedAxleSwitch 3 "NotAvailable" 2 "Error" 1 "HighSpeedRange" 0 "LowSpeedRange" ;
VAL_ 2566844683 ParkBrakeReleaseInhibitRq 3 "Unavailable" 2 "SAEReserved" 1 "ParkBrakeReleaseInhibitRqed" 0 "ParkBrakeReleaseInhibitNotRqed" ;
VAL_ 2566844683 PTOGovernorState 31 "NotAvailable" 20 "11110NotDefined" 19 "PTOSetSpeedMemory2" 18 "PTOSetSpeedMemory1" 17 "PreprogrammedSetSpeed8" 16 "PreprogrammedSetSpeed7" 15 "PreprogrammedSetSpeed6" 14 "PreprogrammedSetSpeed5" 13 "PreprogrammedSetSpeed4" 12 "PreprogrammedSetSpeed3" 11 "PreprogrammedSetSpeed2" 10 "PreprogrammedSetSpeed1" 9 "AccelOverride" 8 "Accelerate" 7 "Resume" 6 "Decelerate_Coast" 5 "Set" 4 "RemoteStandby" 3 "Standby" 2 "RemoteHold" 1 "Hold" 0 "Off_Disabled" ;
VAL_ 2566844683 EngShutdownOverrideSwitch 3 "NotAvailable" 2 "Error" 1 "On" 0 "Off" ;
VAL_ 2566844683 EngTestModeSwitch 3 "NotAvailable" 2 "Error" 1 "On" 0 "Off" ;
VAL_ 2566844683 EngIdleDecrementSwitch 3 "NotAvailable" 2 "Error" 1 "On" 0 "Off" ;
VAL_ 2566844683 EngIdleIncrementSwitch 3 "NotAvailable" 2 "Error" 1 "On" 0 "Off" ;
VAL_ 2566844683 CruiseCtrlStates 7 "NotAvailable" 6 "AccelOverride" 5 "Set" 4 "Resume" 3 "Decelerate" 2 "Accelerate" 1 "Hold" 0 "Off_Disabled" ;
VAL_ 2566844683 CruiseCtrlAccelerateSwitch 3 "NotAvailable" 2 "Error" 1 "CrsCtrlActivatorInPosAccelerate" 0 "CrsCtrlActvtrNotInPosAccelerate" ;
VAL_ 2566844683 CruiseCtrlResumeSwitch 3 "NotAvailable" 2 "Error" 1 "CruiseCtrlActivatorInPosResume" 0 "CrseCtrlActivatorNotInPosResume" ;
VAL_ 2566844683 CruiseCtrlCoastSwitch 3 "NotAvailable" 2 "Error" 1 "CruiseCtrlActivatorInPosCoast" 0 "CriseCtrlActivatorNotInPosCoast" ;
VAL_ 2566844683 CruiseCtrlSetSwitch 3 "NotAvailable" 2 "Error" 1 "CruiseCtrlActivatorInPosSet" 0 "CruiseCtrlActivatorNotInPosSet" ;
VAL_ 2566844683 ClutchSwitch 3 "NotAvailable" 2 "Error" 1 "ClutchPedalDepressed" 0 "ClutchPedalReleased" ;
VAL_ 2566844683 BrakeSwitch_SA0B 3 "NotAvailable" 2 "Error" 1 "BrakePedalDepressed" 0 "BrakePedalReleased" ;
VAL_ 2566844683 CruiseCtrlEnableSwitch 3 "NotAvailable" 2 "Error" 1 "CruiseCtrlEnabled" 0 "CruiseCtrlDisabled" ;
VAL_ 2566844683 CruiseCtrlActive 3 "NotAvailable" 2 "Error" 1 "CruiseCtrlSwitchedOn" 0 "CruiseCtrlSwitchedOff" ;
VAL_ 2566844683 CruiseCtrlPauseSwitch 3 "TakeNoAction" 2 "ErrorIndicator" 1 "On" 0 "Off" ;
VAL_ 2566844683 ParkingBrakeSwitch 3 "NotAvailable" 2 "Error" 1 "ParkingBrakeSet" 0 "ParkingBrakeNotSet" ;
VAL_ 2566844683 TwoSpeedAxleSwitch 3 "NotAvailable" 2 "Error" 1 "HighSpeedRange" 0 "LowSpeedRange" ;
VAL_ 2566844672 ParkBrakeReleaseInhibitRq 3 "Unavailable" 2 "SAEReserved" 1 "ParkBrakeReleaseInhibitRqed" 0 "ParkBrakeReleaseInhibitNotRqed" ;
VAL_ 2566844672 PTOGovernorState 31 "NotAvailable" 20 "11110NotDefined" 19 "PTOSetSpeedMemory2" 18 "PTOSetSpeedMemory1" 17 "PreprogrammedSetSpeed8" 16 "PreprogrammedSetSpeed7" 15 "PreprogrammedSetSpeed6" 14 "PreprogrammedSetSpeed5" 13 "PreprogrammedSetSpeed4" 12 "PreprogrammedSetSpeed3" 11 "PreprogrammedSetSpeed2" 10 "PreprogrammedSetSpeed1" 9 "AccelOverride" 8 "Accelerate" 7 "Resume" 6 "Decelerate_Coast" 5 "Set" 4 "RemoteStandby" 3 "Standby" 2 "RemoteHold" 1 "Hold" 0 "Off_Disabled" ;
VAL_ 2566844672 EngShutdownOverrideSwitch 3 "NotAvailable" 2 "Error" 1 "On" 0 "Off" ;
VAL_ 2566844672 EngTestModeSwitch 3 "NotAvailable" 2 "Error" 1 "On" 0 "Off" ;
VAL_ 2566844672 EngIdleDecrementSwitch 3 "NotAvailable" 2 "Error" 1 "On" 0 "Off" ;
VAL_ 2566844672 EngIdleIncrementSwitch 3 "NotAvailable" 2 "Error" 1 "On" 0 "Off" ;
VAL_ 2566844672 CruiseCtrlStates 7 "NotAvailable" 6 "AccelOverride" 5 "Set" 4 "Resume" 3 "Decelerate" 2 "Accelerate" 1 "Hold" 0 "Off_Disabled" ;
VAL_ 2566844672 CruiseCtrlAccelerateSwitch 3 "NotAvailable" 2 "Error" 1 "CrsCtrlActivatorInPosAccelerate" 0 "CrsCtrlActvtrNotInPosAccelerate" ;
VAL_ 2566844672 CruiseCtrlResumeSwitch 3 "NotAvailable" 2 "Error" 1 "CruiseCtrlActivatorInPosResume" 0 "CrseCtrlActivatorNotInPosResume" ;
VAL_ 2566844672 CruiseCtrlCoastSwitch 3 "NotAvailable" 2 "Error" 1 "CruiseCtrlActivatorInPosCoast" 0 "CriseCtrlActivatorNotInPosCoast" ;
VAL_ 2566844672 CruiseCtrlSetSwitch 3 "NotAvailable" 2 "Error" 1 "CruiseCtrlActivatorInPosSet" 0 "CruiseCtrlActivatorNotInPosSet" ;
VAL_ 2566844672 ClutchSwitch 3 "NotAvailable" 2 "Error" 1 "ClutchPedalDepressed" 0 "ClutchPedalReleased" ;
VAL_ 2566844672 BrakeSwitch_SA00 3 "NotAvailable" 2 "Error" 1 "BrakePedalDepressed" 0 "BrakePedalReleased" ;
VAL_ 2566844672 CruiseCtrlEnableSwitch 3 "NotAvailable" 2 "Error" 1 "CruiseCtrlEnabled" 0 "CruiseCtrlDisabled" ;
VAL_ 2566844672 CruiseCtrlActive 3 "NotAvailable" 2 "Error" 1 "CruiseCtrlSwitchedOn" 0 "CruiseCtrlSwitchedOff" ;
VAL_ 2566844672 CruiseCtrlPauseSwitch 3 "TakeNoAction" 2 "ErrorIndicator" 1 "On" 0 "Off" ;
VAL_ 2566844672 ParkingBrakeSwitch 3 "NotAvailable" 2 "Error" 1 "ParkingBrakeSet" 0 "ParkingBrakeNotSet" ;
VAL_ 2566844672 TwoSpeedAxleSwitch 3 "NotAvailable" 2 "Error" 1 "HighSpeedRange" 0 "LowSpeedRange" ;
VAL_ 2565865513 RetarderRoadSpeedLimitSwitch 3 "NotAvailable" 2 "ErrorIndicator" 1 "RdSpdLmtngByRtrdrIsEnbldRdSpdTh" 0 "RdSpdLmtingByRetarderIsDisabled" ;
VAL_ 2565865513 RetarderRoadSpeedExceededStatus 3 "DontCare_TakeNoAction" 2 "Reserved" 1 "RdSpdIsAbvThrshldAndRtrdrIsAllw" 0 "RoadSpeedIsBelowThreshold" ;
VAL_ 2565865513 RetarderRqingBrakeLight 3 "NotAvailable_TakeNoAction" 2 "Reserved" 1 "RtrdrIsRqngThtBrkLghtsArIllmntd" 0 "RtrdrIsNtRqngThtBrkLghtsArIllmn" ;
VAL_ 2565865513 EngCoolantLoadIncrease 3 "NotAvailable" 2 "Error" 1 "CoolantLoadIncreasePossible" 0 "NoCoolantLoadIncrease" ;
VAL_ 2565865513 RetarderEnableShiftAssistSwitch 3 "NotAvailable" 2 "Error" 1 "RetarderShiftAssistEnabled" 0 "RetarderShiftAssistDisabled" ;
VAL_ 2565865513 RetarderEnableBrakeAssistSwitch 3 "NotAvailable" 2 "Error" 1 "RetarderBrakeAssistEnabled" 0 "RetarderBrakeAssistDisabled" ;
VAL_ 2565865487 RetarderRoadSpeedLimitSwitch 3 "NotAvailable" 2 "ErrorIndicator" 1 "RdSpdLmtngByRtrdrIsEnbldRdSpdTh" 0 "RdSpdLmtingByRetarderIsDisabled" ;
VAL_ 2565865487 RetarderRoadSpeedExceededStatus 3 "DontCare_TakeNoAction" 2 "Reserved" 1 "RdSpdIsAbvThrshldAndRtrdrIsAllw" 0 "RoadSpeedIsBelowThreshold" ;
VAL_ 2565865487 RetarderRqingBrakeLight 3 "NotAvailable_TakeNoAction" 2 "Reserved" 1 "RtrdrIsRqngThtBrkLghtsArIllmntd" 0 "RtrdrIsNtRqngThtBrkLghtsArIllmn" ;
VAL_ 2565865487 EngCoolantLoadIncrease 3 "NotAvailable" 2 "Error" 1 "CoolantLoadIncreasePossible" 0 "NoCoolantLoadIncrease" ;
VAL_ 2565865487 RetarderEnableShiftAssistSwitch 3 "NotAvailable" 2 "Error" 1 "RetarderShiftAssistEnabled" 0 "RetarderShiftAssistDisabled" ;
VAL_ 2565865487 RetarderEnableBrakeAssistSwitch 3 "NotAvailable" 2 "Error" 1 "RetarderBrakeAssistEnabled" 0 "RetarderBrakeAssistDisabled" ;
VAL_ 2364539697 SCRThermalManagementActive 3 "DontCare" 2 "Reserved" 1 "SCRThermalManagementIsActive" 0 "SCRThermalManagementIsNotActive" ;
VAL_ 2364539697 MmntryEngMaxPowerEnableFeedback 3 "dontCare" 2 "reserved" 1 "supported" 0 "disabled" ;
VAL_ 2364539697 DPFThermalManagementActive 3 "DontCare" 2 "Reserved" 1 "DPFThermalManagementIsActive" 0 "DPFThermalManagementIsNotActive" ;
VAL_ 2364539697 VhclAccelerationRateLimitStatus 3 "NotAvailable" 2 "Reserved" 1 "LimitActive" 0 "LimitNotActive" ;
VAL_ 2364539697 AccelPedal2LowIdleSwitch 3 "NotAvailable" 2 "Error" 1 "AccelPedal2InLowIdleCondition" 0 "AcclPedal2NotInLowIdleCondition" ;
VAL_ 2364539697 RoadSpeedLimitStatus 3 "NotAvailable" 2 "Error" 1 "NotActive" 0 "Active" ;
VAL_ 2364539697 AccelPedalKickdownSwitch 3 "NotAvailable" 2 "Error" 1 "KickdownActive" 0 "KickdownPassive" ;
VAL_ 2364539697 AccelPedal1LowIdleSwitch 3 "NotAvailable" 2 "Error" 1 "AccelPedal1InLowIdleCondition" 0 "AcclPedal1NotInLowIdleCondition" ;
VAL_ 2364539681 SCRThermalManagementActive 3 "DontCare" 2 "Reserved" 1 "SCRThermalManagementIsActive" 0 "SCRThermalManagementIsNotActive" ;
VAL_ 2364539681 MmntryEngMaxPowerEnableFeedback 3 "dontCare" 2 "reserved" 1 "supported" 0 "disabled" ;
VAL_ 2364539681 DPFThermalManagementActive 3 "DontCare" 2 "Reserved" 1 "DPFThermalManagementIsActive" 0 "DPFThermalManagementIsNotActive" ;
VAL_ 2364539681 VhclAccelerationRateLimitStatus 3 "NotAvailable" 2 "Reserved" 1 "LimitActive" 0 "LimitNotActive" ;
VAL_ 2364539681 AccelPedal2LowIdleSwitch 3 "NotAvailable" 2 "Error" 1 "AccelPedal2InLowIdleCondition" 0 "AcclPedal2NotInLowIdleCondition" ;
VAL_ 2364539681 RoadSpeedLimitStatus 3 "NotAvailable" 2 "Error" 1 "NotActive" 0 "Active" ;
VAL_ 2364539681 AccelPedalKickdownSwitch 3 "NotAvailable" 2 "Error" 1 "KickdownActive" 0 "KickdownPassive" ;
VAL_ 2364539681 AccelPedal1LowIdleSwitch 3 "NotAvailable" 2 "Error" 1 "AccelPedal1InLowIdleCondition" 0 "AcclPedal1NotInLowIdleCondition" ;
VAL_ 2364539671 SCRThermalManagementActive 3 "DontCare" 2 "Reserved" 1 "SCRThermalManagementIsActive" 0 "SCRThermalManagementIsNotActive" ;
VAL_ 2364539671 MmntryEngMaxPowerEnableFeedback 3 "dontCare" 2 "reserved" 1 "supported" 0 "disabled" ;
VAL_ 2364539671 DPFThermalManagementActive 3 "DontCare" 2 "Reserved" 1 "DPFThermalManagementIsActive" 0 "DPFThermalManagementIsNotActive" ;
VAL_ 2364539671 VhclAccelerationRateLimitStatus 3 "NotAvailable" 2 "Reserved" 1 "LimitActive" 0 "LimitNotActive" ;
VAL_ 2364539671 AccelPedal2LowIdleSwitch 3 "NotAvailable" 2 "Error" 1 "AccelPedal2InLowIdleCondition" 0 "AcclPedal2NotInLowIdleCondition" ;
VAL_ 2364539671 RoadSpeedLimitStatus 3 "NotAvailable" 2 "Error" 1 "NotActive" 0 "Active" ;
VAL_ 2364539671 AccelPedalKickdownSwitch 3 "NotAvailable" 2 "Error" 1 "KickdownActive" 0 "KickdownPassive" ;
VAL_ 2364539671 AccelPedal1LowIdleSwitch 3 "NotAvailable" 2 "Error" 1 "AccelPedal1InLowIdleCondition" 0 "AcclPedal1NotInLowIdleCondition" ;
VAL_ 2364539665 SCRThermalManagementActive 3 "DontCare" 2 "Reserved" 1 "SCRThermalManagementIsActive" 0 "SCRThermalManagementIsNotActive" ;
VAL_ 2364539665 MmntryEngMaxPowerEnableFeedback 3 "dontCare" 2 "reserved" 1 "supported" 0 "disabled" ;
VAL_ 2364539665 DPFThermalManagementActive 3 "DontCare" 2 "Reserved" 1 "DPFThermalManagementIsActive" 0 "DPFThermalManagementIsNotActive" ;
VAL_ 2364539665 VhclAccelerationRateLimitStatus 3 "NotAvailable" 2 "Reserved" 1 "LimitActive" 0 "LimitNotActive" ;
VAL_ 2364539665 AccelPedal2LowIdleSwitch 3 "NotAvailable" 2 "Error" 1 "AccelPedal2InLowIdleCondition" 0 "AcclPedal2NotInLowIdleCondition" ;
VAL_ 2364539665 RoadSpeedLimitStatus 3 "NotAvailable" 2 "Error" 1 "NotActive" 0 "Active" ;
VAL_ 2364539665 AccelPedalKickdownSwitch 3 "NotAvailable" 2 "Error" 1 "KickdownActive" 0 "KickdownPassive" ;
VAL_ 2364539665 AccelPedal1LowIdleSwitch 3 "NotAvailable" 2 "Error" 1 "AccelPedal1InLowIdleCondition" 0 "AcclPedal1NotInLowIdleCondition" ;
VAL_ 2364539648 SCRThermalManagementActive 3 "DontCare" 2 "Reserved" 1 "SCRThermalManagementIsActive" 0 "SCRThermalManagementIsNotActive" ;
VAL_ 2364539648 MmntryEngMaxPowerEnableFeedback 3 "dontCare" 2 "reserved" 1 "supported" 0 "disabled" ;
VAL_ 2364539648 DPFThermalManagementActive 3 "DontCare" 2 "Reserved" 1 "DPFThermalManagementIsActive" 0 "DPFThermalManagementIsNotActive" ;
VAL_ 2364539648 VhclAccelerationRateLimitStatus 3 "NotAvailable" 2 "Reserved" 1 "LimitActive" 0 "LimitNotActive" ;
VAL_ 2364539648 AccelPedal2LowIdleSwitch 3 "NotAvailable" 2 "Error" 1 "AccelPedal2InLowIdleCondition" 0 "AcclPedal2NotInLowIdleCondition" ;
VAL_ 2364539648 RoadSpeedLimitStatus 3 "NotAvailable" 2 "Error" 1 "NotActive" 0 "Active" ;
VAL_ 2364539648 AccelPedalKickdownSwitch 3 "NotAvailable" 2 "Error" 1 "KickdownActive" 0 "KickdownPassive" ;
VAL_ 2364539648 AccelPedal1LowIdleSwitch 3 "NotAvailable" 2 "Error" 1 "AccelPedal1InLowIdleCondition" 0 "AcclPedal1NotInLowIdleCondition" ;
VAL_ 2566767665 BrakeTempWarning 3 "notAvailable" 2 "Reserved" 1 "Active" 0 "NotActive" ;
VAL_ 2566767665 PrkngBrkeActuatorFullyActivated 3 "NotAvailable" 2 "Error" 1 "PrkngBrkeActuatorFullyActivated" 0 "PrkngBrkActtorNotFullyActivated" ;
VAL_ 2566767665 XBRActiveCtrlMode 15 "NotAvailable" 4 "1110ReservedForSAEAssignment" 3 "MxMdOfXBRAcclrtnCtrlBngExecuted" 2 "AddtnMdOfXBRAcclrtnCtrlBngExctd" 1 "DrvrsBrkDmndBngExctdNExtlBrkDmn" 0 "NoBrakeDemandBeingExecuted" ;
VAL_ 2566767665 XBRSystemState 3 "NotAvailable" 2 "NoExtlBrakeDemandWillBeAccepted" 1 "OnlyExtlBrkDmndOfHghstXBRPrrtyW" 0 "AnyExtlBrkeDemandWillBeAccepted" ;
VAL_ 2566767665 FoundationBrakeUse 3 "NotAvailable" 2 "Reserved" 1 "FoundationBrakesInUse" 0 "FoundationBrakesNotInUse" ;
VAL_ 2566767665 HillHolderMode 7 "NotAvailable" 6 "HillHolderNotFunctional" 3 "101Reserved" 2 "ActvBtWllChngTInctvInAShortTime" 1 "Active" 0 "Inactive" ;
VAL_ 2566767665 HaltBrakeMode 7 "NotAvailable" 6 "Reserved" 3 "101NotDefined" 2 "ActiveButNotFunctioningProperly" 1 "Active" 0 "Inactive" ;
VAL_ 2566767627 BrakeTempWarning 3 "notAvailable" 2 "Reserved" 1 "Active" 0 "NotActive" ;
VAL_ 2566767627 PrkngBrkeActuatorFullyActivated 3 "NotAvailable" 2 "Error" 1 "PrkngBrkeActuatorFullyActivated" 0 "PrkngBrkActtorNotFullyActivated" ;
VAL_ 2566767627 XBRActiveCtrlMode 15 "NotAvailable" 4 "1110ReservedForSAEAssignment" 3 "MxMdOfXBRAcclrtnCtrlBngExecuted" 2 "AddtnMdOfXBRAcclrtnCtrlBngExctd" 1 "DrvrsBrkDmndBngExctdNExtlBrkDmn" 0 "NoBrakeDemandBeingExecuted" ;
VAL_ 2566767627 XBRSystemState 3 "NotAvailable" 2 "NoExtlBrakeDemandWillBeAccepted" 1 "OnlyExtlBrkDmndOfHghstXBRPrrtyW" 0 "AnyExtlBrkeDemandWillBeAccepted" ;
VAL_ 2566767627 FoundationBrakeUse 3 "NotAvailable" 2 "Reserved" 1 "FoundationBrakesInUse" 0 "FoundationBrakesNotInUse" ;
VAL_ 2566767627 HillHolderMode 7 "NotAvailable" 6 "HillHolderNotFunctional" 3 "101Reserved" 2 "ActvBtWllChngTInctvInAShortTime" 1 "Active" 0 "Inactive" ;
VAL_ 2566767627 HaltBrakeMode 7 "NotAvailable" 6 "Reserved" 3 "101NotDefined" 2 "ActiveButNotFunctioningProperly" 1 "Active" 0 "Inactive" ;
VAL_ 2565865777 EngAuxShutdownSwitch 3 "NotAvailable" 2 "Error" 1 "On" 0 "Off" ;
VAL_ 2565865777 TrctrMntdTrilerABSWarningSignal 3 "TakeNoAction" 2 "Reserved" 1 "On" 0 "Off" ;
VAL_ 2565865777 TrailerABSStatus 3 "NotAvailableOrNotSupported" 2 "Reserved" 1 "TrailerABSActive" 0 "InformationAvailableButNotActive" ;
VAL_ 2565865777 HaltBrakeSwitch 3 "NotAvailable" 2 "Error" 1 "HaltBrakeSwitchActive" 0 "HaltBrakeSwitchPassive" ;
VAL_ 2565865777 ATC_ASRInformationSignal 3 "TakeNoAction" 2 "Reserved" 1 "On" 0 "Off" ;
VAL_ 2565865777 ABS_EBSAmberWarningSignal 3 "TakeNoAction" 2 "Reserved" 1 "On" 0 "Off" ;
VAL_ 2565865777 EBSRedWarningSignal 3 "TakeNoAction" 2 "Reserved" 1 "On" 0 "Off" ;
VAL_ 2565865777 ABSFullyOperational 3 "NotAvailable" 2 "Reserved" 1 "FullyOperational" 0 "NotFullyOperational" ;
VAL_ 2565865777 RemoteAccelEnableSwitch 3 "NotAvailable" 2 "Error" 1 "On" 0 "Off" ;
VAL_ 2565865777 EngDerateSwitch 3 "NotAvailable" 2 "Error" 1 "On" 0 "Off" ;
VAL_ 2565865777 AccelInterlockSwitch 3 "NotAvailable" 2 "Error" 1 "On" 0 "Off" ;
VAL_ 2565865777 TractionCtrlOverrideSwitch 3 "NotAvailableNotInstalled" 2 "Error" 1 "On" 0 "Off" ;
VAL_ 2565865777 ASRHillHolderSwitch 3 "NotAvailable" 2 "Error" 1 "ASRHillHolderSwitchActive" 0 "ASRHillHolderSwitchPassive" ;
VAL_ 2565865777 ASROffroadSwitch 2 "Error" 1 "ASROffroadSwitchActive" 0 "ASROffroadSwitchPassive" 3 "NotAvailable" ;
VAL_ 2565865777 ABSOffroadSwitch 3 "NotAvailable" 2 "Error" 1 "ABSOffroadSwitchActive" 0 "ABSOffroadSwitchPassive" ;
VAL_ 2565865777 EBSBrakeSwitch 3 "NotAvailable" 2 "Error" 1 "BrakePedalIsBeingPressed" 0 "BrakePedalIsNotBeingPressed" ;
VAL_ 2565865777 AntiLockBrakingActive 3 "NotAvailable" 2 "Reserved" 1 "ABSActive" 0 "ABSPassiveButInstalled" ;
VAL_ 2565865777 ASRBrakeCtrlActive 3 "NotAvailable" 2 "Reserved" 1 "ASRBrakeCtrlActive" 0 "ASRBrakeCtrlPassiveButInstalled" ;
VAL_ 2565865777 ASREngCtrlActive 3 "NotAvailable" 2 "Reserved" 1 "ASREngCtrlActive" 0 "ASREngCtrlPassiveButInstalled" ;
VAL_ 2565865761 EngAuxShutdownSwitch 3 "NotAvailable" 2 "Error" 1 "On" 0 "Off" ;
VAL_ 2565865761 TrctrMntdTrilerABSWarningSignal 3 "TakeNoAction" 2 "Reserved" 1 "On" 0 "Off" ;
VAL_ 2565865761 TrailerABSStatus 3 "NotAvailableOrNotSupported" 2 "Reserved" 1 "TrailerABSActive" 0 "InformationAvailableButNotActive" ;
VAL_ 2565865761 HaltBrakeSwitch 3 "NotAvailable" 2 "Error" 1 "HaltBrakeSwitchActive" 0 "HaltBrakeSwitchPassive" ;
VAL_ 2565865761 ATC_ASRInformationSignal 3 "TakeNoAction" 2 "Reserved" 1 "On" 0 "Off" ;
VAL_ 2565865761 ABS_EBSAmberWarningSignal 3 "TakeNoAction" 2 "Reserved" 1 "On" 0 "Off" ;
VAL_ 2565865761 EBSRedWarningSignal 3 "TakeNoAction" 2 "Reserved" 1 "On" 0 "Off" ;
VAL_ 2565865761 ABSFullyOperational 3 "NotAvailable" 2 "Reserved" 1 "FullyOperational" 0 "NotFullyOperational" ;
VAL_ 2565865761 RemoteAccelEnableSwitch 3 "NotAvailable" 2 "Error" 1 "On" 0 "Off" ;
VAL_ 2565865761 EngDerateSwitch 3 "NotAvailable" 2 "Error" 1 "On" 0 "Off" ;
VAL_ 2565865761 AccelInterlockSwitch 3 "NotAvailable" 2 "Error" 1 "On" 0 "Off" ;
VAL_ 2565865761 TractionCtrlOverrideSwitch 3 "NotAvailableNotInstalled" 2 "Error" 1 "On" 0 "Off" ;
VAL_ 2565865761 ASRHillHolderSwitch 3 "NotAvailable" 2 "Error" 1 "ASRHillHolderSwitchActive" 0 "ASRHillHolderSwitchPassive" ;
VAL_ 2565865761 ASROffroadSwitch 2 "Error" 1 "ASROffroadSwitchActive" 0 "ASROffroadSwitchPassive" 3 "NotAvailable" ;
VAL_ 2565865761 ABSOffroadSwitch 3 "NotAvailable" 2 "Error" 1 "ABSOffroadSwitchActive" 0 "ABSOffroadSwitchPassive" ;
VAL_ 2565865761 EBSBrakeSwitch 3 "NotAvailable" 2 "Error" 1 "BrakePedalIsBeingPressed" 0 "BrakePedalIsNotBeingPressed" ;
VAL_ 2565865761 AntiLockBrakingActive 3 "NotAvailable" 2 "Reserved" 1 "ABSActive" 0 "ABSPassiveButInstalled" ;
VAL_ 2565865761 ASRBrakeCtrlActive 3 "NotAvailable" 2 "Reserved" 1 "ASRBrakeCtrlActive" 0 "ASRBrakeCtrlPassiveButInstalled" ;
VAL_ 2565865761 ASREngCtrlActive 3 "NotAvailable" 2 "Reserved" 1 "ASREngCtrlActive" 0 "ASREngCtrlPassiveButInstalled" ;
VAL_ 2565865739 EngAuxShutdownSwitch 3 "NotAvailable" 2 "Error" 1 "On" 0 "Off" ;
VAL_ 2565865739 TrctrMntdTrilerABSWarningSignal 3 "TakeNoAction" 2 "Reserved" 1 "On" 0 "Off" ;
VAL_ 2565865739 TrailerABSStatus 3 "NotAvailableOrNotSupported" 2 "Reserved" 1 "TrailerABSActive" 0 "InformationAvailableButNotActive" ;
VAL_ 2565865739 HaltBrakeSwitch 3 "NotAvailable" 2 "Error" 1 "HaltBrakeSwitchActive" 0 "HaltBrakeSwitchPassive" ;
VAL_ 2565865739 ATC_ASRInformationSignal 3 "TakeNoAction" 2 "Reserved" 1 "On" 0 "Off" ;
VAL_ 2565865739 ABS_EBSAmberWarningSignal 3 "TakeNoAction" 2 "Reserved" 1 "On" 0 "Off" ;
VAL_ 2565865739 EBSRedWarningSignal 3 "TakeNoAction" 2 "Reserved" 1 "On" 0 "Off" ;
VAL_ 2565865739 ABSFullyOperational 3 "NotAvailable" 2 "Reserved" 1 "FullyOperational" 0 "NotFullyOperational" ;
VAL_ 2565865739 RemoteAccelEnableSwitch 3 "NotAvailable" 2 "Error" 1 "On" 0 "Off" ;
VAL_ 2565865739 EngDerateSwitch 3 "NotAvailable" 2 "Error" 1 "On" 0 "Off" ;
VAL_ 2565865739 AccelInterlockSwitch 3 "NotAvailable" 2 "Error" 1 "On" 0 "Off" ;
VAL_ 2565865739 TractionCtrlOverrideSwitch 3 "NotAvailableNotInstalled" 2 "Error" 1 "On" 0 "Off" ;
VAL_ 2565865739 ASRHillHolderSwitch 3 "NotAvailable" 2 "Error" 1 "ASRHillHolderSwitchActive" 0 "ASRHillHolderSwitchPassive" ;
VAL_ 2565865739 ASROffroadSwitch 2 "Error" 1 "ASROffroadSwitchActive" 0 "ASROffroadSwitchPassive" 3 "NotAvailable" ;
VAL_ 2565865739 ABSOffroadSwitch 3 "NotAvailable" 2 "Error" 1 "ABSOffroadSwitchActive" 0 "ABSOffroadSwitchPassive" ;
VAL_ 2565865739 EBSBrakeSwitch 3 "NotAvailable" 2 "Error" 1 "BrakePedalIsBeingPressed" 0 "BrakePedalIsNotBeingPressed" ;
VAL_ 2565865739 AntiLockBrakingActive 3 "NotAvailable" 2 "Reserved" 1 "ABSActive" 0 "ABSPassiveButInstalled" ;
VAL_ 2565865739 ASRBrakeCtrlActive 3 "NotAvailable" 2 "Reserved" 1 "ASRBrakeCtrlActive" 0 "ASRBrakeCtrlPassiveButInstalled" ;
VAL_ 2565865739 ASREngCtrlActive 3 "NotAvailable" 2 "Reserved" 1 "ASREngCtrlActive" 0 "ASREngCtrlPassiveButInstalled" ;
VAL_ 2565865728 EngAuxShutdownSwitch 3 "NotAvailable" 2 "Error" 1 "On" 0 "Off" ;
VAL_ 2565865728 TrctrMntdTrilerABSWarningSignal 3 "TakeNoAction" 2 "Reserved" 1 "On" 0 "Off" ;
VAL_ 2565865728 TrailerABSStatus 3 "NotAvailableOrNotSupported" 2 "Reserved" 1 "TrailerABSActive" 0 "InformationAvailableButNotActive" ;
VAL_ 2565865728 HaltBrakeSwitch 3 "NotAvailable" 2 "Error" 1 "HaltBrakeSwitchActive" 0 "HaltBrakeSwitchPassive" ;
VAL_ 2565865728 ATC_ASRInformationSignal 3 "TakeNoAction" 2 "Reserved" 1 "On" 0 "Off" ;
VAL_ 2565865728 ABS_EBSAmberWarningSignal 3 "TakeNoAction" 2 "Reserved" 1 "On" 0 "Off" ;
VAL_ 2565865728 EBSRedWarningSignal 3 "TakeNoAction" 2 "Reserved" 1 "On" 0 "Off" ;
VAL_ 2565865728 ABSFullyOperational 3 "NotAvailable" 2 "Reserved" 1 "FullyOperational" 0 "NotFullyOperational" ;
VAL_ 2565865728 RemoteAccelEnableSwitch 3 "NotAvailable" 2 "Error" 1 "On" 0 "Off" ;
VAL_ 2565865728 EngDerateSwitch 3 "NotAvailable" 2 "Error" 1 "On" 0 "Off" ;
VAL_ 2565865728 AccelInterlockSwitch 3 "NotAvailable" 2 "Error" 1 "On" 0 "Off" ;
VAL_ 2565865728 TractionCtrlOverrideSwitch 3 "NotAvailableNotInstalled" 2 "Error" 1 "On" 0 "Off" ;
VAL_ 2565865728 ASRHillHolderSwitch 3 "NotAvailable" 2 "Error" 1 "ASRHillHolderSwitchActive" 0 "ASRHillHolderSwitchPassive" ;
VAL_ 2565865728 ASROffroadSwitch 2 "Error" 1 "ASROffroadSwitchActive" 0 "ASROffroadSwitchPassive" 3 "NotAvailable" ;
VAL_ 2565865728 ABSOffroadSwitch 3 "NotAvailable" 2 "Error" 1 "ABSOffroadSwitchActive" 0 "ABSOffroadSwitchPassive" ;
VAL_ 2565865728 EBSBrakeSwitch 3 "NotAvailable" 2 "Error" 1 "BrakePedalIsBeingPressed" 0 "BrakePedalIsNotBeingPressed" ;
VAL_ 2565865728 AntiLockBrakingActive 3 "NotAvailable" 2 "Reserved" 1 "ABSActive" 0 "ABSPassiveButInstalled" ;
VAL_ 2565865728 ASRBrakeCtrlActive 3 "NotAvailable" 2 "Reserved" 1 "ASRBrakeCtrlActive" 0 "ASRBrakeCtrlPassiveButInstalled" ;
VAL_ 2565865728 ASREngCtrlActive 3 "NotAvailable" 2 "Reserved" 1 "ASREngCtrlActive" 0 "ASREngCtrlPassiveButInstalled" ;
VAL_ 2348820739 MessageCounter 14 "Reserved" 13 "Reserved" 12 "Reserved" 11 "Reserved" 10 "Reserved" 9 "Reserved" 8 "Reserved" 15 "Not Available" ;
VAL_ 2348820739 ControlPurpose 5 "TemporaryPowerTrainControl" 4 "EngineProtection" 3 "RoadSpeedGovernor" 2 "PTOGovernor" 1 "CruiseControl" 0 "AcceleratorPedal" ;
VAL_ 2348820739 TransmissionRate 7 "UseStandardRate" 6 "25ms" 5 "50ms" 4 "100ms" 3 "250ms" 2 "500ms" 1 "750ms" 0 "1000ms" ;
VAL_ 2348820739 OverrideCtrlModePriority 3 "LowPriority" 2 "MdmPrrtyUsdFrPwrtrnCtrlOprtnsWh" 1 "HighPriority" 0 "HghstPrrtyUsdFrSttnsThtRqrImmdt" ;
VAL_ 2348820739 EngRqedSpeedCtrlConditions 2 "ThsCtrlCndtnHsBnOptmzdTMnmzRpmO" 3 "StbltyOptmzdFrDrvlnEnggdAnd_OrI" 1 "StbltyOptmzdFrDrvlnDsnggdAndNnl" 0 "ThsSpdGvrnrGnSlctnIsAdjstdTPrvd" ;
VAL_ 2348820739 EngOverrideCtrlMode 3 "Spd_TrqLmtCtrlLmtSpdAnd_OrTrqBs" 2 "TrqCtrlCntrlTrqTInclddDsrdTrqVl" 1 "SpdCtrlGvrnSpdTInclddDsrdSpdVle" 0 "OvrrdDsbldDsblAnyExstngCtrlCmdd" ;
VAL_ 2348820739 MessageChecksum 15 "Not Available" ;
VAL_ 2348820739 EngineRequestedTorqueHiRes 15 "Not Available" 14 "Not Available" 13 "Not Available" 12 "Not Available" 11 "Not Available" 10 "Not Available" 9 "Not Available" 8 "Not Available" ;
VAL_ 2348814083 MessageCounter 14 "Reserved" 13 "Reserved" 12 "Reserved" 11 "Reserved" 10 "Reserved" 9 "Reserved" 8 "Reserved" 15 "Not Available" ;
VAL_ 2348814083 ControlPurpose 5 "TemporaryPowerTrainControl" 4 "EngineProtection" 3 "RoadSpeedGovernor" 2 "PTOGovernor" 1 "CruiseControl" 0 "AcceleratorPedal" ;
VAL_ 2348814083 TransmissionRate 7 "UseStandardRate" 6 "25ms" 5 "50ms" 4 "100ms" 3 "250ms" 2 "500ms" 1 "750ms" 0 "1000ms" ;
VAL_ 2348814083 OverrideCtrlModePriority 3 "LowPriority" 2 "MdmPrrtyUsdFrPwrtrnCtrlOprtnsWh" 1 "HighPriority" 0 "HghstPrrtyUsdFrSttnsThtRqrImmdt" ;
VAL_ 2348814083 EngRqedSpeedCtrlConditions 2 "ThsCtrlCndtnHsBnOptmzdTMnmzRpmO" 3 "StbltyOptmzdFrDrvlnEnggdAnd_OrI" 1 "StbltyOptmzdFrDrvlnDsnggdAndNnl" 0 "ThsSpdGvrnrGnSlctnIsAdjstdTPrvd" ;
VAL_ 2348814083 EngOverrideCtrlMode 3 "Spd_TrqLmtCtrlLmtSpdAnd_OrTrqBs" 2 "TrqCtrlCntrlTrqTInclddDsrdTrqVl" 1 "SpdCtrlGvrnSpdTInclddDsrdSpdVle" 0 "OvrrdDsbldDsblAnyExstngCtrlCmdd" ;
VAL_ 2348814083 MessageChecksum 15 "Not Available" ;
VAL_ 2348814083 EngineRequestedTorqueHiRes 15 "Not Available" 14 "Not Available" 13 "Not Available" 12 "Not Available" 11 "Not Available" 10 "Not Available" 9 "Not Available" 8 "Not Available" ;
VAL_ 2348810243 MessageCounter 14 "Reserved" 13 "Reserved" 12 "Reserved" 11 "Reserved" 10 "Reserved" 9 "Reserved" 8 "Reserved" 15 "Not Available" ;
VAL_ 2348810243 ControlPurpose 5 "TemporaryPowerTrainControl" 4 "EngineProtection" 3 "RoadSpeedGovernor" 2 "PTOGovernor" 1 "CruiseControl" 0 "AcceleratorPedal" ;
VAL_ 2348810243 TransmissionRate 7 "UseStandardRate" 6 "25ms" 5 "50ms" 4 "100ms" 3 "250ms" 2 "500ms" 1 "750ms" 0 "1000ms" ;
VAL_ 2348810243 OverrideCtrlModePriority 3 "LowPriority" 2 "MdmPrrtyUsdFrPwrtrnCtrlOprtnsWh" 1 "HighPriority" 0 "HghstPrrtyUsdFrSttnsThtRqrImmdt" ;
VAL_ 2348810243 EngRqedSpeedCtrlConditions 2 "ThsCtrlCndtnHsBnOptmzdTMnmzRpmO" 3 "StbltyOptmzdFrDrvlnEnggdAnd_OrI" 1 "StbltyOptmzdFrDrvlnDsnggdAndNnl" 0 "ThsSpdGvrnrGnSlctnIsAdjstdTPrvd" ;
VAL_ 2348810243 EngOverrideCtrlMode 3 "Spd_TrqLmtCtrlLmtSpdAnd_OrTrqBs" 2 "TrqCtrlCntrlTrqTInclddDsrdTrqVl" 1 "SpdCtrlGvrnSpdTInclddDsrdSpdVle" 0 "OvrrdDsbldDsblAnyExstngCtrlCmdd" ;
VAL_ 2348810243 MessageChecksum 15 "Not Available" ;
VAL_ 2348810243 EngineRequestedTorqueHiRes 15 "Not Available" 14 "Not Available" 13 "Not Available" 12 "Not Available" 11 "Not Available" 10 "Not Available" 9 "Not Available" 8 "Not Available" ;
VAL_ 2297441790 SpprtVrblTrnsRpttnRtFrAcclrtnSns 1 "MsTransRate" ;
VAL_ 2297441790 VrtclAcclrtnExRngeFigureOfMerit 3 "NotAvailable" 2 "Error" 1 "VrtclcclrtnIsDgrddDtIsSspctDTEn" 0 "VrtclAcclrtnIsFllyFnctnlDtIsWth" ;
VAL_ 2297441790 LngtdnlAcclrtnExRngFgureOfMerit 3 "NotAvailable" 2 "Error" 1 "LngtdnlAcclrtnIsDgrddDtIsSspctD" 0 "LngtdnlAcclrtnIsFllyFnctnlDtIsW" ;
VAL_ 2297441790 LtrlAcclrtnExRangeFigureOfMerit 3 "NotAvailable" 2 "Error" 1 "LtrlAcclrtnIsDgrddDtIsSspctDTEn" 0 "LtrlAcclrtnIsFllyFnctnlDtIsWthn" ;
VAL_ 2364549630 RollAngleExRangeFigureOfMerit 3 "NotAvailable" 2 "Error" 1 "RllRtDgrddDtIsSspctDTEnvrnmntlC" 0 "RllRtFllyFnctnlDtIsWthnSnsrSpcf" ;
VAL_ 2364549630 RollAngleExRangeCompensation 3 "NotAvailable" 2 "Error" 1 "Off" 0 "On" ;
VAL_ 2364549630 PitchAngleExRangeFigureOfMerit 3 "NotAvailable" 2 "Error" 1 "PtchRtDgrddDtIsSspctDTEnvrnmntl" 0 "PtchRtFllyFnctnlDtIsWthnSnsrSpc" ;
VAL_ 2364549630 PitchAngleExRangeCompensation 3 "NotAvailable" 2 "Error" 1 "Off" 0 "On" ;
VAL_ 2499614462 OccpntClssfcationSystem10Status 3 "NotAvailable" 2 "ErrrClssfctonCannotBeDetermined" 1 "Occupied" 0 "Empty" ;
VAL_ 2499614462 OccpntClssficationSystem9Status 3 "NotAvailable" 2 "ErrrClssfctonCannotBeDetermined" 1 "Occupied" 0 "Empty" ;
VAL_ 2499614462 OccpntClssficationSystem8Status 3 "NotAvailable" 2 "ErrrClssfctonCannotBeDetermined" 1 "Occupied" 0 "Empty" ;
VAL_ 2499614462 OccpntClssficationSystem7Status 3 "NotAvailable" 2 "ErrrClssfctonCannotBeDetermined" 1 "Occupied" 0 "Empty" ;
VAL_ 2499614462 OccpntClssficationSystem6Status 3 "NotAvailable" 2 "ErrrClssfctonCannotBeDetermined" 1 "Occupied" 0 "Empty" ;
VAL_ 2499614462 OccpntClssficationSystem5Status 3 "NotAvailable" 2 "ErrrClssfctonCannotBeDetermined" 1 "Occupied" 0 "Empty" ;
VAL_ 2499614462 OccpntClssficationSystem4Status 3 "NotAvailable" 2 "ErrrClssfctonCannotBeDetermined" 1 "Occupied" 0 "Empty" ;
VAL_ 2499614462 OccpntClssficationSystem3Status 3 "NotAvailable" 2 "ErrrClssfctonCannotBeDetermined" 1 "Occupied" 0 "Empty" ;
VAL_ 2499614462 PssngrOccpntClssfctnSystmStatus 7 "NotAvailable" 5 "ErrrClssfctnOfOccpntCnntBDtrmnd" 3 "Adult" 4 "LargeAdult" 2 "SmallAdult" 1 "Child" 0 "Empty" ;
VAL_ 2499614462 DrvrOccpntClssfctonSystemStatus 7 "NotAvailable" 6 "ErrrClssfctnOfOccpntCnntBDtrmnd" 5 "Reserved" 4 "LargeAdult" 3 "Adult" 2 "SmallAdult" 1 "Child" 0 "Empty" ;
VAL_ 2560098046 CabNoiseCtrlTuningStatus 15 "NotAvailable_NotTuning_NotRqed" 14 "TuningModeError" 10 "AutomaticTuningModeSavingData" 9 "AutomaticTuningModeCmdComplete" 8 "AutomaticTuningMode" 7 "MnlTnngDndRqrsScrtyVerification" 13 "Reserved" 2 "ManualTuningModeSavingData" 1 "ManualTuningModeCmdComplete" 0 "ManualTuningMode" ;
VAL_ 2560098046 CabNoiseCtrlStatus 3 "NotAvailable_NotRqed" 2 "ErrorIndicator" 1 "CabNoiseCtrlSystemOFFLine" 0 "CabNoiseCtrlSystemONLine" ;
VAL_ 2560163582 CabNoiseCtrlTuningState 7 "DontCareNOTCmded" 6 "Reserved" 5 "ExitTuningSavingParameters" 4 "ExitTuningNotSavingParameters" 3 "RmnInTningSaveCurrentParameters" 2 "ActvtAtmtcTnngSttSvngPrmtrsExtO" 1 "ActvtAtmtcTnngWtFrSvAndExitCmds" 0 "ActvtMnlTnngWtFrSaveAndExitCmds" ;
VAL_ 2560163582 CabNoiseCtrlState 3 "DontCare_NotCmded" 2 "Reserved" 1 "BringCabNoiseCtrlSystemOnLine" 0 "TakeCabNoiseCtrlSystemOffLine" ;
VAL_ 2297441534 DropRelayCtrl 3 "TakeNoAction" 2 "Reserved" 1 "OnEnableDropRelayRq" 0 "OffDisableDropRelayRq" ;
VAL_ 2297441534 LiftRelayCtrl 3 "TakeNoAction" 2 "Reserved" 1 "OnEnableLiftRelayRq" 0 "OffDisableLiftRelayRq" ;
VAL_ 2297441534 MaterialDropActiveStatus 3 "NotAvailable" 2 "Error" 1 "On" 0 "Off" ;
VAL_ 2297441534 MaterialLiftActiveStatus 3 "NotAvailable" 2 "Error" 1 "On" 0 "Off" ;
VAL_ 2297441534 GnratorCurrentBoostActiveStatus 3 "NotAvailable" 2 "Error" 1 "On" 0 "Off" ;
VAL_ 2297441534 MaterialDropSwitch 3 "NotAvailable" 2 "Error" 1 "Drop" 0 "DontDrop" ;
VAL_ 2297441534 MaterialLiftSwitch 3 "NotAvailable" 2 "Error" 1 "Lift" 0 "DontLift" ;
VAL_ 2566722302 GneratorDutyCycleExceededStatus 3 "NotAvaiable" 2 "Error" 1 "DutyCycleExceed" 0 "DutyCycleNotExceed" ;
VAL_ 2566722302 VoltageMonitorActiveStatus 3 "NotAvailable" 2 "Error" 1 "MonitorIsOn" 0 "MonitorIsOff" ;
VAL_ 2566722302 GensetEnableActiveStatus 3 "NotAvaialble" 2 "Error" 1 "Enabled" 0 "NotEnabled" ;
VAL_ 2566722302 ReverseCurrentRangeSetting 31 "NotAvailable" 30 "Error" 16 "11101NotUsed" 15 "16" 14 "15" 13 "14" 12 "13" 11 "12" 10 "11" 9 "10" 8 "9" 7 "8" 6 "7" 5 "6" 4 "5" 3 "4" 2 "3" 1 "2" 0 "1" ;
VAL_ 2566722302 GensetSoftstartActiveStatus 3 "NotAvailable" 2 "Error" 1 "On" 0 "Off" ;
VAL_ 2566722302 Grapple_MagnetSelectionSwitch 3 "NotAvailable" 2 "Error" 1 "MagnetSelected" 0 "GrappleSelected" ;
VAL_ 2566722302 GnstSystmOtptVoltageRangeStatus 3 "NotAvailable" 2 "Error" 1 "InRange" 0 "OutOfRange" ;
VAL_ 2566722302 GeneratorOverheatStatus 3 "NotAvailable" 2 "Error" 1 "Overheat" 0 "NotOverheat" ;
VAL_ 2560032510 LwVltgDscnnctDsredOperatingMode 15 "NoChange" 6 "1110Reserved" 5 "ManualConnect" 4 "ManualDisconnect" 1 "0011Reserved" 0 "Automatic" ;
VAL_ 2566717950 LwVltgDisconnectVoutOutputState 15 "NotAvailableNotInstalled" 14 "OutputFault" 5 "1101Reserved" 4 "ConnectPendingAlarmActive" 3 "DisconnectPendingAlarmActive" 2 "DscnnctAlrmExprdOtptOffDscnnctd" 1 "OutputOnConnected" 0 "OutputOffDisconnected" ;
VAL_ 2566717950 LwVoltageDisconnectOutput1State 15 "NotAvailableNotInstalled" 14 "OutputFault" 5 "1101Reserved" 4 "ConnectPendingAlarmActive" 3 "DisconnectPendingAlarmActive" 2 "DscnnctAlrmExprdOtptOffDscnnctd" 1 "OutputOnConnected" 0 "OutputOffDisconnected" ;
VAL_ 2566717950 LwVoltageDisconnectOutput2State 15 "NotAvailableNotInstalled" 14 "OutputFault" 5 "1101Reserved" 4 "ConnectPendingAlarmActive" 3 "DisconnectPendingAlarmActive" 2 "DscnnctAlrmExprdOtptOffDscnnctd" 1 "OutputOnConnected" 0 "OutputOffDisconnected" ;
VAL_ 2566717950 LwVoltageDisconnectOutput3State 15 "NotAvailableNotInstalled" 14 "OutputFault" 5 "1101Reserved" 4 "ConnectPendingAlarmActive" 3 "DisconnectPendingAlarmActive" 2 "DscnnctAlrmExprdOtptOffDscnnctd" 1 "OutputOnConnected" 0 "OutputOffDisconnected" ;
VAL_ 2566717950 LwVltgDscnnctCrrntOperatingMode 15 "NotAvailable" 10 "1110Reserved" 9 "ManualConnectViaHardwiredInput" 8 "MnalDisconnectViaHardwiredInput" 6 "0111Reserved" 5 "ManualConnectViaJ1939Rq" 4 "ManualDisconnectViaJ1939Rq" 1 "0011Reserved" 0 "Automatic" ;
VAL_ 2566717950 LwVltgDscnnctManualConnectState 3 "NotInstalled" 2 "Error" 1 "InputOn" 0 "InputOff" ;
VAL_ 2566717950 LwVltgDscnnctMnlDisconnectState 3 "NotInstalled" 2 "Error" 1 "InputOn" 0 "InputOff" ;
VAL_ 2358902526 Joystick3Lamp10Cmd 3 "NotAvailableNotInstalled" 2 "Blinking" 1 "On" 0 "Off" ;
VAL_ 2358902526 Joystick3Lamp9Cmd 3 "NotAvailableNotInstalled" 2 "Blinking" 1 "On" 0 "Off" ;
VAL_ 2358902526 Joystick3Lamp8Cmd 3 "NotAvailableNotInstalled" 2 "Blinking" 1 "On" 0 "Off" ;
VAL_ 2358902526 Joystick3Lamp7Cmd 3 "NotAvailableNotInstalled" 2 "Blinking" 1 "On" 0 "Off" ;
VAL_ 2358902526 Joystick3Lamp6Cmd 3 "NotAvailableNotInstalled" 2 "Blinking" 1 "On" 0 "Off" ;
VAL_ 2358902526 Joystick3Lamp5Cmd 3 "NotAvailableNotInstalled" 2 "Blinking" 1 "On" 0 "Off" ;
VAL_ 2358902526 Joystick3Lamp4Cmd 3 "NotAvailableNotInstalled" 2 "Blinking" 1 "On" 0 "Off" ;
VAL_ 2358902526 Joystick3Lamp3Cmd 3 "NotAvailableNotInstalled" 2 "Blinking" 1 "On" 0 "Off" ;
VAL_ 2358902526 Joystick3Lamp2Cmd 3 "NotAvailableNotInstalled" 2 "Blinking" 1 "On" 0 "Off" ;
VAL_ 2358902526 Joystick3Lamp1Cmd 3 "NotAvailableNotInstalled" 2 "Blinking" 1 "On" 0 "Off" ;
VAL_ 2358902526 Joystick2Lamp10Cmd 3 "NotAvailableNotInstalled" 2 "Blinking" 1 "On" 0 "Off" ;
VAL_ 2358902526 Joystick2Lamp9Cmd 3 "NotAvailableNotInstalled" 2 "Blinking" 1 "On" 0 "Off" ;
VAL_ 2358902526 Joystick2Lamp8Cmd 3 "NotAvailableNotInstalled" 2 "Blinking" 1 "On" 0 "Off" ;
VAL_ 2358902526 Joystick2Lamp7Cmd 3 "NotAvailableNotInstalled" 2 "Blinking" 1 "On" 0 "Off" ;
VAL_ 2358902526 Joystick2Lamp6Cmd 3 "NotAvailableNotInstalled" 2 "Blinking" 1 "On" 0 "Off" ;
VAL_ 2358902526 Joystick2Lamp5Cmd 3 "NotAvailableNotInstalled" 2 "Blinking" 1 "On" 0 "Off" ;
VAL_ 2358902526 Joystick2Lamp4Cmd 3 "NotAvailableNotInstalled" 2 "Blinking" 1 "On" 0 "Off" ;
VAL_ 2358902526 Joystick2Lamp3Cmd 3 "NotAvailableNotInstalled" 2 "Blinking" 1 "On" 0 "Off" ;
VAL_ 2358902526 Joystick2Lamp2Cmd 3 "NotAvailableNotInstalled" 2 "Blinking" 1 "On" 0 "Off" ;
VAL_ 2358902526 Joystick2Lamp1Cmd 3 "NotAvailableNotInstalled" 2 "Blinking" 1 "On" 0 "Off" ;
VAL_ 2358902526 Joystick1Lamp10Cmd 3 "NotAvailableNotInstalled" 2 "Blinking" 1 "On" 0 "Off" ;
VAL_ 2358902526 Joystick1Lamp9Cmd 3 "NotAvailableNotInstalled" 2 "Blinking" 1 "On" 0 "Off" ;
VAL_ 2358902526 Joystick1Lamp8Cmd 3 "NotAvailableNotInstalled" 2 "Blinking" 1 "On" 0 "Off" ;
VAL_ 2358902526 Joystick1Lamp7Cmd 3 "NotAvailableNotInstalled" 2 "Blinking" 1 "On" 0 "Off" ;
VAL_ 2358902526 Joystick1Lamp6Cmd 3 "NotAvailableNotInstalled" 2 "Blinking" 1 "On" 0 "Off" ;
VAL_ 2358902526 Joystick1Lamp5Cmd 3 "NotAvailableNotInstalled" 2 "Blinking" 1 "On" 0 "Off" ;
VAL_ 2358902526 Joystick1Lamp4Cmd 3 "NotAvailableNotInstalled" 2 "Blinking" 1 "On" 0 "Off" ;
VAL_ 2358902526 Joystick1Lamp3Cmd 3 "NotAvailableNotInstalled" 2 "Blinking" 1 "On" 0 "Off" ;
VAL_ 2358902526 Joystick1Lamp2Cmd 3 "NotAvailableNotInstalled" 2 "Blinking" 1 "On" 0 "Off" ;
VAL_ 2358902526 Joystick1Lamp1Cmd 3 "NotAvailableNotInstalled" 2 "Blinking" 1 "On" 0 "Off" ;
VAL_ 2566711550 IntkVlvActtnSystmOlPrss2SlndCtrl 3 "notAvailable" 2 "reservedForSAEAssignment" 1 "on" 0 "off" ;
VAL_ 2566711550 IntkVlvActtnSystmOlPrss1SlndCtrl 3 "notAvailable" 2 "reservedForSAEAssignment" 1 "on" 0 "off" ;
